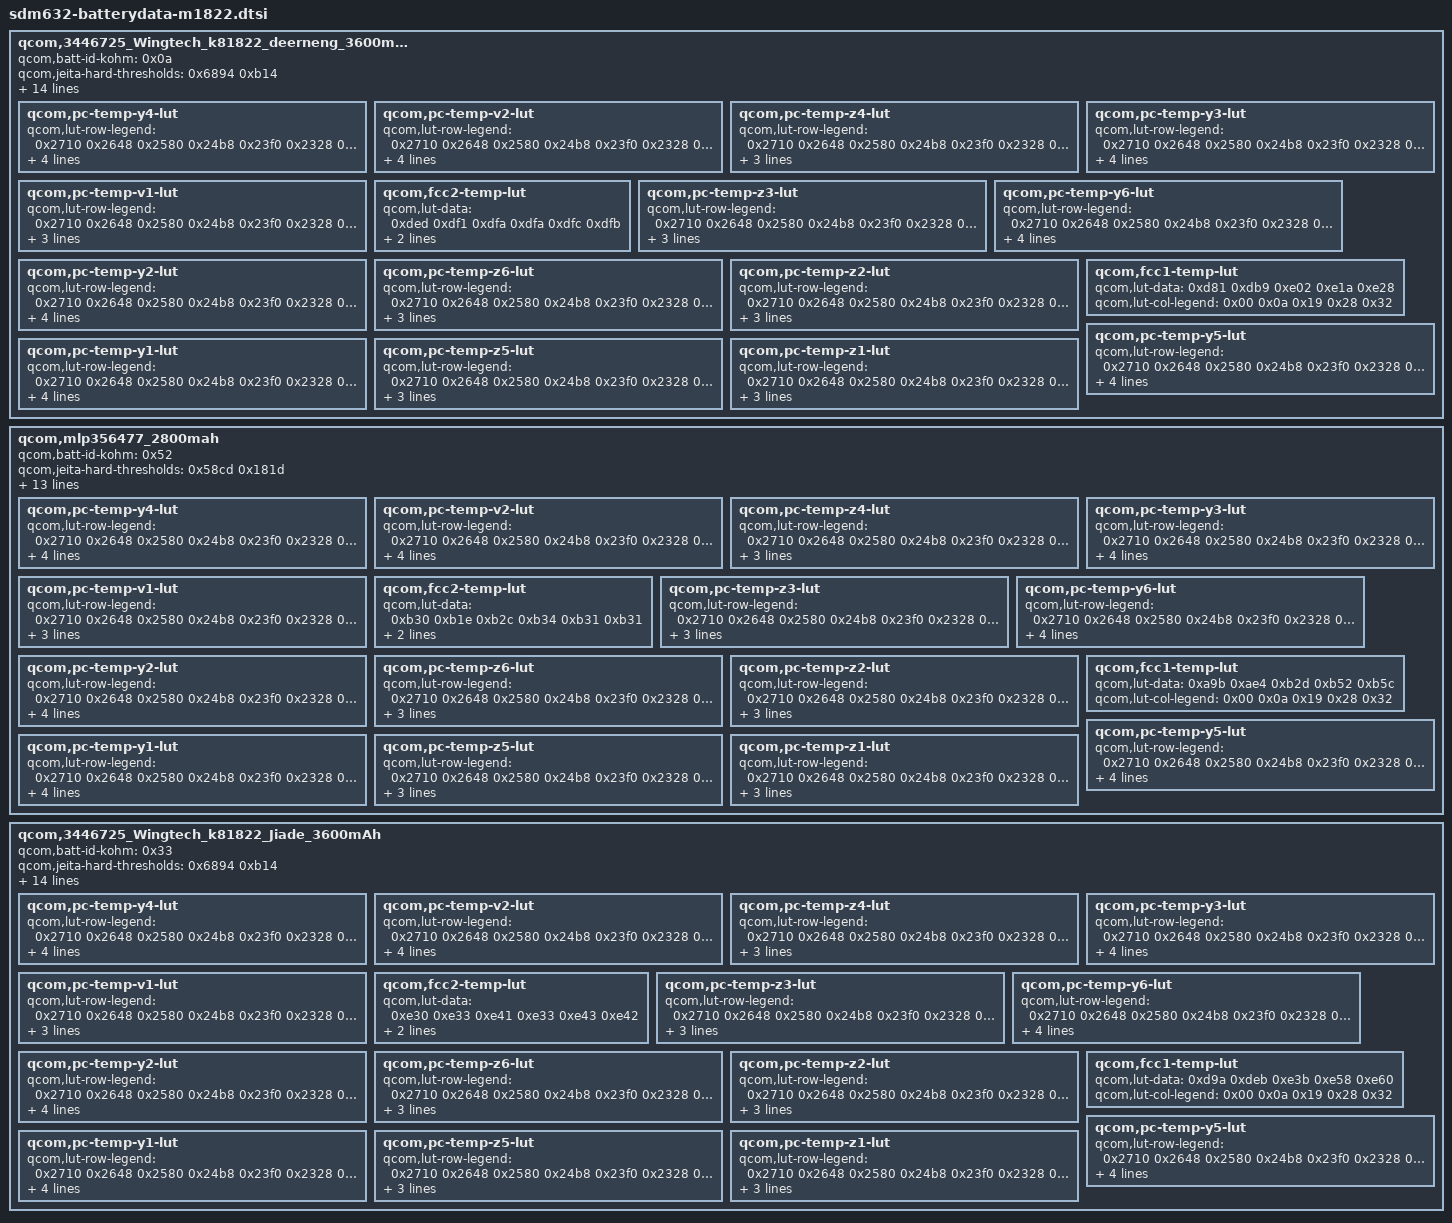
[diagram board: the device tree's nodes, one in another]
/* Copyright (c) 2021, MeizuCustoms
 *
 * This program is free software; you can redistribute it and/or modify
 * it under the terms of the GNU General Public License version 2 and
 * only version 2 as published by the Free Software Foundation.
 *
 * This program is distributed in the hope that it will be useful,
 * but WITHOUT ANY WARRANTY; without even the implied warranty of
 * MERCHANTABILITY or FITNESS FOR A PARTICULAR PURPOSE.  See the
 * GNU General Public License for more details.
 */

qcom,3446725_Wingtech_k81822_deerneng_3600mAh {
    qcom,batt-id-kohm = <0x0a>;
    qcom,jeita-hard-thresholds = <0x6894 0xb14>;
    qcom,step-chg-ranges = <0x33e140 0x401640 0x2625a0 0x401a28 0x419ce0 0x1b7740 0x41a0c8 0x432380 0x124f80>;
    qcom,fastchg-current-ma = <0xe10>;
    qcom,max-voltage-uv = <0x432380>;
    qcom,qg-batt-profile-ver = <0x64>;
    qcom,battery-therm-kohm = <0x64>;
    qcom,battery-beta = <0x109a>;
    qcom,jeita-fcc-ranges = <0x00 0x64 0xafc80 0x65 0x96 0x107ac0 0x97 0x1c2 0x2625a0>;
    qcom,battery-type = "k81822_mtp_deerneng_4V4_3600mAh";
    qcom,fg-cc-cv-threshold-uv = <0x42fc70>;
    qcom,jeita-fv-ranges = <0x00 0x64 0x432380 0x65 0x1c2 0x432380 0x1c3 0x226 0x432380>;

    qcom,pc-temp-y4-lut {
        qcom,lut-row-legend = <0x2710 0x2648 0x2580 0x24b8 0x23f0 0x2328 0x2260 0x2198 0x20d0 0x2008 0x1f40 0x1e78 0x1db0 0x1ce8 0x1c20 0x1b58 0x1a90 0x19c8 0x1900 0x1838 0x1770 0x16a8 0x15e0 0x1518 0x1450 0x1388 0x12c0 0x11f8 0x1130 0x1068 0xfa0 0xed8 0xe10 0xd48 0xc80 0xbb8 0xaf0 0xa28 0x960 0x898 0x7d0 0x708 0x640 0x578 0x4b0 0x3e8 0x384 0x320 0x2bc 0x258 0x1f4 0x190 0x12c 0xc8 0x64 0x00>;
        qcom,lut-data = <0x4242 0x4165 0x40fc 0x407f 0x405c 0x404e 0x4267 0x419b 0x410f 0x407f 0x4058 0x404d 0x429d 0x41dc 0x4120 0x407e 0x4055 0x404b 0x42d5 0x421b 0x412e 0x407e 0x4054 0x404b 0x4302 0x424b 0x4137 0x407e 0x4053 0x404a 0x4316 0x425f 0x413b 0x407f 0x4052 0x404a 0x4312 0x4259 0x4137 0x4080 0x4053 0x404a 0x430a 0x424b 0x4130 0x4083 0x4055 0x404b 0x4308 0x423d 0x412e 0x4087 0x4056 0x404c 0x431a 0x422a 0x412e 0x408f 0x405a 0x404e 0x433b 0x421f 0x412e 0x4098 0x405e 0x4050 0x43b7 0x4261 0x4133 0x409e 0x4064 0x4054 0x4470 0x42df 0x4140 0x40a4 0x406b 0x4058 0x4483 0x42fe 0x4156 0x40ac 0x4070 0x405e 0x438b 0x42e1 0x4190 0x40ba 0x4074 0x4065 0x4292 0x42bc 0x41b7 0x40cc 0x4079 0x406d 0x423b 0x428c 0x41b7 0x40e4 0x4085 0x4073 0x4201 0x4243 0x41b4 0x4100 0x4099 0x4079 0x41d9 0x420c 0x41ab 0x4116 0x40af 0x4085 0x41b6 0x41dc 0x417e 0x4129 0x40cb 0x40a0 0x4197 0x41aa 0x4146 0x4133 0x40dc 0x40b2 0x4178 0x4176 0x4112 0x4108 0x40c2 0x40a0 0x4157 0x4142 0x40df 0x40ae 0x408b 0x407a 0x4154 0x4115 0x40c4 0x4086 0x406e 0x4063 0x4184 0x40e8 0x40b5 0x4077 0x405f 0x4056 0x41ae 0x40cc 0x40ab 0x4070 0x4058 0x404f 0x41af 0x40e8 0x40a7 0x4073 0x405a 0x4051 0x41ae 0x412f 0x40a4 0x4079 0x4062 0x4055 0x41ac 0x4151 0x40a0 0x407f 0x406a 0x405b 0x41a7 0x4159 0x409d 0x4086 0x4074 0x4066 0x41a3 0x415d 0x4099 0x408d 0x407f 0x4073 0x41a0 0x4153 0x4094 0x4095 0x408b 0x4080 0x41a0 0x412f 0x4090 0x409d 0x4097 0x408c 0x41a1 0x411a 0x408f 0x40a1 0x409a 0x4090 0x41a6 0x4123 0x4097 0x40a2 0x4097 0x408c 0x41ab 0x4138 0x40a3 0x40a2 0x4091 0x4086 0x41ae 0x414a 0x40b2 0x409d 0x4082 0x4078 0x41b1 0x4160 0x40c4 0x408e 0x406b 0x4063 0x41b1 0x4167 0x40d1 0x4086 0x4063 0x405c 0x41a7 0x4166 0x40da 0x4083 0x4064 0x405c 0x4196 0x4162 0x40df 0x4082 0x4066 0x405d 0x418b 0x415a 0x40dd 0x4085 0x4067 0x405c 0x4184 0x4148 0x40d8 0x408a 0x4066 0x405a 0x4186 0x4137 0x40cb 0x4083 0x4059 0x404f 0x4195 0x412f 0x40c1 0x407d 0x4050 0x4047 0x41b0 0x4136 0x40c8 0x4082 0x405b 0x4053 0x419f 0x4139 0x40ce 0x4086 0x4067 0x4065 0x41b0 0x414c 0x40e7 0x4098 0x4078 0x4081 0x41c9 0x4171 0x4105 0x40ad 0x4095 0x409e 0x41cc 0x4195 0x4127 0x40bf 0x4095 0x4082 0x41b6 0x418c 0x4116 0x4091 0x405b 0x404e 0x41a5 0x416e 0x4122 0x4090 0x405b 0x4051 0x41b6 0x416e 0x413b 0x40af 0x406a 0x405d 0x423b 0x417e 0x416a 0x40f5 0x40a0 0x40a3 0x423b 0x417e 0x416a 0x40f5 0x40a0 0x40a3 0x423b 0x417e 0x416a 0x40f5 0x40a0 0x40a3>;
        qcom,lut-col-legend = <0xfffffff6 0x00 0x0a 0x19 0x28 0x32>;
    };

    qcom,pc-temp-v2-lut {
        qcom,lut-row-legend = <0x2710 0x2648 0x2580 0x24b8 0x23f0 0x2328 0x2260 0x2198 0x20d0 0x2008 0x1f40 0x1e78 0x1db0 0x1ce8 0x1c20 0x1b58 0x1a90 0x19c8 0x1900 0x1838 0x1770 0x16a8 0x15e0 0x1518 0x1450 0x1388 0x12c0 0x11f8 0x1130 0x1068 0xfa0 0xed8 0xe10 0xd48 0xc80 0xbb8 0xaf0 0xa28 0x960 0x898 0x7d0 0x708 0x640 0x578 0x4b0 0x3e8 0x384 0x320 0x2bc 0x258 0x1f4 0x190 0x12c 0xc8 0x64 0x00>;
        qcom,lut-data = <0xab86 0xab6d 0xab59 0xab2c 0xab13 0xab04 0xaa0f 0xaa35 0xaa4c 0xaa1f 0xaa13 0xaa07 0xa8bd 0xa910 0xa946 0xa91b 0xa919 0xa910 0xa798 0xa802 0xa84b 0xa822 0xa826 0xa820 0xa69a 0xa70a 0xa758 0xa734 0xa73b 0xa737 0xa5a8 0xa618 0xa668 0xa648 0xa651 0xa64e 0xa4b6 0xa51f 0xa578 0xa55c 0xa567 0xa565 0xa3c7 0xa429 0xa48a 0xa472 0xa47d 0xa47b 0xa2cb 0xa343 0xa3a1 0xa38b 0xa396 0xa395 0xa1ae 0xa26c 0xa2bc 0xa2a6 0xa2b2 0xa2b1 0xa0ce 0xa199 0xa1da 0xa1c4 0xa1d0 0xa1d0 0xa063 0xa0c0 0xa0fd 0xa0e8 0xa0f4 0xa0f4 0xa014 0x9fe8 0xa023 0xa010 0xa01a 0xa01a 0x9f7f 0x9f1e 0x9f55 0x9f41 0x9f4a 0x9f49 0x9e2a 0x9e63 0x9e8f 0x9e76 0x9e7e 0x9e7c 0x9cba 0x9da0 0x9dcf 0x9db2 0x9dba 0x9db6 0x9bb1 0x9cc0 0x9d13 0x9cf2 0x9cfc 0x9cfa 0x9ac9 0x9bd0 0x9c59 0x9c3a 0x9c45 0x9c45 0x99f6 0x9aec 0x9b8f 0x9b8d 0x9b96 0x9b96 0x9933 0x9a0e 0x9ab0 0x9af4 0x9af5 0x9af4 0x9879 0x9937 0x99d2 0x9a4c 0x9a49 0x9a47 0x97b8 0x986d 0x98fe 0x9968 0x996c 0x996c 0x96fa 0x97af 0x9834 0x9866 0x987a 0x987d 0x9661 0x9706 0x9788 0x97a0 0x97b9 0x97bd 0x95e6 0x966c 0x96f6 0x9709 0x971e 0x9724 0x9582 0x95e5 0x9675 0x9688 0x969a 0x969f 0x9539 0x956f 0x9600 0x9617 0x9627 0x962b 0x94ff 0x9508 0x9596 0x95b3 0x95c1 0x95c5 0x94ca 0x94bd 0x9536 0x9557 0x9565 0x9567 0x949b 0x9488 0x94dd 0x9501 0x9510 0x950e 0x946d 0x945c 0x948c 0x94b3 0x94c3 0x94be 0x943d 0x9430 0x9441 0x946a 0x947d 0x9477 0x940c 0x9408 0x93fd 0x9428 0x943d 0x9435 0x93d9 0x93df 0x93c7 0x93ea 0x93fa 0x93f0 0x93a5 0x93b4 0x93a1 0x93b4 0x93b4 0x93a6 0x936f 0x9389 0x937c 0x937d 0x9369 0x9353 0x9334 0x935a 0x9357 0x9340 0x9311 0x92f0 0x92f7 0x9329 0x9331 0x92ff 0x92af 0x927e 0x92b0 0x92ec 0x92ff 0x92b7 0x9254 0x9219 0x925b 0x929e 0x92b6 0x9268 0x9205 0x91c6 0x91fc 0x9240 0x925a 0x920f 0x91b1 0x9171 0x9196 0x91d0 0x91e6 0x91a4 0x9149 0x9108 0x912a 0x914a 0x915b 0x9126 0x90d0 0x908f 0x90d1 0x90c2 0x90c5 0x9092 0x9044 0x9004 0x9085 0x9044 0x9048 0x901f 0x8fde 0x8fa3 0x903b 0x8ff6 0x9002 0x8ff6 0x8fbc 0x8f87 0x9019 0x8fdb 0x8fef 0x8fe7 0x8fac 0x8f77 0x8feb 0x8fbb 0x8fd3 0x8fd3 0x8f9c 0x8f67 0x8fa3 0x8f86 0x8fad 0x8fb0 0x8f7a 0x8f40 0x8f04 0x8f1c 0x8f49 0x8f4a 0x8f01 0x8e9f 0x8dc4 0x8e16 0x8e1e 0x8e05 0x8d92 0x8d18 0x8bcb 0x8c3d 0x8c0b 0x8c05 0x8b91 0x8b0c 0x891d 0x899f 0x8970 0x897d 0x88fb 0x885c 0x8589 0x85e4 0x85ce 0x860e 0x856c 0x84b8 0x8047 0x80cd 0x80af 0x80d5 0x804e 0x7f84 0x6be0 0x6af3 0x6da1 0x6c3e 0x6e30 0x6c8f>;
        qcom,lut-col-legend = <0xfffffff6 0x00 0x0a 0x19 0x28 0x32>;
    };

    qcom,pc-temp-z4-lut {
        qcom,lut-row-legend = <0x2710 0x2648 0x2580 0x24b8 0x23f0 0x2328 0x2260 0x2198 0x20d0 0x2008 0x1f40 0x1e78 0x1db0 0x1ce8 0x1c20 0x1b58 0x1a90 0x19c8 0x1900 0x1838 0x1770 0x16a8 0x15e0 0x1518 0x1450 0x1388 0x12c0 0x11f8 0x1130 0x1068 0xfa0 0xed8 0xe10 0xd48 0xc80 0xbb8 0xaf0 0xa28 0x960 0x898 0x7d0 0x708 0x640 0x578 0x4b0 0x3e8 0x384 0x320 0x2bc 0x258 0x1f4 0x190 0x12c 0xc8 0x64 0x00>;
        qcom,lut-data = <0x3de7 0x3c92 0x3b14 0x3a86 0x3a1d 0x3e4f 0x3cb5 0x3b3e 0x3a8d 0x3a51 0x3dc2 0x3c83 0x3b28 0x3a7a 0x3a41 0x3d09 0x3be4 0x3afd 0x3a5f 0x3a2c 0x3c75 0x3b54 0x3ab2 0x3a35 0x3a0c 0x3be7 0x3afa 0x3a73 0x3a0c 0x39ea 0x3b7c 0x3ab1 0x3a44 0x39ee 0x39ce 0x3b2e 0x3a78 0x3a1d 0x39d3 0x39b6 0x3aef 0x3a4b 0x39fd 0x39be 0x39a5 0x3ab9 0x3a25 0x39e4 0x39af 0x399a 0x3a89 0x3a06 0x39d2 0x39a4 0x3992 0x3a67 0x39ed 0x39c6 0x399e 0x398f 0x3a52 0x39d7 0x39bb 0x399a 0x398c 0x3a42 0x39be 0x39b0 0x3993 0x3989 0x3a30 0x39ac 0x39a5 0x3984 0x397f 0x3a18 0x39ad 0x399c 0x3978 0x3974 0x3a06 0x39b6 0x3994 0x3975 0x396d 0x3a00 0x39b7 0x398c 0x3974 0x3968 0x39fe 0x39a7 0x3983 0x3970 0x3962 0x39f9 0x3998 0x397b 0x3969 0x395b 0x39e0 0x399a 0x3978 0x3964 0x3956 0x39c5 0x39a5 0x3999 0x397e 0x396d 0x39ca 0x39b8 0x39d6 0x39c1 0x39b1 0x39f0 0x3a09 0x3a09 0x39f3 0x39e4 0x3a15 0x3a61 0x3a3d 0x3a1c 0x3a08 0x3a2f 0x3a68 0x3a52 0x3a30 0x3a1b 0x3a44 0x3a55 0x3a4d 0x3a29 0x39fd 0x3a46 0x3a3d 0x3a40 0x3a13 0x39b0 0x3a35 0x3a26 0x3a2a 0x39f1 0x3987 0x3a1e 0x3a0d 0x39fa 0x39af 0x3979 0x3a0d 0x39f4 0x39cf 0x397f 0x3970 0x39fb 0x39d9 0x39b2 0x3978 0x3969 0x39ea 0x39c4 0x399c 0x3974 0x3964 0x39db 0x39b7 0x3995 0x3971 0x3963 0x39cd 0x39ad 0x3991 0x396f 0x3963 0x39c0 0x39a5 0x3990 0x396e 0x3963 0x39b5 0x399e 0x3990 0x3970 0x3966 0x39ac 0x399a 0x3990 0x3975 0x396c 0x39a7 0x399d 0x3994 0x397c 0x3974 0x39a2 0x39a7 0x39a4 0x398a 0x397e 0x39a1 0x39aa 0x39af 0x3993 0x3984 0x39a0 0x399e 0x39a4 0x398c 0x3979 0x39a0 0x3994 0x3998 0x3983 0x396b 0x399f 0x3990 0x3995 0x3985 0x3971 0x3994 0x397b 0x3983 0x397d 0x396d 0x39c4 0x396d 0x396a 0x396c 0x3961 0x3a15 0x396d 0x3964 0x3960 0x395a 0x3a3e 0x397e 0x395a 0x3950 0x3946 0x3a41 0x39a2 0x3951 0x393b 0x3938 0x3a3f 0x3980 0x395c 0x3946 0x393c 0x3a34 0x39aa 0x399b 0x3954 0x3941 0x3a46 0x39c9 0x39a8 0x3953 0x393e 0x3a4e 0x39f3 0x399f 0x395a 0x3940 0x3a59 0x39fc 0x39a8 0x3956 0x3942 0x3a59 0x39fc 0x39a8 0x3956 0x3942 0x3a59 0x39fc 0x39a8 0x3956 0x3942>;
        qcom,lut-col-legend = <0x00 0x0a 0x19 0x28 0x32>;
    };

    qcom,pc-temp-y3-lut {
        qcom,lut-row-legend = <0x2710 0x2648 0x2580 0x24b8 0x23f0 0x2328 0x2260 0x2198 0x20d0 0x2008 0x1f40 0x1e78 0x1db0 0x1ce8 0x1c20 0x1b58 0x1a90 0x19c8 0x1900 0x1838 0x1770 0x16a8 0x15e0 0x1518 0x1450 0x1388 0x12c0 0x11f8 0x1130 0x1068 0xfa0 0xed8 0xe10 0xd48 0xc80 0xbb8 0xaf0 0xa28 0x960 0x898 0x7d0 0x708 0x640 0x578 0x4b0 0x3e8 0x384 0x320 0x2bc 0x258 0x1f4 0x190 0x12c 0xc8 0x64 0x00>;
        qcom,lut-data = <0x356d 0x3495 0x341f 0x33ef 0x33df 0x33df 0x356b 0x3497 0x3423 0x33f0 0x33e1 0x33df 0x3566 0x349a 0x3428 0x33f2 0x33e2 0x33e0 0x355e 0x349c 0x342c 0x33f3 0x33e4 0x33e1 0x3555 0x349d 0x3430 0x33f5 0x33e5 0x33e1 0x354b 0x349e 0x3433 0x33f6 0x33e7 0x33e2 0x3540 0x349d 0x3435 0x33f8 0x33e8 0x33e4 0x3532 0x349d 0x3436 0x33f9 0x33e9 0x33e5 0x351f 0x349f 0x3437 0x33fa 0x33eb 0x33e6 0x34f8 0x34b0 0x3439 0x33f9 0x33ec 0x33e8 0x34d6 0x34bc 0x343b 0x33f9 0x33ed 0x33e9 0x34bf 0x34a1 0x343a 0x33fb 0x33ee 0x33ea 0x34a8 0x346d 0x3438 0x33fe 0x33ee 0x33eb 0x34a5 0x3460 0x3435 0x33ff 0x33f0 0x33eb 0x34ad 0x346b 0x342d 0x3400 0x33f4 0x33eb 0x34b3 0x3475 0x3428 0x3400 0x33f6 0x33ec 0x34ab 0x3472 0x342a 0x33fe 0x33f5 0x33ee 0x3497 0x3469 0x342d 0x33fb 0x33f3 0x33f1 0x3489 0x3460 0x342e 0x33fb 0x33f2 0x33f1 0x3480 0x3456 0x3428 0x33fe 0x33f2 0x33f1 0x3479 0x344b 0x3421 0x3401 0x33f2 0x33ef 0x3472 0x3443 0x341c 0x33fe 0x33ef 0x33eb 0x346b 0x343d 0x3417 0x33f6 0x33e9 0x33e4 0x345d 0x3438 0x3414 0x33f2 0x33e5 0x33e1 0x3432 0x3435 0x3412 0x33f0 0x33e3 0x33e0 0x340e 0x3431 0x3411 0x33ef 0x33e2 0x33e0 0x340f 0x3416 0x3410 0x33ee 0x33e1 0x33e0 0x3419 0x33e0 0x340e 0x33ee 0x33e1 0x33e0 0x3426 0x33cd 0x340d 0x33ef 0x33e0 0x33e0 0x3438 0x33cd 0x340c 0x33ef 0x33e1 0x33de 0x3450 0x33ce 0x340c 0x33ef 0x33e1 0x33dd 0x346b 0x33d6 0x340a 0x33ef 0x33e2 0x33dd 0x348c 0x33ee 0x3408 0x33ef 0x33e3 0x33de 0x34ad 0x3401 0x3407 0x33ef 0x33e4 0x33df 0x34cf 0x3416 0x3408 0x33f0 0x33e4 0x33e1 0x34f3 0x3427 0x340a 0x33f0 0x33e4 0x33e2 0x351c 0x342f 0x340c 0x33f0 0x33e3 0x33e1 0x354a 0x343a 0x340f 0x33f0 0x33e1 0x33df 0x3576 0x344b 0x3411 0x33ef 0x33e0 0x33de 0x35a1 0x3468 0x3412 0x33ee 0x33e1 0x33df 0x35c8 0x348e 0x3413 0x33ed 0x33e1 0x33e0 0x35eb 0x34b7 0x3413 0x33ee 0x33e1 0x33e1 0x360a 0x34e5 0x3414 0x33ef 0x33e2 0x33e2 0x3635 0x3518 0x3417 0x33f0 0x33e2 0x33df 0x3669 0x354c 0x341b 0x33f0 0x33e3 0x33de 0x368f 0x356a 0x341b 0x33f8 0x33e7 0x33e6 0x367d 0x3557 0x341f 0x33f9 0x33e9 0x33e7 0x36a9 0x3586 0x3424 0x33fe 0x33f0 0x33eb 0x36eb 0x35ae 0x3430 0x3406 0x33f4 0x33ee 0x372c 0x35e3 0x343a 0x3409 0x33f3 0x33ea 0x3779 0x360c 0x343b 0x3405 0x33ea 0x33e8 0x37e6 0x364d 0x3437 0x3404 0x33ec 0x33ea 0x3878 0x36bc 0x3464 0x340d 0x33f3 0x33ed 0x3993 0x373d 0x34a6 0x3417 0x33f9 0x33f3 0x3993 0x373d 0x34a6 0x3417 0x33f9 0x33f3 0x3993 0x373d 0x34a6 0x3417 0x33f9 0x33f3>;
        qcom,lut-col-legend = <0xfffffff6 0x00 0x0a 0x19 0x28 0x32>;
    };

    qcom,pc-temp-v1-lut {
        qcom,lut-row-legend = <0x2710 0x2648 0x2580 0x24b8 0x23f0 0x2328 0x2260 0x2198 0x20d0 0x2008 0x1f40 0x1e78 0x1db0 0x1ce8 0x1c20 0x1b58 0x1a90 0x19c8 0x1900 0x1838 0x1770 0x16a8 0x15e0 0x1518 0x1450 0x1388 0x12c0 0x11f8 0x1130 0x1068 0xfa0 0xed8 0xe10 0xd48 0xc80 0xbb8 0xaf0 0xa28 0x960 0x898 0x7d0 0x708 0x640 0x578 0x4b0 0x3e8 0x384 0x320 0x2bc 0x258 0x1f4 0x190 0x12c 0xc8 0x64 0x00>;
        qcom,lut-data = <0xaa9a 0xaafb 0xab4a 0xab63 0xab6e 0xa9af 0xaa0f 0xaa7d 0xaa8e 0xaa9e 0xa8b6 0xa925 0xa992 0xa9b1 0xa9c4 0xa7c0 0xa839 0xa8a9 0xa8d0 0xa8e5 0xa6d3 0xa74f 0xa7c0 0xa7ea 0xa803 0xa5eb 0xa664 0xa6d4 0xa702 0xa71d 0xa506 0xa57a 0xa5e8 0xa61a 0xa636 0xa427 0xa495 0xa4fc 0xa530 0xa54d 0xa34b 0xa3b3 0xa413 0xa447 0xa465 0xa275 0xa2d5 0xa32d 0xa35e 0xa37c 0xa1a3 0xa1fa 0xa24a 0xa278 0xa296 0xa0da 0xa125 0xa16c 0xa199 0xa1b6 0xa021 0xa05e 0xa092 0xa0bf 0xa0db 0x9f6d 0x9fa8 0x9fc2 0x9feb 0xa006 0x9e9e 0x9eee 0x9ef9 0x9f19 0x9f33 0x9da8 0x9e17 0x9e36 0x9e50 0x9e68 0x9cc5 0x9d32 0x9d74 0x9d91 0x9da7 0x9c26 0x9c76 0x9cba 0x9cdc 0x9cee 0x9ba3 0x9be7 0x9c12 0x9c2f 0x9c3e 0x9b1d 0x9b5f 0x9b7c 0x9b91 0x9b9b 0x9a96 0x9aba 0x9ad2 0x9ae8 0x9af3 0x9a04 0x9a02 0x99e9 0x9a07 0x9a21 0x9950 0x993a 0x98ee 0x9909 0x9930 0x9875 0x9845 0x9829 0x9845 0x9869 0x97b7 0x9767 0x9786 0x97b3 0x97d0 0x9727 0x96f9 0x970b 0x973a 0x974e 0x96b1 0x96b8 0x96b5 0x96d1 0x96d9 0x9662 0x967f 0x966e 0x9673 0x966f 0x962c 0x9644 0x9622 0x9616 0x960e 0x9600 0x960b 0x95d5 0x95b7 0x95b2 0x95d8 0x95d5 0x958f 0x9564 0x9560 0x95b5 0x95a0 0x954e 0x9520 0x9516 0x9594 0x956f 0x9513 0x94e5 0x94d3 0x9573 0x9544 0x94e0 0x94aa 0x9493 0x9554 0x951c 0x94b4 0x9473 0x9459 0x9536 0x94f7 0x9489 0x943d 0x9420 0x951c 0x94d7 0x9463 0x940b 0x93e4 0x94f9 0x94b2 0x943a 0x93d8 0x93a6 0x94bb 0x9472 0x93fe 0x9394 0x935a 0x9461 0x9412 0x93a4 0x933a 0x92fd 0x93f9 0x93a6 0x933b 0x92d1 0x9292 0x9376 0x932b 0x92c3 0x925c 0x9218 0x92e2 0x929f 0x923a 0x91d6 0x918e 0x9239 0x91f7 0x9196 0x9134 0x90ee 0x91a8 0x9166 0x910a 0x90af 0x906f 0x914d 0x910c 0x90b3 0x905d 0x9025 0x9131 0x90f2 0x909d 0x9048 0x9010 0x9118 0x90df 0x908d 0x903a 0x9001 0x90fd 0x90c8 0x907a 0x9025 0x8fed 0x90c5 0x9090 0x903c 0x8fdd 0x8f95 0x8fcc 0x8f92 0x8f28 0x8eb5 0x8e54 0x8dfd 0x8dcb 0x8d63 0x8cf1 0x8c8b 0x8bab 0x8b7e 0x8b11 0x8aa4 0x8a37 0x887c 0x8854 0x87e2 0x877b 0x8706 0x8365 0x8354 0x82db 0x8289 0x8200 0x7530 0x7530 0x7530 0x7530 0x7530>;
        qcom,lut-col-legend = <0x00 0x0a 0x19 0x28 0x32>;
    };

    qcom,fcc2-temp-lut {
        qcom,lut-data = <0xded 0xdf1 0xdfa 0xdfa 0xdfc 0xdfb>;
        qcom,lut-col-legend = <0xfffffff6 0x00 0x0a 0x19 0x28 0x32>;
    };

    qcom,pc-temp-z3-lut {
        qcom,lut-row-legend = <0x2710 0x2648 0x2580 0x24b8 0x23f0 0x2328 0x2260 0x2198 0x20d0 0x2008 0x1f40 0x1e78 0x1db0 0x1ce8 0x1c20 0x1b58 0x1a90 0x19c8 0x1900 0x1838 0x1770 0x16a8 0x15e0 0x1518 0x1450 0x1388 0x12c0 0x11f8 0x1130 0x1068 0xfa0 0xed8 0xe10 0xd48 0xc80 0xbb8 0xaf0 0xa28 0x960 0x898 0x7d0 0x708 0x640 0x578 0x4b0 0x3e8 0x384 0x320 0x2bc 0x258 0x1f4 0x190 0x12c 0xc8 0x64 0x00>;
        qcom,lut-data = <0x4c1d 0x4bcd 0x4b9e 0x4b88 0x4b86 0x4cf7 0x4c6d 0x4bda 0x4bb0 0x4b9d 0x4d46 0x4ca4 0x4c19 0x4bd6 0x4bb7 0x4d70 0x4cbe 0x4c2f 0x4bec 0x4bcf 0x4d81 0x4cca 0x4c38 0x4bf8 0x4bdb 0x4d8b 0x4cd0 0x4c3b 0x4bfd 0x4be2 0x4d8d 0x4cd4 0x4c3c 0x4bfb 0x4be0 0x4d85 0x4cd3 0x4c3d 0x4bf5 0x4bdb 0x4d7a 0x4ccc 0x4c39 0x4bef 0x4bd6 0x4d74 0x4cc4 0x4c2a 0x4beb 0x4bd4 0x4d72 0x4cba 0x4c1c 0x4be5 0x4bd1 0x4d6d 0x4cac 0x4c14 0x4bdc 0x4bca 0x4d50 0x4c9e 0x4c0d 0x4bcf 0x4bbe 0x4d27 0x4c90 0x4c06 0x4bc9 0x4bb7 0x4d1f 0x4c88 0x4bfd 0x4bc7 0x4bb4 0x4d26 0x4c85 0x4bf4 0x4bc5 0x4bb1 0x4d2c 0x4c82 0x4bef 0x4bbd 0x4bac 0x4d1b 0x4c7c 0x4bea 0x4baf 0x4ba4 0x4cf2 0x4c6f 0x4be5 0x4ba6 0x4b9e 0x4ce1 0x4c64 0x4bdf 0x4ba2 0x4b99 0x4ce7 0x4c67 0x4bdd 0x4ba0 0x4b97 0x4cf2 0x4c77 0x4bee 0x4ba9 0x4b99 0x4d04 0x4c81 0x4c06 0x4bbb 0x4b9e 0x4d25 0x4c82 0x4c05 0x4bbc 0x4b9e 0x4d38 0x4c82 0x4bf3 0x4ba3 0x4b8b 0x4d36 0x4c7e 0x4be1 0x4b8d 0x4b79 0x4d32 0x4c71 0x4bd4 0x4b8c 0x4b8f 0x4d2d 0x4c6b 0x4bca 0x4b8f 0x4bc4 0x4d25 0x4c6b 0x4bce 0x4b9b 0x4bd5 0x4d1c 0x4c6b 0x4bea 0x4bc8 0x4bd2 0x4d13 0x4c6d 0x4c00 0x4be7 0x4bcc 0x4d08 0x4c76 0x4c09 0x4bdf 0x4bc4 0x4d00 0x4c7c 0x4c0e 0x4bce 0x4bb8 0x4cfb 0x4c7b 0x4c0c 0x4bc3 0x4baf 0x4cf6 0x4c78 0x4c01 0x4bbd 0x4ba6 0x4cef 0x4c75 0x4bf6 0x4bb7 0x4ba0 0x4ce4 0x4c6f 0x4bef 0x4bb2 0x4b9c 0x4cdb 0x4c68 0x4bea 0x4bae 0x4b99 0x4cd6 0x4c63 0x4be4 0x4bab 0x4b97 0x4cd2 0x4c5d 0x4bdf 0x4ba8 0x4b97 0x4cca 0x4c57 0x4bdb 0x4ba7 0x4b97 0x4cbd 0x4c50 0x4bda 0x4ba7 0x4b9e 0x4cac 0x4c47 0x4bd9 0x4ba7 0x4ba6 0x4c92 0x4c39 0x4bd4 0x4ba8 0x4ba5 0x4c3d 0x4c0e 0x4bc5 0x4ba0 0x4b9d 0x4beb 0x4bf8 0x4bbd 0x4b95 0x4b8d 0x4b9a 0x4bea 0x4bb2 0x4b91 0x4b85 0x4b70 0x4bcd 0x4ba5 0x4b87 0x4b81 0x4b65 0x4ba5 0x4b9b 0x4b84 0x4b77 0x4b61 0x4bc0 0x4b95 0x4b7c 0x4b76 0x4b73 0x4bab 0x4b7b 0x4b96 0x4b9a 0x4b73 0x4b98 0x4b77 0x4b9c 0x4ba1 0x4b75 0x4b79 0x4b82 0x4b98 0x4ba2 0x4b78 0x4b79 0x4b7e 0x4b9f 0x4ba4 0x4b78 0x4b79 0x4b7e 0x4b9f 0x4ba4 0x4b78 0x4b79 0x4b7e 0x4b9f 0x4ba4>;
        qcom,lut-col-legend = <0x00 0x0a 0x19 0x28 0x32>;
    };

    qcom,pc-temp-y6-lut {
        qcom,lut-row-legend = <0x2710 0x2648 0x2580 0x24b8 0x23f0 0x2328 0x2260 0x2198 0x20d0 0x2008 0x1f40 0x1e78 0x1db0 0x1ce8 0x1c20 0x1b58 0x1a90 0x19c8 0x1900 0x1838 0x1770 0x16a8 0x15e0 0x1518 0x1450 0x1388 0x12c0 0x11f8 0x1130 0x1068 0xfa0 0xed8 0xe10 0xd48 0xc80 0xbb8 0xaf0 0xa28 0x960 0x898 0x7d0 0x708 0x640 0x578 0x4b0 0x3e8 0x384 0x320 0x2bc 0x258 0x1f4 0x190 0x12c 0xc8 0x64 0x00>;
        qcom,lut-data = <0x18ac 0x15e9 0x1486 0x13c9 0x1399 0x138f 0x1898 0x15ec 0x1488 0x13c8 0x1399 0x138f 0x1882 0x15ed 0x1489 0x13c8 0x1399 0x138f 0x1868 0x15ed 0x1489 0x13c8 0x139a 0x1390 0x184c 0x15ed 0x148a 0x13c9 0x139b 0x1390 0x182e 0x15ec 0x148a 0x13c9 0x139c 0x1391 0x180c 0x15e4 0x1487 0x13ca 0x139d 0x1392 0x17e8 0x15d7 0x1482 0x13cc 0x139e 0x1393 0x17c4 0x15d1 0x147f 0x13cd 0x13a0 0x1395 0x179a 0x15cf 0x147d 0x13cf 0x13a2 0x1396 0x1782 0x15cd 0x147b 0x13d1 0x13a3 0x1398 0x178e 0x15c9 0x147b 0x13d4 0x13a6 0x139a 0x17a5 0x15c5 0x147a 0x13d7 0x13a8 0x139c 0x17a5 0x15c3 0x147b 0x13db 0x13ab 0x139e 0x1769 0x15c3 0x1484 0x13df 0x13ae 0x13a0 0x1727 0x15c0 0x148b 0x13e4 0x13b1 0x13a2 0x1709 0x15b4 0x148d 0x13e9 0x13b5 0x13a6 0x16f2 0x159e 0x148f 0x13ef 0x13b8 0x13a9 0x16e3 0x158b 0x148d 0x13f5 0x13be 0x13ad 0x16d9 0x1578 0x147b 0x13fd 0x13c6 0x13b4 0x16cf 0x1566 0x1466 0x1402 0x13cb 0x13b8 0x16bf 0x1555 0x1454 0x13f3 0x13c1 0x13b0 0x16ad 0x1547 0x1443 0x13d4 0x13ac 0x13a0 0x16a6 0x153f 0x143b 0x13c6 0x13a1 0x1397 0x16a7 0x1539 0x1437 0x13c1 0x139b 0x1392 0x16aa 0x1536 0x1435 0x13bf 0x1398 0x1390 0x16b2 0x1537 0x1435 0x13c0 0x1399 0x1390 0x16c3 0x153b 0x1436 0x13c2 0x139b 0x1392 0x16d6 0x1542 0x1436 0x13c5 0x139d 0x1394 0x16ec 0x1551 0x1438 0x13c8 0x13a1 0x1396 0x1706 0x1565 0x143a 0x13cb 0x13a5 0x1399 0x1723 0x157b 0x143b 0x13ce 0x13a9 0x139d 0x1745 0x1596 0x143d 0x13d1 0x13ae 0x13a1 0x176a 0x15b5 0x1440 0x13d4 0x13af 0x13a3 0x1792 0x15db 0x1447 0x13d6 0x13ae 0x13a3 0x17bd 0x1605 0x1451 0x13d7 0x13ae 0x13a3 0x17e7 0x1635 0x145e 0x13d6 0x13a9 0x139f 0x1812 0x166b 0x146f 0x13d2 0x13a1 0x1397 0x1839 0x16a1 0x1480 0x13d1 0x139e 0x1395 0x185a 0x16da 0x1493 0x13d1 0x139f 0x1396 0x1879 0x1713 0x14a7 0x13d1 0x13a0 0x1397 0x1896 0x174a 0x14bd 0x13d4 0x13a1 0x1398 0x18b2 0x177e 0x14d6 0x13d9 0x13a2 0x1398 0x18d9 0x17b2 0x14f1 0x13da 0x139f 0x1394 0x190b 0x17e8 0x1510 0x13dd 0x139d 0x1391 0x1938 0x1807 0x1522 0x13e5 0x13a4 0x139b 0x192e 0x17ff 0x1526 0x13e7 0x13a9 0x13a1 0x195a 0x182d 0x1542 0x13f0 0x13b3 0x13ac 0x1999 0x185f 0x1569 0x13fe 0x13be 0x13b6 0x19d3 0x1898 0x158d 0x1405 0x13be 0x13ac 0x1a11 0x18bb 0x159d 0x13f6 0x13a7 0x139b 0x1a6a 0x18f2 0x15c0 0x13fa 0x13aa 0x139e 0x1af2 0x1953 0x161b 0x1411 0x13b5 0x13a6 0x1c28 0x19c7 0x1691 0x1434 0x13ca 0x13bf 0x1c28 0x19c7 0x1691 0x1434 0x13ca 0x13bf 0x1c28 0x19c7 0x1691 0x1434 0x13ca 0x13bf>;
        qcom,lut-col-legend = <0xfffffff6 0x00 0x0a 0x19 0x28 0x32>;
    };

    qcom,pc-temp-y2-lut {
        qcom,lut-row-legend = <0x2710 0x2648 0x2580 0x24b8 0x23f0 0x2328 0x2260 0x2198 0x20d0 0x2008 0x1f40 0x1e78 0x1db0 0x1ce8 0x1c20 0x1b58 0x1a90 0x19c8 0x1900 0x1838 0x1770 0x16a8 0x15e0 0x1518 0x1450 0x1388 0x12c0 0x11f8 0x1130 0x1068 0xfa0 0xed8 0xe10 0xd48 0xc80 0xbb8 0xaf0 0xa28 0x960 0x898 0x7d0 0x708 0x640 0x578 0x4b0 0x3e8 0x384 0x320 0x2bc 0x258 0x1f4 0x190 0x12c 0xc8 0x64 0x00>;
        qcom,lut-data = <0x2647 0x2880 0x2ad2 0x2c44 0x2bc3 0x2b88 0x26a0 0x28a8 0x2acc 0x2c08 0x2b7e 0x2b5e 0x2702 0x28d3 0x2ac3 0x2bcc 0x2b37 0x2b20 0x2762 0x28fc 0x2ab6 0x2b93 0x2af8 0x2adc 0x27b3 0x291e 0x2aa7 0x2b63 0x2ac8 0x2aa3 0x27ea 0x2937 0x2a95 0x2b3d 0x2ab0 0x2a82 0x2805 0x2946 0x2a7d 0x2b20 0x2ab3 0x2a75 0x281a 0x2951 0x2a64 0x2b09 0x2ac0 0x2a6a 0x2858 0x2953 0x2a59 0x2b01 0x2ac3 0x2a58 0x291f 0x2944 0x2a54 0x2afc 0x2aba 0x2a35 0x29ab 0x293c 0x2a51 0x2afa 0x2ab2 0x2a1f 0x2992 0x2991 0x2a57 0x2afe 0x2ab1 0x2a3b 0x295d 0x2a25 0x2a65 0x2b09 0x2ab2 0x2a71 0x2956 0x2a57 0x2a80 0x2b18 0x2abb 0x2a84 0x29a0 0x2a52 0x2ac4 0x2b30 0x2ada 0x2a88 0x29f2 0x2a52 0x2b05 0x2b52 0x2b02 0x2a8d 0x2a1f 0x2a77 0x2b2a 0x2b91 0x2b27 0x2aaf 0x2a43 0x2aac 0x2b46 0x2be8 0x2b54 0x2af3 0x2a50 0x2ac6 0x2b5a 0x2c31 0x2b9c 0x2b39 0x2a51 0x2ad0 0x2b69 0x2c7d 0x2c2a 0x2b90 0x2a4b 0x2ad7 0x2b72 0x2ca9 0x2c89 0x2bc8 0x29d5 0x2adf 0x2b74 0x2c81 0x2c62 0x2bd2 0x289f 0x2ae7 0x2b72 0x2c33 0x2c06 0x2bd7 0x27ee 0x2aec 0x2b75 0x2c20 0x2bd4 0x2bd1 0x26cb 0x2aea 0x2b83 0x2c27 0x2bb9 0x2b95 0x25df 0x2ae1 0x2b96 0x2c31 0x2bac 0x2b63 0x25d5 0x2a18 0x2ba8 0x2c3f 0x2bae 0x2b86 0x25d3 0x2851 0x2bbb 0x2c53 0x2bb5 0x2bd8 0x25d0 0x278a 0x2bc2 0x2c68 0x2bc9 0x2bfd 0x25cc 0x2770 0x2bc3 0x2c82 0x2c1c 0x2c06 0x25c9 0x2766 0x2bc5 0x2c97 0x2c71 0x2c11 0x25c6 0x2769 0x2bcb 0x2ca4 0x2cac 0x2c36 0x25c4 0x27e2 0x2bd4 0x2cad 0x2ce9 0x2c7a 0x25c2 0x283f 0x2bd7 0x2cb3 0x2d05 0x2cad 0x25c0 0x2768 0x2bd1 0x2cbe 0x2d0c 0x2cd5 0x25bf 0x2648 0x2bc6 0x2cc7 0x2d0c 0x2cec 0x25be 0x2605 0x2bb5 0x2cc1 0x2cc9 0x2cab 0x25bd 0x25da 0x2b9a 0x2cad 0x2c46 0x2c1a 0x25bc 0x25c9 0x2b7d 0x2c99 0x2c1d 0x2bd9 0x25bb 0x25c4 0x2b58 0x2c85 0x2c31 0x2bc9 0x25bb 0x25c1 0x2b28 0x2c6e 0x2c42 0x2bc2 0x25ba 0x25bf 0x2aeb 0x2c4e 0x2c2e 0x2bc9 0x25ba 0x25bd 0x2aa2 0x2c27 0x2c0a 0x2bcc 0x25b9 0x25bb 0x2a47 0x2bf0 0x2bdb 0x2b94 0x25b9 0x25ba 0x29e0 0x2b89 0x2b73 0x2b24 0x25b8 0x25b9 0x2994 0x2b5c 0x2b08 0x2a8a 0x25b8 0x25b9 0x299d 0x2b70 0x2b17 0x2a67 0x25b8 0x25b9 0x2971 0x2b3c 0x2b2c 0x2a84 0x25b8 0x25b8 0x296c 0x2b45 0x2b24 0x2ab4 0x25b7 0x25b8 0x295b 0x2b1b 0x2b27 0x2a8f 0x25b7 0x25b7 0x2907 0x2b0d 0x2ad2 0x2a3c 0x25b6 0x25b7 0x26c9 0x2ace 0x2a88 0x2a15 0x25b6 0x25b6 0x2609 0x2a8a 0x2a6d 0x29dc 0x25b4 0x25b5 0x25d1 0x2a2d 0x2a3c 0x297a 0x25b4 0x25b5 0x25d1 0x2a2d 0x2a3c 0x297a 0x25b4 0x25b5 0x25d1 0x2a2d 0x2a3c 0x297a>;
        qcom,lut-col-legend = <0xfffffff6 0x00 0x0a 0x19 0x28 0x32>;
    };

    qcom,pc-temp-z6-lut {
        qcom,lut-row-legend = <0x2710 0x2648 0x2580 0x24b8 0x23f0 0x2328 0x2260 0x2198 0x20d0 0x2008 0x1f40 0x1e78 0x1db0 0x1ce8 0x1c20 0x1b58 0x1a90 0x19c8 0x1900 0x1838 0x1770 0x16a8 0x15e0 0x1518 0x1450 0x1388 0x12c0 0x11f8 0x1130 0x1068 0xfa0 0xed8 0xe10 0xd48 0xc80 0xbb8 0xaf0 0xa28 0x960 0x898 0x7d0 0x708 0x640 0x578 0x4b0 0x3e8 0x384 0x320 0x2bc 0x258 0x1f4 0x190 0x12c 0xc8 0x64 0x00>;
        qcom,lut-data = <0x3dc6 0x3bae 0x39f7 0x396c 0x392e 0x3e29 0x3bf9 0x3a2e 0x3985 0x3955 0x3de6 0x3bec 0x3a3c 0x3991 0x395d 0x3d8c 0x3ba3 0x3a33 0x3992 0x395f 0x3d3c 0x3b5e 0x3a14 0x3986 0x3959 0x3cea 0x3b2e 0x39f7 0x3976 0x394e 0x3ca6 0x3b05 0x39e3 0x3968 0x3942 0x3c6e 0x3ae1 0x39d0 0x3959 0x3935 0x3c40 0x3ac3 0x39bd 0x394e 0x392b 0x3c1c 0x3aa8 0x39a9 0x3944 0x3925 0x3c01 0x3a91 0x399a 0x393c 0x3920 0x3be5 0x3a7c 0x3990 0x3934 0x3919 0x3bc1 0x3a69 0x3988 0x392c 0x3912 0x3b9e 0x3a53 0x397f 0x3924 0x390c 0x3b8a 0x3a45 0x3975 0x391d 0x3906 0x3b7f 0x3a43 0x396c 0x3916 0x3900 0x3b75 0x3a42 0x3965 0x390f 0x38fa 0x3b65 0x3a40 0x395f 0x3908 0x38f3 0x3b54 0x3a34 0x395a 0x3902 0x38ed 0x3b4c 0x3a29 0x3953 0x38fc 0x38e8 0x3b48 0x3a2b 0x3951 0x38f9 0x38e4 0x3b47 0x3a38 0x396a 0x390b 0x38f0 0x3b50 0x3a4a 0x3991 0x3932 0x3912 0x3b74 0x3a72 0x39a4 0x3944 0x3924 0x3b92 0x3a97 0x39b1 0x3948 0x3929 0x3b9e 0x3a99 0x39b5 0x3949 0x392b 0x3ba7 0x3a8d 0x39af 0x3945 0x392a 0x3ba7 0x3a81 0x39a5 0x393f 0x3925 0x3b9e 0x3a78 0x399e 0x393a 0x3920 0x3b92 0x3a6f 0x3999 0x3936 0x391a 0x3b86 0x3a69 0x3994 0x3932 0x3913 0x3b7b 0x3a63 0x398f 0x392a 0x390c 0x3b72 0x3a5f 0x3989 0x3921 0x3904 0x3b6b 0x3a5a 0x3984 0x391b 0x38ff 0x3b66 0x3a56 0x397e 0x3917 0x38fa 0x3b61 0x3a53 0x3979 0x3914 0x38f7 0x3b5a 0x3a4f 0x3976 0x3913 0x38f7 0x3b57 0x3a4d 0x3973 0x3912 0x38f7 0x3b59 0x3a4f 0x3974 0x3913 0x38f9 0x3b5c 0x3a54 0x397a 0x3918 0x38fd 0x3b5d 0x3a56 0x397e 0x391c 0x3900 0x3b5c 0x3a52 0x397b 0x3919 0x38ff 0x3b5c 0x3a4d 0x3977 0x3916 0x38fe 0x3b57 0x3a4a 0x3975 0x3918 0x3901 0x3b31 0x3a36 0x3969 0x3911 0x38fc 0x3b21 0x3a29 0x395d 0x3904 0x38ef 0x3b1c 0x3a24 0x3955 0x38fd 0x38e8 0x3b1a 0x3a20 0x394b 0x38f2 0x38dd 0x3b18 0x3a1d 0x3943 0x38e7 0x38d1 0x3b1b 0x3a1f 0x3947 0x38e9 0x38d3 0x3b28 0x3a2e 0x3958 0x38ff 0x38eb 0x3b39 0x3a38 0x395f 0x3904 0x38f0 0x3b4a 0x3a44 0x3966 0x3908 0x38f4 0x3b64 0x3a54 0x396e 0x390e 0x38f9 0x3b64 0x3a54 0x396e 0x390e 0x38f9 0x3b64 0x3a54 0x396e 0x390e 0x38f9>;
        qcom,lut-col-legend = <0x00 0x0a 0x19 0x28 0x32>;
    };

    qcom,pc-temp-z2-lut {
        qcom,lut-row-legend = <0x2710 0x2648 0x2580 0x24b8 0x23f0 0x2328 0x2260 0x2198 0x20d0 0x2008 0x1f40 0x1e78 0x1db0 0x1ce8 0x1c20 0x1b58 0x1a90 0x19c8 0x1900 0x1838 0x1770 0x16a8 0x15e0 0x1518 0x1450 0x1388 0x12c0 0x11f8 0x1130 0x1068 0xfa0 0xed8 0xe10 0xd48 0xc80 0xbb8 0xaf0 0xa28 0x960 0x898 0x7d0 0x708 0x640 0x578 0x4b0 0x3e8 0x384 0x320 0x2bc 0x258 0x1f4 0x190 0x12c 0xc8 0x64 0x00>;
        qcom,lut-data = <0x288b 0x28a8 0x28de 0x282a 0x27e7 0x28cf 0x287f 0x28c3 0x288c 0x2830 0x2822 0x2858 0x28e8 0x28c6 0x286e 0x27a2 0x2833 0x28e1 0x28d5 0x2897 0x2781 0x2812 0x28a5 0x28bb 0x28a0 0x2767 0x27ef 0x286d 0x2894 0x288b 0x2753 0x27cf 0x2844 0x2870 0x286f 0x2746 0x27b7 0x2828 0x284b 0x284f 0x273b 0x27a3 0x2827 0x2846 0x2847 0x2733 0x2799 0x2834 0x285b 0x285c 0x272c 0x27a0 0x2844 0x286e 0x2873 0x2729 0x27b1 0x2856 0x286d 0x284f 0x2732 0x27ca 0x2868 0x2864 0x27e3 0x2743 0x2814 0x2874 0x2863 0x27b5 0x274c 0x285a 0x287e 0x2878 0x27c1 0x2751 0x2859 0x2888 0x288c 0x27d0 0x2757 0x2832 0x2894 0x2871 0x27dc 0x2770 0x2824 0x28a2 0x2838 0x27f0 0x279e 0x2837 0x28b2 0x2826 0x2807 0x27b8 0x284b 0x28ca 0x2834 0x2822 0x27c1 0x2850 0x28e2 0x284f 0x2844 0x27c6 0x2853 0x2907 0x28be 0x287c 0x27c5 0x2853 0x2926 0x295c 0x28bf 0x27c2 0x2844 0x2911 0x2968 0x28d1 0x27c0 0x2832 0x28c3 0x28cd 0x28bc 0x27c0 0x2830 0x289d 0x285b 0x28b3 0x27c1 0x2837 0x28af 0x287d 0x2909 0x27c5 0x2840 0x28d6 0x28c8 0x299e 0x27cf 0x2855 0x2903 0x28ed 0x29b8 0x27db 0x286b 0x2944 0x28fb 0x2910 0x27e3 0x2870 0x2962 0x28fb 0x2859 0x27ea 0x2870 0x2936 0x28ca 0x27ff 0x27f3 0x2871 0x28f6 0x2880 0x27c0 0x27fe 0x2873 0x28eb 0x2877 0x27b6 0x280a 0x2879 0x28ef 0x28b4 0x27e6 0x2818 0x2881 0x28f7 0x28fd 0x2826 0x2826 0x288c 0x2914 0x2938 0x285e 0x2836 0x289c 0x2943 0x2973 0x2895 0x2849 0x28b1 0x296e 0x29a7 0x28b9 0x285d 0x28cd 0x299d 0x29dc 0x28d0 0x2870 0x28e1 0x29b9 0x29f6 0x28ec 0x2882 0x28ea 0x29bf 0x29d0 0x293d 0x289f 0x28f8 0x29c5 0x29a3 0x298a 0x28da 0x291c 0x29d6 0x29aa 0x2920 0x2a15 0x29dc 0x2a19 0x297d 0x28db 0x2af6 0x2a3b 0x2a33 0x2948 0x28e1 0x2b42 0x2a64 0x2a17 0x293f 0x28cb 0x2b42 0x2ae3 0x2a03 0x2944 0x28c5 0x2b5f 0x2bcb 0x29fa 0x2972 0x2930 0x2b52 0x2b46 0x2a8a 0x2a10 0x29ab 0x2b8c 0x2c18 0x2b81 0x2901 0x2825 0x2a82 0x2c06 0x2b3c 0x288e 0x27d6 0x29cd 0x2c27 0x2ad5 0x285e 0x27a7 0x28bd 0x2b47 0x2a68 0x2819 0x2781 0x28bd 0x2b47 0x2a68 0x2819 0x2781 0x28bd 0x2b47 0x2a68 0x2819 0x2781>;
        qcom,lut-col-legend = <0x00 0x0a 0x19 0x28 0x32>;
    };

    qcom,fcc1-temp-lut {
        qcom,lut-data = <0xd81 0xdb9 0xe02 0xe1a 0xe28>;
        qcom,lut-col-legend = <0x00 0x0a 0x19 0x28 0x32>;
    };

    qcom,pc-temp-y5-lut {
        qcom,lut-row-legend = <0x2710 0x2648 0x2580 0x24b8 0x23f0 0x2328 0x2260 0x2198 0x20d0 0x2008 0x1f40 0x1e78 0x1db0 0x1ce8 0x1c20 0x1b58 0x1a90 0x19c8 0x1900 0x1838 0x1770 0x16a8 0x15e0 0x1518 0x1450 0x1388 0x12c0 0x11f8 0x1130 0x1068 0xfa0 0xed8 0xe10 0xd48 0xc80 0xbb8 0xaf0 0xa28 0x960 0x898 0x7d0 0x708 0x640 0x578 0x4b0 0x3e8 0x384 0x320 0x2bc 0x258 0x1f4 0x190 0x12c 0xc8 0x64 0x00>;
        qcom,lut-data = <0x2928 0x3721 0x3db2 0x40de 0x3df3 0x48b7 0x2d41 0x3896 0x3ec8 0x4101 0x3fab 0x4833 0x32d7 0x3a42 0x3ff9 0x40a6 0x40d3 0x47a9 0x38b3 0x3bef 0x4113 0x3ff3 0x4185 0x4726 0x3d9c 0x3d65 0x41e4 0x3f13 0x41dc 0x46b6 0x405b 0x3e6e 0x423b 0x3e2f 0x41f4 0x4664 0x4169 0x3efc 0x421d 0x3d2e 0x41b0 0x4627 0x4210 0x3f7b 0x41d4 0x3bf4 0x410f 0x45d8 0x412c 0x40e4 0x416a 0x3a7b 0x4041 0x4551 0x3ae4 0x45e6 0x4063 0x3820 0x3ef0 0x4444 0x360a 0x4988 0x3ef0 0x3647 0x3d63 0x42f0 0x3887 0x4353 0x3c78 0x35c4 0x3b5e 0x4168 0x3f1f 0x37a1 0x3983 0x35c8 0x3965 0x3f96 0x469c 0x35f7 0x385e 0x35bd 0x3936 0x3d83 0x52e7 0x41ae 0x37e9 0x3490 0x3aa3 0x3abc 0x5b12 0x4c6c 0x37b8 0x3391 0x3bac 0x391a 0x5875 0x4ef6 0x3c97 0x3331 0x397c 0x3991 0x52d2 0x5069 0x4682 0x32ae 0x3587 0x3a73 0x5148 0x5164 0x4c5d 0x33df 0x34ae 0x3a86 0x52ec 0x5213 0x4ffe 0x3d11 0x366a 0x39ad 0x546c 0x52a1 0x521d 0x4667 0x3931 0x3916 0x50d8 0x533d 0x52e4 0x4ae3 0x3f57 0x3d28 0x4634 0x53f8 0x5366 0x4e10 0x4754 0x4508 0x3e56 0x54db 0x53a5 0x4e6c 0x4913 0x4774 0x344e 0x5635 0x5357 0x4b62 0x46de 0x4768 0x2d02 0x5732 0x531b 0x4845 0x43d4 0x4709 0x2cd1 0x4d57 0x52ab 0x4714 0x408b 0x4533 0x2cda 0x3596 0x517b 0x463e 0x3d43 0x41a3 0x2cf1 0x2c79 0x514e 0x463b 0x3c1b 0x3e40 0x2d87 0x2c36 0x528f 0x46cc 0x3bb2 0x3a4c 0x2e5c 0x2c19 0x5382 0x46f6 0x3b7a 0x37cc 0x2efe 0x2d66 0x5172 0x46d3 0x3c64 0x3806 0x2f8e 0x31eb 0x4c53 0x4703 0x3efc 0x3923 0x3014 0x34ac 0x49ef 0x47e1 0x41b7 0x3b45 0x30a9 0x3472 0x4979 0x4a96 0x44fe 0x41e7 0x3159 0x33b3 0x492e 0x4ca1 0x4727 0x475e 0x3241 0x3429 0x491e 0x4c72 0x4627 0x46e2 0x3369 0x3511 0x4960 0x4b71 0x437b 0x4488 0x342d 0x3591 0x4962 0x49c1 0x41af 0x432d 0x349a 0x35c2 0x4851 0x456f 0x404f 0x4311 0x34da 0x35e0 0x46e8 0x411b 0x3f2c 0x4384 0x340f 0x357d 0x459d 0x3f3e 0x3e59 0x44a5 0x31af 0x3482 0x4508 0x3e58 0x3e79 0x45fe 0x30d1 0x33aa 0x474c 0x3fb6 0x41b1 0x434c 0x305c 0x323e 0x483c 0x3fdd 0x4333 0x3e4c 0x3017 0x3215 0x410d 0x4185 0x3ea8 0x4218 0x31a2 0x327f 0x4133 0x4074 0x3c52 0x3ea8 0x3247 0x333f 0x3e74 0x3f01 0x419b 0x3f6a 0x33aa 0x3305 0x4199 0x42a3 0x422b 0x3f12 0x33ce 0x342c 0x4485 0x4429 0x416e 0x3d63 0x3373 0x3421 0x440b 0x4d33 0x424c 0x4819 0x32d6 0x3406 0x3696 0x489d 0x4474 0x4b37 0x33a4 0x32c3 0x3757 0x5024 0x545d 0x52cf 0x378a 0x33eb 0x384d 0x5586 0x5b5a 0x5f94 0x378a 0x33eb 0x384d 0x5586 0x5b5a 0x5f94 0x378a 0x33eb 0x384d 0x5586 0x5b5a 0x5f94>;
        qcom,lut-col-legend = <0xfffffff6 0x00 0x0a 0x19 0x28 0x32>;
    };

    qcom,pc-temp-y1-lut {
        qcom,lut-row-legend = <0x2710 0x2648 0x2580 0x24b8 0x23f0 0x2328 0x2260 0x2198 0x20d0 0x2008 0x1f40 0x1e78 0x1db0 0x1ce8 0x1c20 0x1b58 0x1a90 0x19c8 0x1900 0x1838 0x1770 0x16a8 0x15e0 0x1518 0x1450 0x1388 0x12c0 0x11f8 0x1130 0x1068 0xfa0 0xed8 0xe10 0xd48 0xc80 0xbb8 0xaf0 0xa28 0x960 0x898 0x7d0 0x708 0x640 0x578 0x4b0 0x3e8 0x384 0x320 0x2bc 0x258 0x1f4 0x190 0x12c 0xc8 0x64 0x00>;
        qcom,lut-data = <0x19b0 0x176f 0x167d 0x14cd 0x1407 0x13c9 0x19b7 0x177e 0x1673 0x14cc 0x1407 0x13cc 0x19b8 0x1789 0x1668 0x14cb 0x1407 0x13ce 0x19b6 0x1791 0x165d 0x14c9 0x1407 0x13d0 0x19b3 0x1796 0x1654 0x14c6 0x1406 0x13d0 0x19b1 0x1798 0x164d 0x14c2 0x1405 0x13d0 0x19aa 0x1798 0x1648 0x14be 0x1403 0x13d0 0x199f 0x179a 0x1644 0x14b9 0x1402 0x13ce 0x199e 0x179c 0x1640 0x14b6 0x1400 0x13ce 0x19a0 0x17a1 0x163e 0x14b3 0x13ff 0x13cd 0x19a2 0x17a3 0x163c 0x14b1 0x13fe 0x13cd 0x19a9 0x17a4 0x1636 0x14b2 0x13fd 0x13cd 0x19b2 0x17a8 0x162d 0x14b2 0x13fc 0x13cd 0x19b3 0x17ac 0x162c 0x14b2 0x13fc 0x13cd 0x19a4 0x17b0 0x1634 0x14b0 0x13fc 0x13cd 0x1996 0x17b3 0x163a 0x14af 0x13fc 0x13cd 0x1994 0x17b3 0x1636 0x14b0 0x13fd 0x13ce 0x1994 0x17b1 0x162d 0x14b1 0x13fe 0x13cf 0x1994 0x17b1 0x162a 0x14b3 0x13fe 0x13d0 0x199b 0x17be 0x1630 0x14b5 0x13ff 0x13d0 0x19a2 0x17cb 0x1637 0x14b6 0x13ff 0x13d1 0x1999 0x17c2 0x1637 0x14b9 0x1400 0x13d1 0x1986 0x17ae 0x1636 0x14bc 0x1401 0x13d1 0x197e 0x17a7 0x1635 0x14c0 0x1402 0x13d2 0x197f 0x17a3 0x1635 0x14c6 0x1404 0x13d4 0x1980 0x17a0 0x1636 0x14cb 0x1407 0x13d6 0x1986 0x17a0 0x163b 0x14ce 0x1409 0x13d7 0x1990 0x17a2 0x1642 0x14d1 0x140c 0x13d9 0x1992 0x17a1 0x1645 0x14d5 0x140e 0x13db 0x198d 0x179d 0x1646 0x14da 0x1411 0x13de 0x198c 0x179a 0x1648 0x14e0 0x1414 0x13e1 0x198c 0x17a7 0x164c 0x14e5 0x1418 0x13e4 0x1984 0x17c8 0x1654 0x14ec 0x141b 0x13e6 0x1982 0x17d4 0x1659 0x14f3 0x141f 0x13e8 0x198f 0x17bd 0x165d 0x14fb 0x1422 0x13ea 0x199d 0x17a5 0x1660 0x1502 0x1426 0x13ec 0x1998 0x17a8 0x166a 0x1505 0x1428 0x13ee 0x1986 0x17b4 0x1676 0x1507 0x142a 0x13f1 0x197f 0x17b8 0x167b 0x150a 0x142c 0x13f3 0x1984 0x17be 0x1682 0x150e 0x142f 0x13f4 0x1984 0x17c7 0x1689 0x1513 0x1432 0x13f6 0x1975 0x17c9 0x1687 0x151a 0x1435 0x13f8 0x1965 0x17c8 0x1680 0x1524 0x1438 0x13fa 0x196b 0x17ca 0x1693 0x1535 0x143d 0x13fd 0x1977 0x17d2 0x16a0 0x153e 0x1442 0x1402 0x1985 0x17b0 0x168a 0x153d 0x1448 0x1404 0x1984 0x17a8 0x169a 0x1541 0x1448 0x1404 0x1976 0x17b2 0x169e 0x154e 0x144a 0x1404 0x19a0 0x17c5 0x169f 0x154d 0x1446 0x1404 0x19b9 0x17ba 0x16a6 0x1555 0x1448 0x1407 0x199b 0x17b6 0x169b 0x1550 0x144c 0x1409 0x198a 0x17da 0x16b9 0x1555 0x1452 0x140d 0x19b0 0x17da 0x16b3 0x156b 0x145b 0x1415 0x19cd 0x17f6 0x16c2 0x158c 0x1467 0x141f 0x19cd 0x17f6 0x16c2 0x158c 0x1467 0x141f 0x19cd 0x17f6 0x16c2 0x158c 0x1467 0x141f>;
        qcom,lut-col-legend = <0xfffffff6 0x00 0x0a 0x19 0x28 0x32>;
    };

    qcom,pc-temp-z5-lut {
        qcom,lut-row-legend = <0x2710 0x2648 0x2580 0x24b8 0x23f0 0x2328 0x2260 0x2198 0x20d0 0x2008 0x1f40 0x1e78 0x1db0 0x1ce8 0x1c20 0x1b58 0x1a90 0x19c8 0x1900 0x1838 0x1770 0x16a8 0x15e0 0x1518 0x1450 0x1388 0x12c0 0x11f8 0x1130 0x1068 0xfa0 0xed8 0xe10 0xd48 0xc80 0xbb8 0xaf0 0xa28 0x960 0x898 0x7d0 0x708 0x640 0x578 0x4b0 0x3e8 0x384 0x320 0x2bc 0x258 0x1f4 0x190 0x12c 0xc8 0x64 0x00>;
        qcom,lut-data = <0x2e1e 0x2ee1 0x317a 0x3314 0x3536 0x3337 0x367c 0x35d2 0x3850 0x3845 0x3610 0x39f8 0x3b63 0x3e3f 0x3e5e 0x3837 0x3bd0 0x3d69 0x4253 0x43ee 0x3a14 0x3da1 0x3e25 0x44bc 0x4711 0x3ba2 0x3fdf 0x3f10 0x45d6 0x4934 0x3ceb 0x420d 0x40c6 0x4621 0x4a29 0x3dda 0x43f1 0x42c8 0x46da 0x4b97 0x3ecc 0x45bd 0x4455 0x4836 0x4d4e 0x4092 0x47ca 0x45b4 0x4ade 0x4f9c 0x435b 0x4ab4 0x4631 0x4cba 0x5158 0x44c6 0x4da2 0x470f 0x4b93 0x5018 0x42fa 0x4f4e 0x4872 0x48c9 0x4c0c 0x4026 0x50fb 0x4945 0x4883 0x4a80 0x40c1 0x5238 0x4a3a 0x4d45 0x4dcb 0x497a 0x5461 0x4ab7 0x510f 0x5126 0x50bd 0x5824 0x4bda 0x4f24 0x5120 0x4eb8 0x5a40 0x4e28 0x4b14 0x5076 0x48ec 0x5b5b 0x5098 0x4a0c 0x5086 0x46a2 0x5cff 0x5388 0x4c04 0x5402 0x4c84 0x67d1 0x5946 0x4fcd 0x5901 0x5858 0x85b0 0x7afe 0x60c9 0x5e0f 0x7089 0x964d 0xa31c 0x79dc 0x6311 0xa190 0x946d 0xa011 0x7b6e 0x622e 0xbcf4 0x8e49 0x7989 0x5baa 0x4d1e 0xb4d7 0x838d 0x5a8e 0x406d 0x3a16 0xa4a6 0x6ed9 0x4ca6 0x3b58 0x3d51 0x9776 0x61a2 0x4401 0x38c7 0x492f 0x8be3 0x5e26 0x43f1 0x3b73 0x5165 0x8238 0x5c24 0x49cb 0x5074 0x5687 0x7ac2 0x5d7b 0x520c 0x6094 0x5a5f 0x7491 0x6749 0x6164 0x60bc 0x5c9e 0x72aa 0x72b3 0x721c 0x602c 0x5e40 0x73d3 0x7d49 0x7900 0x6173 0x5ff4 0x7582 0x8833 0x7d25 0x6a9e 0x6276 0x75e3 0x8cea 0x7ecb 0x7161 0x6415 0x73ec 0x8ee3 0x7e21 0x7013 0x6341 0x734a 0x8fe5 0x7c63 0x6c60 0x60bd 0x78a7 0x8eac 0x7794 0x66bf 0x5cbb 0x8025 0x8ada 0x69df 0x5bac 0x53da 0x8096 0x862c 0x6067 0x5344 0x4de4 0x752f 0x7db5 0x5edd 0x50f7 0x52ee 0x6b3c 0x7443 0x5d56 0x4f65 0x593a 0x645b 0x6ab9 0x5720 0x4d53 0x560c 0x5a1c 0x67ae 0x578d 0x4adb 0x4f49 0x42d3 0x601e 0x5b20 0x48e1 0x4701 0x342e 0x56aa 0x53c2 0x4859 0x4393 0x2fbf 0x4445 0x4d41 0x47cc 0x4886 0x2f09 0x3add 0x495b 0x51eb 0x4c84 0x2efe 0x4054 0x4522 0x4536 0x4b64 0x30ab 0x3a3c 0x357d 0x4410 0x5059 0x2ff6 0x35f5 0x3324 0x4404 0x52d5 0x2f95 0x3131 0x3404 0x3f2d 0x4f08 0x2f27 0x30af 0x32a9 0x4086 0x4aca 0x2f27 0x30af 0x32a9 0x4086 0x4aca 0x2f27 0x30af 0x32a9 0x4086 0x4aca>;
        qcom,lut-col-legend = <0x00 0x0a 0x19 0x28 0x32>;
    };

    qcom,pc-temp-z1-lut {
        qcom,lut-row-legend = <0x2710 0x2648 0x2580 0x24b8 0x23f0 0x2328 0x2260 0x2198 0x20d0 0x2008 0x1f40 0x1e78 0x1db0 0x1ce8 0x1c20 0x1b58 0x1a90 0x19c8 0x1900 0x1838 0x1770 0x16a8 0x15e0 0x1518 0x1450 0x1388 0x12c0 0x11f8 0x1130 0x1068 0xfa0 0xed8 0xe10 0xd48 0xc80 0xbb8 0xaf0 0xa28 0x960 0x898 0x7d0 0x708 0x640 0x578 0x4b0 0x3e8 0x384 0x320 0x2bc 0x258 0x1f4 0x190 0x12c 0xc8 0x64 0x00>;
        qcom,lut-data = <0x335b 0x30e8 0x2e2b 0x2cd7 0x2c73 0x3337 0x30cb 0x2e2d 0x2ce7 0x2c93 0x3342 0x30bb 0x2e22 0x2ce3 0x2c90 0x3348 0x30af 0x2e15 0x2cde 0x2c8d 0x333b 0x30a3 0x2e05 0x2cd7 0x2c8a 0x3325 0x3094 0x2df6 0x2cd0 0x2c87 0x331d 0x3082 0x2dea 0x2ccd 0x2c86 0x331c 0x306e 0x2de0 0x2ccb 0x2c85 0x331a 0x3053 0x2dda 0x2cc9 0x2c85 0x330e 0x3042 0x2dd5 0x2cc7 0x2c84 0x32f1 0x3045 0x2dd4 0x2cc7 0x2c84 0x32e0 0x304b 0x2dd5 0x2cc7 0x2c84 0x32df 0x304b 0x2dd7 0x2cc7 0x2c85 0x32de 0x3038 0x2dd6 0x2cc8 0x2c85 0x32d8 0x3024 0x2dd3 0x2cc9 0x2c86 0x32c3 0x301d 0x2dd2 0x2cca 0x2c88 0x32b0 0x3018 0x2dd3 0x2ccb 0x2c89 0x32af 0x3016 0x2dd5 0x2ccc 0x2c8b 0x32b2 0x301d 0x2dda 0x2cce 0x2c8d 0x32b2 0x3026 0x2de0 0x2cd0 0x2c8e 0x32ac 0x302b 0x2de4 0x2cd2 0x2c90 0x32a9 0x302e 0x2de5 0x2cd3 0x2c91 0x32ad 0x3030 0x2de6 0x2cd3 0x2c93 0x32b6 0x3032 0x2de9 0x2cd5 0x2c94 0x32bc 0x3035 0x2df0 0x2cd8 0x2c96 0x32bd 0x303a 0x2df6 0x2cdb 0x2c99 0x32bd 0x3045 0x2dfb 0x2cdf 0x2c9c 0x32c1 0x304b 0x2e01 0x2ce3 0x2ca0 0x32c8 0x304f 0x2e06 0x2ce8 0x2ca4 0x32ce 0x3052 0x2e0d 0x2ced 0x2ca9 0x32d5 0x3057 0x2e14 0x2cf2 0x2cad 0x32e3 0x3061 0x2e19 0x2cf6 0x2cb1 0x32eb 0x3069 0x2e1f 0x2cfb 0x2cb5 0x32ee 0x306c 0x2e27 0x2cff 0x2cb9 0x32ef 0x3070 0x2e30 0x2d03 0x2cbd 0x32ef 0x3076 0x2e37 0x2d07 0x2cc0 0x32f3 0x307e 0x2e3a 0x2d0b 0x2cc4 0x32fd 0x3085 0x2e3c 0x2d10 0x2cc7 0x3317 0x308b 0x2e41 0x2d14 0x2cca 0x3337 0x3092 0x2e4d 0x2d18 0x2ccd 0x3342 0x3094 0x2e56 0x2d1c 0x2cd0 0x333e 0x3095 0x2e5b 0x2d20 0x2cd4 0x333b 0x3099 0x2e61 0x2d25 0x2cd7 0x3326 0x30ab 0x2e6f 0x2d28 0x2cd9 0x3310 0x30ab 0x2e7d 0x2d2f 0x2cdc 0x3325 0x30c6 0x2e84 0x2d34 0x2cdf 0x333c 0x30c8 0x2e80 0x2d34 0x2ce0 0x3312 0x30c4 0x2e8c 0x2d37 0x2ce2 0x3319 0x30c2 0x2e8c 0x2d39 0x2ce4 0x333b 0x30c3 0x2e95 0x2d41 0x2ce8 0x3327 0x30bc 0x2e9e 0x2d47 0x2cee 0x3327 0x30da 0x2ea9 0x2d4f 0x2cf7 0x3363 0x3102 0x2ebd 0x2d5d 0x2d01 0x3371 0x3108 0x2ed3 0x2d6e 0x2d0f 0x3371 0x3108 0x2ed3 0x2d6e 0x2d0f 0x3371 0x3108 0x2ed3 0x2d6e 0x2d0f>;
        qcom,lut-col-legend = <0x00 0x0a 0x19 0x28 0x32>;
    };
};

qcom,mlp356477_2800mah {
    qcom,batt-id-kohm = <0x52>;
    qcom,jeita-hard-thresholds = <0x58cd 0x181d>;
    qcom,fastchg-current-ma = <0x1068>;
    qcom,max-voltage-uv = <0x432380>;
    qcom,qg-batt-profile-ver = <0x64>;
    qcom,battery-therm-kohm = <0x64>;
    qcom,battery-beta = <0x109a>;
    qcom,jeita-soft-thresholds = <0x4621 0x20b8>;
    qcom,fg-cc-cv-threshold-mv = <0x1126>;
    qcom,jeita-fcc-ranges = <0x00 0x96 0x88b80 0x97 0x1c2 0x401640 0x1c3 0x226 0x2450e0>;
    qcom,battery-type = "mlp356477_2800mah_averaged_MasterSlave_Mar13th2018";
    qcom,jeita-fv-ranges = <0x00 0x96 0x3f52f0 0x97 0x1c2 0x432380 0x1c3 0x226 0x3f52f0>;

    qcom,pc-temp-y4-lut {
        qcom,lut-row-legend = <0x2710 0x2648 0x2580 0x24b8 0x23f0 0x2328 0x2260 0x2198 0x20d0 0x2008 0x1f40 0x1e78 0x1db0 0x1ce8 0x1c20 0x1b58 0x1a90 0x19c8 0x1900 0x1838 0x1770 0x16a8 0x15e0 0x1518 0x1450 0x1388 0x12c0 0x11f8 0x1130 0x1068 0xfa0 0xed8 0xe10 0xd48 0xc80 0xbb8 0xaf0 0xa28 0x960 0x898 0x7d0 0x708 0x640 0x578 0x4b0 0x3e8 0x384 0x320 0x2bc 0x258 0x1f4 0x190 0x12c 0xc8 0x64 0x00>;
        qcom,lut-data = <0x4428 0x4399 0x419e 0x40e2 0x4063 0x4056 0x4470 0x43b2 0x41de 0x40e2 0x4066 0x4055 0x44c1 0x43e2 0x4226 0x40e1 0x4069 0x4054 0x450f 0x4419 0x4269 0x40e0 0x406b 0x4053 0x4550 0x4447 0x429b 0x40df 0x406d 0x4053 0x4577 0x445d 0x42ae 0x40dd 0x406d 0x4052 0x4586 0x445f 0x42a3 0x40db 0x406d 0x4052 0x4595 0x4460 0x4291 0x40d9 0x406c 0x4052 0x45fe 0x4467 0x4286 0x40d7 0x406d 0x4052 0x4704 0x448e 0x427f 0x40d7 0x4071 0x4056 0x4767 0x44c8 0x427c 0x40d7 0x4074 0x4059 0x46e4 0x454e 0x428a 0x40da 0x4076 0x405e 0x4619 0x45ee 0x42a6 0x40e1 0x407a 0x4063 0x4548 0x45d4 0x42be 0x40eb 0x4080 0x4067 0x4462 0x448b 0x42d6 0x40fe 0x408b 0x406c 0x43f7 0x43a8 0x42ee 0x4113 0x4097 0x4072 0x43d3 0x43c0 0x4309 0x4127 0x40a2 0x407a 0x43b0 0x43ea 0x431f 0x413f 0x40b0 0x4086 0x4372 0x43da 0x4312 0x416c 0x40ca 0x4099 0x4329 0x4340 0x42b8 0x41b5 0x40f6 0x40b9 0x42f5 0x42a4 0x424e 0x41d4 0x410b 0x40c9 0x42cc 0x424e 0x41e1 0x4172 0x40da 0x40a8 0x42b5 0x420c 0x4179 0x40e8 0x4091 0x4076 0x42ae 0x41e9 0x413f 0x40b7 0x4076 0x4063 0x42aa 0x41d3 0x4116 0x409f 0x4069 0x4059 0x42aa 0x41c9 0x4107 0x4097 0x4065 0x4055 0x42aa 0x41c9 0x4129 0x4097 0x4065 0x4056 0x42ab 0x41ca 0x4157 0x4097 0x4067 0x4057 0x42ae 0x41cb 0x415c 0x4099 0x4069 0x405a 0x42b2 0x41cc 0x4151 0x409f 0x4071 0x4062 0x42b7 0x41cd 0x414c 0x40a5 0x407b 0x406b 0x42c0 0x41d4 0x4151 0x40aa 0x4089 0x4078 0x42c7 0x41e2 0x415a 0x40ae 0x4097 0x4083 0x42cb 0x41ef 0x415c 0x40ac 0x409c 0x4086 0x42cf 0x41fd 0x414a 0x40a5 0x409c 0x4083 0x42d7 0x420a 0x4140 0x409c 0x4096 0x407d 0x42e4 0x4218 0x415f 0x4090 0x4079 0x406c 0x42ee 0x4224 0x4190 0x4085 0x405d 0x405b 0x42f6 0x422d 0x41a5 0x4085 0x405c 0x4057 0x42fd 0x4233 0x41af 0x408a 0x405f 0x4055 0x4305 0x4236 0x41b2 0x4092 0x4061 0x4055 0x430f 0x4234 0x41b2 0x40a0 0x4062 0x4055 0x4323 0x4231 0x41b1 0x40ab 0x4061 0x4053 0x4338 0x4233 0x41af 0x40b1 0x4057 0x4046 0x42f4 0x4245 0x41ba 0x40bf 0x405d 0x4048 0x4318 0x4241 0x41d1 0x40c8 0x406d 0x405d 0x4332 0x4251 0x41fd 0x40de 0x4077 0x406f 0x4381 0x4296 0x423a 0x40fb 0x4090 0x4093 0x43ee 0x42d3 0x4281 0x4127 0x40ad 0x4094 0x4474 0x42eb 0x429e 0x412a 0x4083 0x406d 0x451a 0x42cd 0x428e 0x4121 0x408f 0x4072 0x463a 0x42a4 0x429b 0x4148 0x40a4 0x4082 0x4891 0x42a7 0x42e4 0x417c 0x40cc 0x40aa 0x4ebc 0x42ef 0x4367 0x41ef 0x4157 0x414f 0x4ebc 0x42ef 0x4367 0x41ef 0x4157 0x414f 0x4ebc 0x42ef 0x4367 0x41ef 0x4157 0x414f>;
        qcom,lut-col-legend = <0xfffffff6 0x00 0x0a 0x19 0x28 0x32>;
    };

    qcom,pc-temp-v2-lut {
        qcom,lut-row-legend = <0x2710 0x2648 0x2580 0x24b8 0x23f0 0x2328 0x2260 0x2198 0x20d0 0x2008 0x1f40 0x1e78 0x1db0 0x1ce8 0x1c20 0x1b58 0x1a90 0x19c8 0x1900 0x1838 0x1770 0x16a8 0x15e0 0x1518 0x1450 0x1388 0x12c0 0x11f8 0x1130 0x1068 0xfa0 0xed8 0xe10 0xd48 0xc80 0xbb8 0xaf0 0xa28 0x960 0x898 0x7d0 0x708 0x640 0x578 0x4b0 0x3e8 0x384 0x320 0x2bc 0x258 0x1f4 0x190 0x12c 0xc8 0x64 0x00>;
        qcom,lut-data = <0xab59 0xab4a 0xab36 0xab1d 0xaadc 0xaacd 0xa9a8 0xa9a5 0xa9fa 0xaa08 0xa9d9 0xa9cb 0xa81d 0xa838 0xa8d3 0xa900 0xa8dc 0xa8d0 0xa6bd 0xa70f 0xa7c4 0xa804 0xa7e7 0xa7dd 0xa581 0xa61e 0xa6cc 0xa715 0xa6f8 0xa6f2 0xa45b 0xa538 0xa5da 0xa629 0xa60d 0xa609 0xa330 0xa44b 0xa4e5 0xa53f 0xa525 0xa520 0xa22d 0xa35e 0xa3f4 0xa457 0xa43f 0xa439 0xa189 0xa263 0xa30b 0xa373 0xa35c 0xa356 0xa117 0xa152 0xa22b 0xa293 0xa27b 0xa275 0xa087 0xa06d 0xa151 0xa1b6 0xa19e 0xa198 0x9fbf 0x9fe0 0xa080 0xa0dd 0xa0c6 0xa0bf 0x9eca 0x9f68 0x9fb4 0xa007 0x9ff2 0x9fea 0x9d89 0x9ea3 0x9ee5 0x9f3b 0x9f26 0x9f1e 0x9c05 0x9d5c 0x9e0d 0x9e76 0x9e5d 0x9e56 0x9ae6 0x9c35 0x9d43 0x9db5 0x9d9c 0x9d96 0x9a20 0x9b83 0x9c97 0x9cf4 0x9ce4 0x9cde 0x996e 0x9aee 0x9bf0 0x9c39 0x9c31 0x9c2c 0x98ae 0x9a23 0x9b2a 0x9b8d 0x9b86 0x9b80 0x97f4 0x9910 0x9a44 0x9af0 0x9ae3 0x9ade 0x9754 0x980c 0x9960 0x9a3b 0x9a2d 0x9a2a 0x96c6 0x9741 0x9888 0x9945 0x993e 0x993e 0x9650 0x9692 0x97be 0x9846 0x984a 0x984d 0x95f2 0x9603 0x9716 0x978f 0x9799 0x979d 0x95a4 0x958a 0x9687 0x96fe 0x970d 0x9712 0x9560 0x952d 0x9606 0x9682 0x9693 0x9698 0x9526 0x94ed 0x958e 0x9613 0x9626 0x962a 0x94ef 0x94bb 0x9523 0x95b0 0x95c5 0x95c7 0x94bc 0x948e 0x94ca 0x9555 0x956a 0x956a 0x948c 0x9468 0x947c 0x9500 0x9516 0x9514 0x945a 0x9443 0x943d 0x94b2 0x94c9 0x94c6 0x9427 0x941c 0x940c 0x9469 0x9483 0x9480 0x93f3 0x93f3 0x93e1 0x9425 0x9441 0x943d 0x93bc 0x93c8 0x93b9 0x93e4 0x93fc 0x93f3 0x9383 0x939c 0x9395 0x93a9 0x93b4 0x93a3 0x9343 0x936a 0x936c 0x936a 0x9360 0x9346 0x92fe 0x9330 0x9338 0x9327 0x92f9 0x92d3 0x92b3 0x92ed 0x92f9 0x92e0 0x928f 0x925d 0x9263 0x92a1 0x92b0 0x9295 0x9236 0x91fe 0x9210 0x9248 0x9259 0x9246 0x91e8 0x91ac 0x91bc 0x91e5 0x91f3 0x91e9 0x918f 0x9150 0x9166 0x9175 0x9176 0x9176 0x911f 0x90e0 0x910d 0x90fa 0x90ed 0x90f2 0x909e 0x9060 0x90ab 0x907d 0x905d 0x9058 0x9006 0x8fcd 0x9047 0x900b 0x8ffb 0x8ffe 0x8fc7 0x8f96 0x8fd1 0x8fb8 0x8fb8 0x8fdc 0x8fb1 0x8f7e 0x8f90 0x8f92 0x8f9a 0x8fcc 0x8fa1 0x8f6f 0x8f3b 0x8f63 0x8f66 0x8fac 0x8f80 0x8f4f 0x8ebd 0x8f19 0x8f05 0x8f71 0x8f30 0x8ee5 0x8df6 0x8e78 0x8e3b 0x8ea5 0x8e1b 0x8db4 0x8cb8 0x8d35 0x8cbf 0x8d11 0x8c6a 0x8bf5 0x8af7 0x8b42 0x8a9d 0x8b00 0x8a3a 0x89ba 0x8889 0x8894 0x87d3 0x8844 0x8753 0x86c4 0x8519 0x84d7 0x83cb 0x846e 0x833e 0x82a0 0x7f87 0x7eda 0x7d90 0x7e89 0x7d19 0x7c55 0x7542 0x6d93 0x6791 0x7041 0x6ba2 0x696f>;
        qcom,lut-col-legend = <0xfffffff6 0x00 0x0a 0x19 0x28 0x32>;
    };

    qcom,pc-temp-z4-lut {
        qcom,lut-row-legend = <0x2710 0x2648 0x2580 0x24b8 0x23f0 0x2328 0x2260 0x2198 0x20d0 0x2008 0x1f40 0x1e78 0x1db0 0x1ce8 0x1c20 0x1b58 0x1a90 0x19c8 0x1900 0x1838 0x1770 0x16a8 0x15e0 0x1518 0x1450 0x1388 0x12c0 0x11f8 0x1130 0x1068 0xfa0 0xed8 0xe10 0xd48 0xc80 0xbb8 0xaf0 0xa28 0x960 0x898 0x7d0 0x708 0x640 0x578 0x4b0 0x3e8 0x384 0x320 0x2bc 0x258 0x1f4 0x190 0x12c 0xc8 0x64 0x00>;
        qcom,lut-data = <0x40d6 0x3e78 0x3be9 0x3a7c 0x3a1f 0x41af 0x3ea3 0x3c1a 0x3ad3 0x3a5c 0x40b1 0x3e33 0x3bad 0x3a86 0x3a33 0x3f9b 0x3d29 0x3b45 0x3a35 0x39fa 0x3e6e 0x3c4c 0x3aea 0x3a1f 0x39e8 0x3d9e 0x3bc8 0x3aac 0x3a14 0x39e0 0x3db8 0x3b67 0x3a8c 0x3a08 0x39d9 0x3e45 0x3b32 0x3a76 0x39fb 0x39d2 0x3e85 0x3b0f 0x3a62 0x39ee 0x39ca 0x3d86 0x3af6 0x3a50 0x39e2 0x39c1 0x3c17 0x3ae4 0x3a40 0x39d7 0x39b7 0x3bd4 0x3ad7 0x3a31 0x39cd 0x39ae 0x3c49 0x3ac8 0x3a24 0x39c4 0x39a5 0x3c8d 0x3ab9 0x3a1a 0x39ba 0x399c 0x3c67 0x3ab1 0x3a12 0x39b1 0x3991 0x3c95 0x3abd 0x3a0c 0x39a8 0x3985 0x3cec 0x3ad1 0x3a04 0x399f 0x397e 0x3d3d 0x3ad0 0x39f9 0x3996 0x397b 0x3d71 0x3a9a 0x39f3 0x3992 0x3978 0x3d5c 0x3a67 0x39f0 0x3990 0x3975 0x3d44 0x3aa9 0x39f1 0x398f 0x3973 0x3d22 0x3b67 0x3a4b 0x39a4 0x397e 0x3c94 0x3bc6 0x3adc 0x39f5 0x39b9 0x3bc2 0x3bd1 0x3af3 0x3a1f 0x39de 0x3b83 0x3bd7 0x3ac0 0x3a16 0x39d9 0x3bb2 0x3bbe 0x3a8d 0x3a07 0x39d0 0x3be2 0x3b60 0x3a72 0x39f9 0x39c9 0x3bd8 0x3b1b 0x3a5f 0x39ea 0x39c3 0x3ba6 0x3b01 0x3a54 0x39de 0x39bc 0x3b80 0x3af0 0x3a4e 0x39d5 0x39b3 0x3bac 0x3ae4 0x3a4b 0x39ce 0x39a9 0x3c0d 0x3ad9 0x3a49 0x39ca 0x39a2 0x3c25 0x3ad1 0x3a48 0x39c7 0x399b 0x3c19 0x3acb 0x3a47 0x39c5 0x3996 0x3c10 0x3ac3 0x3a44 0x39c3 0x3992 0x3c46 0x3abc 0x3a42 0x39c2 0x3990 0x3cb8 0x3aa8 0x3a43 0x39ca 0x3999 0x3cd9 0x3a96 0x3a46 0x39db 0x39af 0x3cbe 0x3a8f 0x3a45 0x39e0 0x39b6 0x3ca0 0x3a8b 0x3a3d 0x39db 0x39b0 0x3c8e 0x3a96 0x3a30 0x39d3 0x39a8 0x3c83 0x3b23 0x3a19 0x39c4 0x39a0 0x3c73 0x3b6b 0x3a02 0x39b6 0x399b 0x3c55 0x3b5b 0x39fa 0x39b6 0x399e 0x3bf1 0x3b1a 0x39dd 0x39ac 0x3995 0x3bd6 0x3ae7 0x39d2 0x3990 0x3981 0x3bcc 0x3ada 0x39b9 0x3980 0x396c 0x3bc5 0x3ad1 0x39a5 0x3971 0x395c 0x3bb5 0x3ac5 0x3993 0x396a 0x394c 0x3baa 0x3acd 0x39b7 0x397d 0x3960 0x3bbe 0x3ae4 0x39be 0x397f 0x3968 0x3bcf 0x3ae8 0x39ba 0x3978 0x396d 0x3bde 0x3af3 0x39bb 0x397f 0x396d 0x3bfa 0x3b04 0x39b0 0x3972 0x396f 0x3bfa 0x3b04 0x39b0 0x3972 0x396f 0x3bfa 0x3b04 0x39b0 0x3972 0x396f>;
        qcom,lut-col-legend = <0x00 0x0a 0x19 0x28 0x32>;
    };

    qcom,pc-temp-y3-lut {
        qcom,lut-row-legend = <0x2710 0x2648 0x2580 0x24b8 0x23f0 0x2328 0x2260 0x2198 0x20d0 0x2008 0x1f40 0x1e78 0x1db0 0x1ce8 0x1c20 0x1b58 0x1a90 0x19c8 0x1900 0x1838 0x1770 0x16a8 0x15e0 0x1518 0x1450 0x1388 0x12c0 0x11f8 0x1130 0x1068 0xfa0 0xed8 0xe10 0xd48 0xc80 0xbb8 0xaf0 0xa28 0x960 0x898 0x7d0 0x708 0x640 0x578 0x4b0 0x3e8 0x384 0x320 0x2bc 0x258 0x1f4 0x190 0x12c 0xc8 0x64 0x00>;
        qcom,lut-data = <0x38a5 0x356d 0x344e 0x33fd 0x33f5 0x33df 0x384c 0x3559 0x3451 0x33fd 0x33ee 0x33df 0x37f8 0x3542 0x3455 0x33ff 0x33e9 0x33df 0x37a9 0x352c 0x3458 0x3400 0x33e5 0x33df 0x3763 0x351c 0x345b 0x3402 0x33e3 0x33df 0x3725 0x3516 0x345e 0x3403 0x33e2 0x33df 0x36ef 0x351a 0x3460 0x3403 0x33e3 0x33e0 0x36c1 0x3520 0x3462 0x3404 0x33e6 0x33e1 0x3698 0x351a 0x3464 0x3405 0x33e7 0x33e2 0x3673 0x34ec 0x3468 0x3407 0x33e7 0x33e2 0x3669 0x34cb 0x346b 0x3409 0x33e7 0x33e2 0x3685 0x34c9 0x346d 0x340a 0x33e9 0x33e2 0x36a2 0x34c8 0x346f 0x340b 0x33eb 0x33e2 0x3679 0x34c5 0x346e 0x340d 0x33eb 0x33e3 0x3613 0x34c0 0x3466 0x3410 0x33eb 0x33e4 0x35eb 0x34b9 0x345f 0x3411 0x33eb 0x33e6 0x35e5 0x34b0 0x3459 0x3410 0x33ec 0x33e7 0x35e1 0x34a6 0x3453 0x340d 0x33ee 0x33e8 0x35dc 0x349e 0x344b 0x340c 0x33f1 0x33ea 0x35d7 0x3499 0x3440 0x340b 0x33f5 0x33ee 0x35d7 0x3492 0x3437 0x340a 0x33f7 0x33f0 0x35dc 0x3474 0x3430 0x3403 0x33f1 0x33ea 0x35e4 0x3448 0x342a 0x33fa 0x33e7 0x33e1 0x35f6 0x3432 0x3425 0x33f7 0x33e3 0x33de 0x3613 0x3425 0x3422 0x33f4 0x33e1 0x33dd 0x3632 0x3420 0x341d 0x33f3 0x33e0 0x33dd 0x3656 0x3427 0x33fc 0x33f3 0x33e0 0x33dd 0x3680 0x3439 0x33d2 0x33f3 0x33e2 0x33dd 0x36af 0x344f 0x33cb 0x33f2 0x33e2 0x33dd 0x36e4 0x346e 0x33cb 0x33f3 0x33e3 0x33dd 0x371e 0x3494 0x33ca 0x33f3 0x33e3 0x33dd 0x375e 0x34bf 0x33ca 0x33f2 0x33e3 0x33dd 0x37a3 0x34f2 0x33cb 0x33f2 0x33e3 0x33dd 0x37ee 0x352f 0x33cf 0x33f2 0x33e3 0x33dd 0x383e 0x357a 0x33e5 0x33f3 0x33e3 0x33de 0x3891 0x35d1 0x33f6 0x33f3 0x33e3 0x33de 0x38e8 0x3637 0x33ee 0x33f0 0x33e1 0x33dd 0x3942 0x36ac 0x33e1 0x33ec 0x33df 0x33dc 0x399e 0x3726 0x33e2 0x33ec 0x33de 0x33dc 0x3a02 0x37a7 0x33f3 0x33ec 0x33dd 0x33dd 0x3a73 0x3829 0x3407 0x33ed 0x33dd 0x33dd 0x3aea 0x38a6 0x341f 0x33ef 0x33dd 0x33de 0x3b5e 0x3920 0x3438 0x33f2 0x33dd 0x33de 0x3bc6 0x3991 0x345a 0x33f7 0x33de 0x33dc 0x3ba0 0x39e8 0x349e 0x33f8 0x33e0 0x33de 0x3c4f 0x39d1 0x34a4 0x33fb 0x33e4 0x33e0 0x3cc5 0x39e8 0x34cd 0x3404 0x33eb 0x33e6 0x3da7 0x3a2a 0x34f8 0x3407 0x33ec 0x33e7 0x3eba 0x3a71 0x3527 0x3414 0x33ef 0x33e7 0x4027 0x3aad 0x3561 0x3414 0x33ec 0x33e6 0x4227 0x3af7 0x3587 0x3415 0x33ee 0x33e6 0x4525 0x3b6f 0x35d3 0x341d 0x33f0 0x33e9 0x499f 0x3c16 0x366e 0x3426 0x33f3 0x33ec 0x509c 0x3cd3 0x373f 0x343a 0x33fc 0x33f3 0x509c 0x3cd3 0x373f 0x343a 0x33fc 0x33f3 0x509c 0x3cd3 0x373f 0x343a 0x33fc 0x33f3>;
        qcom,lut-col-legend = <0xfffffff6 0x00 0x0a 0x19 0x28 0x32>;
    };

    qcom,pc-temp-v1-lut {
        qcom,lut-row-legend = <0x2710 0x2648 0x2580 0x24b8 0x23f0 0x2328 0x2260 0x2198 0x20d0 0x2008 0x1f40 0x1e78 0x1db0 0x1ce8 0x1c20 0x1b58 0x1a90 0x19c8 0x1900 0x1838 0x1770 0x16a8 0x15e0 0x1518 0x1450 0x1388 0x12c0 0x11f8 0x1130 0x1068 0xfa0 0xed8 0xe10 0xd48 0xc80 0xbb8 0xaf0 0xa28 0x960 0x898 0x7d0 0x708 0x640 0x578 0x4b0 0x3e8 0x384 0x320 0x2bc 0x258 0x1f4 0x190 0x12c 0xc8 0x64 0x00>;
        qcom,lut-data = <0xa9e6 0xaaa2 0xab24 0xab59 0xab67 0xa8eb 0xa99c 0xaa3e 0xaa7d 0xaa8b 0xa7e8 0xa8a6 0xa956 0xa99a 0xa9aa 0xa6f1 0xa7bc 0xa86b 0xa8b7 0xa8c8 0xa60a 0xa6d6 0xa77e 0xa7ce 0xa7e2 0xa52f 0xa5ef 0xa691 0xa6e2 0xa6fa 0xa467 0xa50a 0xa5a7 0xa5f9 0xa612 0xa3af 0xa42b 0xa4bf 0xa50f 0xa529 0xa2ed 0xa34f 0xa3dc 0xa427 0xa442 0xa211 0xa278 0xa2fb 0xa342 0xa35e 0xa131 0xa1a5 0xa21e 0xa260 0xa27c 0xa06d 0xa0d8 0xa146 0xa184 0xa19e 0x9fc2 0xa016 0xa072 0xa0ab 0xa0c3 0x9f10 0x9f5f 0x9fa7 0x9fd9 0x9fee 0x9e35 0x9ea5 0x9ee1 0x9f0c 0x9f1f 0x9d4d 0x9dd5 0x9e22 0x9e46 0x9e56 0x9c98 0x9d01 0x9d67 0x9d89 0x9d97 0x9c13 0x9c56 0x9cb4 0x9cd4 0x9ce2 0x9b9a 0x9bd6 0x9c10 0x9c27 0x9c34 0x9b1c 0x9b55 0x9b7f 0x9b8a 0x9b93 0x9a9f 0x9a99 0x9add 0x9aeb 0x9af3 0x9a17 0x99b1 0x99fc 0x9a25 0x9a33 0x996d 0x98ec 0x9905 0x9935 0x9947 0x98b1 0x984f 0x984f 0x9866 0x9874 0x9812 0x97cc 0x97c3 0x97cc 0x97d4 0x978a 0x9766 0x974d 0x9748 0x974c 0x971b 0x9714 0x96e4 0x96d3 0x96d4 0x96cf 0x96ca 0x9687 0x966b 0x9669 0x9694 0x9681 0x9633 0x960e 0x9609 0x9665 0x963e 0x95e5 0x95b7 0x95ad 0x9642 0x9607 0x95a1 0x956b 0x955a 0x9625 0x95d8 0x9565 0x9526 0x9510 0x9605 0x95ad 0x9531 0x94e9 0x94cc 0x95de 0x9585 0x9503 0x94b3 0x948e 0x95b9 0x9560 0x94dd 0x9486 0x945c 0x959c 0x953b 0x94b5 0x9459 0x9429 0x9581 0x951a 0x948b 0x9421 0x93e7 0x955c 0x94f2 0x945c 0x93e1 0x9398 0x9512 0x94a9 0x9418 0x9395 0x9344 0x94ae 0x943a 0x93b8 0x933a 0x92e9 0x943b 0x93c6 0x9348 0x92d1 0x9283 0x93a9 0x9351 0x92ca 0x9257 0x9206 0x930c 0x92c7 0x923c 0x91ca 0x9177 0x9261 0x9212 0x9196 0x912a 0x90da 0x91c8 0x9183 0x9109 0x90a8 0x905f 0x9164 0x9129 0x90c2 0x9060 0x9023 0x9141 0x9109 0x90a9 0x904e 0x9010 0x9124 0x90ef 0x9096 0x903f 0x9001 0x9100 0x90ce 0x907c 0x9026 0x8fe3 0x9096 0x905d 0x9015 0x8f93 0x8f2c 0x8f4a 0x8ef1 0x8ec0 0x8e2e 0x8dbf 0x8d6c 0x8d0d 0x8ced 0x8c51 0x8bdf 0x8b0d 0x8a9e 0x8a94 0x89eb 0x896d 0x87d3 0x8746 0x8760 0x869c 0x8611 0x82b4 0x81ee 0x8263 0x8168 0x80bb 0x7530 0x7530 0x7530 0x7530 0x7530>;
        qcom,lut-col-legend = <0x00 0x0a 0x19 0x28 0x32>;
    };

    qcom,fcc2-temp-lut {
        qcom,lut-data = <0xb30 0xb1e 0xb2c 0xb34 0xb31 0xb31>;
        qcom,lut-col-legend = <0xfffffff6 0x00 0x0a 0x19 0x28 0x32>;
    };

    qcom,pc-temp-z3-lut {
        qcom,lut-row-legend = <0x2710 0x2648 0x2580 0x24b8 0x23f0 0x2328 0x2260 0x2198 0x20d0 0x2008 0x1f40 0x1e78 0x1db0 0x1ce8 0x1c20 0x1b58 0x1a90 0x19c8 0x1900 0x1838 0x1770 0x16a8 0x15e0 0x1518 0x1450 0x1388 0x12c0 0x11f8 0x1130 0x1068 0xfa0 0xed8 0xe10 0xd48 0xc80 0xbb8 0xaf0 0xa28 0x960 0x898 0x7d0 0x708 0x640 0x578 0x4b0 0x3e8 0x384 0x320 0x2bc 0x258 0x1f4 0x190 0x12c 0xc8 0x64 0x00>;
        qcom,lut-data = <0x4b6c 0x4b3a 0x4ba7 0x4ba9 0x4b91 0x4c6f 0x4c9b 0x4c07 0x4bc3 0x4baa 0x4d8a 0x4cf9 0x4c38 0x4bd3 0x4bb5 0x4dff 0x4d1c 0x4c40 0x4bd8 0x4bb9 0x4e13 0x4d25 0x4c3b 0x4bd6 0x4bb8 0x4e1c 0x4d17 0x4c33 0x4bcd 0x4bb3 0x4d94 0x4d01 0x4c2b 0x4bc8 0x4bad 0x4c1c 0x4cf2 0x4c24 0x4bc3 0x4ba9 0x4b58 0x4ce7 0x4c1b 0x4bbf 0x4ba5 0x4c34 0x4cdf 0x4c11 0x4bbc 0x4ba2 0x4d75 0x4cd9 0x4c0b 0x4bb6 0x4b9e 0x4d92 0x4cd3 0x4c07 0x4bb2 0x4b9d 0x4cde 0x4ccc 0x4c05 0x4bac 0x4b9b 0x4c6f 0x4cc0 0x4c05 0x4ba9 0x4b99 0x4cab 0x4cb9 0x4c07 0x4ba9 0x4b99 0x4cbf 0x4cbe 0x4c09 0x4ba8 0x4b9b 0x4c79 0x4cc6 0x4c02 0x4ba7 0x4b9b 0x4bd7 0x4cc5 0x4bf7 0x4ba6 0x4b91 0x4b44 0x4caf 0x4bf3 0x4ba5 0x4b89 0x4b3a 0x4c9d 0x4bf3 0x4ba5 0x4b89 0x4b3a 0x4ca7 0x4bf6 0x4ba6 0x4b89 0x4b3c 0x4cc4 0x4c03 0x4bae 0x4b8e 0x4bfa 0x4cd1 0x4c18 0x4bc1 0x4ba4 0x4d55 0x4cd2 0x4c26 0x4bcb 0x4bb3 0x4dcf 0x4cd3 0x4c32 0x4bca 0x4bb3 0x4dd4 0x4cd7 0x4c37 0x4bc8 0x4bb2 0x4dd7 0x4ce1 0x4c33 0x4bc8 0x4bae 0x4dd2 0x4ce6 0x4c2b 0x4bc8 0x4ba6 0x4dc2 0x4ce4 0x4c24 0x4bc7 0x4ba0 0x4db3 0x4ce0 0x4c1f 0x4bc5 0x4b9f 0x4d56 0x4cd9 0x4c1a 0x4bc1 0x4b9f 0x4cb7 0x4ccd 0x4c14 0x4bbe 0x4b9f 0x4c7b 0x4cc2 0x4c0e 0x4bba 0x4b9d 0x4c6e 0x4cbc 0x4c09 0x4bb6 0x4b9b 0x4c61 0x4cb7 0x4c04 0x4bb4 0x4b98 0x4c0c 0x4cb4 0x4c01 0x4bb2 0x4b94 0x4b74 0x4cae 0x4bff 0x4baf 0x4b92 0x4b3d 0x4ca8 0x4bfd 0x4bad 0x4b90 0x4b3e 0x4ca2 0x4bfa 0x4bab 0x4b8f 0x4b3f 0x4c99 0x4bf3 0x4ba9 0x4b91 0x4b40 0x4c78 0x4bed 0x4ba8 0x4b93 0x4b43 0x4ba7 0x4beb 0x4ba8 0x4b96 0x4b45 0x4b3d 0x4be8 0x4ba7 0x4b99 0x4b46 0x4b3c 0x4bdd 0x4ba5 0x4b99 0x4b4a 0x4b39 0x4bd5 0x4ba1 0x4b9a 0x4b4e 0x4b39 0x4ba8 0x4b9a 0x4b84 0x4b4e 0x4b39 0x4ba7 0x4b92 0x4b84 0x4b4f 0x4b39 0x4ba2 0x4b83 0x4b7b 0x4b52 0x4b39 0x4ba8 0x4b7e 0x4b7f 0x4b54 0x4b39 0x4b9a 0x4b8a 0x4b96 0x4b57 0x4b39 0x4ba1 0x4b92 0x4b94 0x4b5a 0x4b39 0x4ba8 0x4b9c 0x4b93 0x4b5f 0x4b39 0x4baa 0x4b99 0x4b9c 0x4b6c 0x4b3a 0x4bc0 0x4bb6 0x4bad 0x4b6c 0x4b3a 0x4bc0 0x4bb6 0x4bad 0x4b6c 0x4b3a 0x4bc0 0x4bb6 0x4bad>;
        qcom,lut-col-legend = <0x00 0x0a 0x19 0x28 0x32>;
    };

    qcom,pc-temp-y6-lut {
        qcom,lut-row-legend = <0x2710 0x2648 0x2580 0x24b8 0x23f0 0x2328 0x2260 0x2198 0x20d0 0x2008 0x1f40 0x1e78 0x1db0 0x1ce8 0x1c20 0x1b58 0x1a90 0x19c8 0x1900 0x1838 0x1770 0x16a8 0x15e0 0x1518 0x1450 0x1388 0x12c0 0x11f8 0x1130 0x1068 0xfa0 0xed8 0xe10 0xd48 0xc80 0xbb8 0xaf0 0xa28 0x960 0x898 0x7d0 0x708 0x640 0x578 0x4b0 0x3e8 0x384 0x320 0x2bc 0x258 0x1f4 0x190 0x12c 0xc8 0x64 0x00>;
        qcom,lut-data = <0x1d2b 0x17f4 0x15a2 0x1426 0x13bf 0x13a3 0x1cfa 0x1820 0x15ae 0x1426 0x13bd 0x13a2 0x1ccb 0x183d 0x15b5 0x1426 0x13ba 0x13a1 0x1c9e 0x184f 0x15b9 0x1425 0x13b8 0x13a1 0x1c73 0x1858 0x15ba 0x1424 0x13b6 0x13a1 0x1c4a 0x185a 0x15ba 0x1422 0x13b6 0x13a1 0x1c1a 0x1853 0x15b3 0x1420 0x13b6 0x13a1 0x1bf7 0x1843 0x15a4 0x141e 0x13b7 0x13a2 0x1bff 0x182f 0x159b 0x141d 0x13b7 0x13a3 0x1c22 0x1811 0x1592 0x141d 0x13b8 0x13a4 0x1c30 0x1800 0x158f 0x141d 0x13b9 0x13a5 0x1c1b 0x181a 0x1590 0x141e 0x13bb 0x13a6 0x1bf3 0x1846 0x1592 0x141f 0x13bd 0x13a7 0x1ba3 0x183f 0x1593 0x1422 0x13bf 0x13a9 0x1b29 0x17e7 0x1593 0x1428 0x13c2 0x13ab 0x1af3 0x17aa 0x1592 0x142f 0x13c5 0x13ae 0x1ae4 0x17ac 0x1594 0x1434 0x13c9 0x13b1 0x1ad8 0x17b1 0x1597 0x1439 0x13ce 0x13b5 0x1ac5 0x17a6 0x1591 0x1444 0x13d7 0x13bc 0x1ab2 0x1762 0x156f 0x1458 0x13e7 0x13c8 0x1aac 0x1723 0x1549 0x1460 0x13ee 0x13ce 0x1aaa 0x1704 0x1525 0x1440 0x13db 0x13c0 0x1aa9 0x16ef 0x1505 0x1412 0x13c0 0x13ab 0x1ab7 0x16ec 0x14f5 0x1402 0x13b5 0x13a4 0x1ad3 0x16f0 0x14eb 0x13fa 0x13b0 0x13a0 0x1aed 0x16f6 0x14e5 0x13f7 0x13ae 0x139f 0x1b0b 0x1707 0x14df 0x13f8 0x13af 0x139f 0x1b2c 0x1726 0x14db 0x13f9 0x13b0 0x13a0 0x1b4f 0x1748 0x14db 0x13fb 0x13b2 0x13a2 0x1b76 0x176f 0x14de 0x13fe 0x13b5 0x13a4 0x1ba2 0x179c 0x14e2 0x1401 0x13b8 0x13a7 0x1bd2 0x17d0 0x14ea 0x1404 0x13bd 0x13aa 0x1c07 0x180c 0x14f7 0x1406 0x13c1 0x13ae 0x1c40 0x184e 0x1507 0x1407 0x13c3 0x13af 0x1c7d 0x1899 0x151d 0x1407 0x13c4 0x13af 0x1cbd 0x18ec 0x1536 0x1407 0x13c2 0x13ae 0x1d01 0x1946 0x1552 0x1404 0x13b9 0x13a8 0x1d47 0x19a8 0x1573 0x1400 0x13b1 0x13a3 0x1d8f 0x1a0b 0x159a 0x1401 0x13b0 0x13a3 0x1ddb 0x1a70 0x15cb 0x1407 0x13b1 0x13a3 0x1e2f 0x1ad3 0x1600 0x140d 0x13b2 0x13a4 0x1e88 0x1b33 0x1639 0x1418 0x13b4 0x13a4 0x1ee4 0x1b8d 0x1677 0x1423 0x13b4 0x13a4 0x1f3a 0x1bdf 0x16b9 0x142f 0x13b3 0x13a0 0x1f17 0x1c26 0x1711 0x143d 0x13b6 0x13a2 0x1fa0 0x1c18 0x1721 0x1444 0x13c0 0x13aa 0x2003 0x1c2e 0x1758 0x1455 0x13c7 0x13b4 0x20dc 0x1c70 0x1792 0x1463 0x13d0 0x13bf 0x21e6 0x1cb6 0x17d0 0x1480 0x13db 0x13bf 0x2347 0x1ced 0x180b 0x1484 0x13cd 0x13b3 0x2531 0x1d1e 0x1834 0x1489 0x13d2 0x13b6 0x280b 0x1d6f 0x188a 0x14a5 0x13dc 0x13bd 0x2c58 0x1df2 0x192a 0x14c8 0x13ec 0x13cd 0x3313 0x1ea6 0x19f6 0x1509 0x141c 0x1403 0x3313 0x1ea6 0x19f6 0x1509 0x141c 0x1403 0x3313 0x1ea6 0x19f6 0x1509 0x141c 0x1403>;
        qcom,lut-col-legend = <0xfffffff6 0x00 0x0a 0x19 0x28 0x32>;
    };

    qcom,pc-temp-y2-lut {
        qcom,lut-row-legend = <0x2710 0x2648 0x2580 0x24b8 0x23f0 0x2328 0x2260 0x2198 0x20d0 0x2008 0x1f40 0x1e78 0x1db0 0x1ce8 0x1c20 0x1b58 0x1a90 0x19c8 0x1900 0x1838 0x1770 0x16a8 0x15e0 0x1518 0x1450 0x1388 0x12c0 0x11f8 0x1130 0x1068 0xfa0 0xed8 0xe10 0xd48 0xc80 0xbb8 0xaf0 0xa28 0x960 0x898 0x7d0 0x708 0x640 0x578 0x4b0 0x3e8 0x384 0x320 0x2bc 0x258 0x1f4 0x190 0x12c 0xc8 0x64 0x00>;
        qcom,lut-data = <0x25b6 0x25ab 0x298f 0x2b3e 0x2b71 0x2b4e 0x25b6 0x25ab 0x29a6 0x2b30 0x2b59 0x2b32 0x25b7 0x25ab 0x29b3 0x2b1d 0x2b37 0x2b15 0x25b7 0x268f 0x29b8 0x2b06 0x2b13 0x2af9 0x25b8 0x27ce 0x29b8 0x2aec 0x2af5 0x2ae0 0x25b8 0x2855 0x29b5 0x2acf 0x2ae5 0x2ace 0x25b9 0x2844 0x29a8 0x2aa6 0x2add 0x2ac2 0x25b9 0x282a 0x2994 0x2a81 0x2ad7 0x2ab7 0x25b9 0x283d 0x2988 0x2a7b 0x2acf 0x2aa4 0x25ba 0x28c8 0x297f 0x2a7a 0x2ab5 0x2a82 0x25ba 0x2926 0x297b 0x2a7a 0x2aa7 0x2a70 0x25ba 0x28f9 0x2982 0x2a75 0x2ab8 0x2a7a 0x25bb 0x28b1 0x2993 0x2a6d 0x2ad1 0x2a88 0x25ba 0x28ad 0x29b4 0x2a68 0x2ac8 0x2a85 0x25b9 0x28f7 0x29fc 0x2a63 0x2a91 0x2a6c 0x25b9 0x2939 0x2a31 0x2a63 0x2a72 0x2a58 0x25b9 0x2954 0x2a4a 0x2a85 0x2a7c 0x2a55 0x25b9 0x2965 0x2a5b 0x2ac2 0x2a90 0x2a5d 0x25b9 0x2919 0x2a5a 0x2b0a 0x2abf 0x2a84 0x25b8 0x273a 0x2a46 0x2b6b 0x2b34 0x2ae8 0x25b8 0x25e0 0x2a39 0x2b97 0x2b70 0x2b1a 0x25b8 0x25d2 0x2a3f 0x2b79 0x2b5a 0x2b05 0x25b8 0x25cc 0x2a4a 0x2b53 0x2b3f 0x2aeb 0x25b8 0x25cb 0x2a53 0x2b4d 0x2b47 0x2b01 0x25b8 0x25cc 0x2a5e 0x2b50 0x2b71 0x2b62 0x25b7 0x25cc 0x2a60 0x2b55 0x2b92 0x2b9a 0x25b7 0x25cb 0x29bc 0x2b64 0x2ba8 0x2b9e 0x25b7 0x25c7 0x28dc 0x2b7a 0x2bbf 0x2ba0 0x25b7 0x25c4 0x299c 0x2b90 0x2bd8 0x2bae 0x25b6 0x25c1 0x2d2d 0x2baa 0x2bff 0x2bce 0x25b6 0x25be 0x2f25 0x2bb8 0x2c16 0x2be6 0x25b6 0x25bc 0x2e14 0x2bbf 0x2c2e 0x2bf9 0x25b6 0x25bb 0x2c37 0x2bc3 0x2c4a 0x2c0d 0x25b6 0x25b9 0x2ad3 0x2bc2 0x2c50 0x2c2b 0x25b6 0x25b8 0x2993 0x2bbe 0x2c38 0x2c51 0x25b6 0x25b7 0x28b7 0x2bb5 0x2c23 0x2c5f 0x25b5 0x25b6 0x279c 0x2b8c 0x2c1e 0x2c3d 0x25b5 0x25b5 0x2664 0x2b64 0x2c25 0x2c10 0x25b5 0x25b5 0x2605 0x2b5b 0x2c25 0x2c07 0x25b5 0x25b5 0x25eb 0x2b58 0x2c1a 0x2c0e 0x25b5 0x25b4 0x25dc 0x2b3f 0x2c17 0x2c0d 0x25b5 0x25b4 0x25d1 0x2adf 0x2c41 0x2bf2 0x25b5 0x25b4 0x25ca 0x2abb 0x2c5c 0x2bdf 0x25b5 0x25b4 0x25c4 0x2aa1 0x2c27 0x2bdd 0x25b5 0x25b4 0x25c0 0x2a32 0x2bf5 0x2b7f 0x25b5 0x25b4 0x25bf 0x2a57 0x2bac 0x2b24 0x25b5 0x25b4 0x25bd 0x2a50 0x2b8a 0x2b01 0x25b4 0x25b4 0x25bc 0x2a3b 0x2b61 0x2ad2 0x25b4 0x25b3 0x25bb 0x2a2a 0x2b35 0x2ad5 0x25b3 0x25b3 0x25ba 0x2a0c 0x2b2d 0x2aba 0x25b2 0x25b3 0x25ba 0x29d7 0x2ae5 0x2a77 0x25b2 0x25b3 0x25b8 0x299b 0x2aaf 0x2a4d 0x25b1 0x25b3 0x25b6 0x2962 0x2a63 0x29fb 0x25b0 0x25b3 0x25b6 0x2923 0x2a2e 0x29a3 0x25b0 0x25b3 0x25b6 0x2923 0x2a2e 0x29a3 0x25b0 0x25b3 0x25b6 0x2923 0x2a2e 0x29a3>;
        qcom,lut-col-legend = <0xfffffff6 0x00 0x0a 0x19 0x28 0x32>;
    };

    qcom,pc-temp-z6-lut {
        qcom,lut-row-legend = <0x2710 0x2648 0x2580 0x24b8 0x23f0 0x2328 0x2260 0x2198 0x20d0 0x2008 0x1f40 0x1e78 0x1db0 0x1ce8 0x1c20 0x1b58 0x1a90 0x19c8 0x1900 0x1838 0x1770 0x16a8 0x15e0 0x1518 0x1450 0x1388 0x12c0 0x11f8 0x1130 0x1068 0xfa0 0xed8 0xe10 0xd48 0xc80 0xbb8 0xaf0 0xa28 0x960 0x898 0x7d0 0x708 0x640 0x578 0x4b0 0x3e8 0x384 0x320 0x2bc 0x258 0x1f4 0x190 0x12c 0xc8 0x64 0x00>;
        qcom,lut-data = <0x4285 0x3e1d 0x3b13 0x39d7 0x3983 0x4304 0x3e96 0x3b3d 0x39fc 0x399e 0x42b9 0x3e76 0x3b1b 0x39df 0x398e 0x4251 0x3deb 0x3af2 0x39bc 0x3977 0x41b2 0x3d68 0x3abf 0x39ae 0x396c 0x4105 0x3d0e 0x3a98 0x39a4 0x3965 0x4066 0x3cc8 0x3a82 0x399a 0x395e 0x3fcb 0x3c9f 0x3a72 0x3991 0x3958 0x3f7f 0x3c82 0x3a61 0x3988 0x3952 0x3f74 0x3c6c 0x3a51 0x3980 0x394c 0x3f6e 0x3c5c 0x3a44 0x3978 0x3946 0x3f59 0x3c4e 0x3a39 0x3970 0x3940 0x3f2c 0x3c3e 0x3a31 0x3969 0x393b 0x3f0b 0x3c29 0x3a2b 0x3963 0x3936 0x3f12 0x3c1e 0x3a27 0x395e 0x3932 0x3f26 0x3c23 0x3a23 0x3959 0x392e 0x3f23 0x3c2b 0x3a1c 0x3955 0x3929 0x3ef8 0x3c2a 0x3a12 0x3950 0x3923 0x3ecc 0x3c0c 0x3a0e 0x394e 0x391e 0x3ebf 0x3bf1 0x3a0e 0x394e 0x391d 0x3eb9 0x3c14 0x3a11 0x394f 0x391d 0x3eb7 0x3c78 0x3a43 0x395c 0x3925 0x3edc 0x3cad 0x3a8f 0x398c 0x394c 0x3f28 0x3cb7 0x3a9e 0x39a5 0x3964 0x3f5a 0x3cbd 0x3a90 0x39a1 0x3963 0x3f7b 0x3cb5 0x3a80 0x399a 0x395f 0x3f8e 0x3c97 0x3a74 0x3995 0x395b 0x3f8a 0x3c80 0x3a6a 0x398f 0x3954 0x3f76 0x3c77 0x3a64 0x398a 0x394f 0x3f63 0x3c71 0x3a60 0x3986 0x394a 0x3f4c 0x3c6b 0x3a5e 0x3982 0x3946 0x3f30 0x3c63 0x3a5d 0x397f 0x3943 0x3f24 0x3c5e 0x3a5b 0x397c 0x3941 0x3f1f 0x3c5d 0x3a5a 0x397b 0x393e 0x3f1a 0x3c5d 0x3a59 0x397a 0x393b 0x3f11 0x3c5d 0x3a58 0x397a 0x3939 0x3f05 0x3c5a 0x3a5b 0x397d 0x393c 0x3f02 0x3c57 0x3a5f 0x3985 0x3946 0x3f05 0x3c59 0x3a5f 0x3987 0x3949 0x3f0b 0x3c5e 0x3a5c 0x3985 0x3948 0x3f13 0x3c5e 0x3a58 0x3983 0x3947 0x3f21 0x3c45 0x3a51 0x397e 0x3946 0x3f2b 0x3c39 0x3a4a 0x3978 0x3946 0x3f32 0x3c40 0x3a46 0x3979 0x3948 0x3f22 0x3c30 0x3a3d 0x3974 0x3947 0x3f25 0x3c27 0x3a23 0x3966 0x3933 0x3f28 0x3c26 0x3a1b 0x395c 0x3929 0x3f2c 0x3c29 0x3a13 0x394e 0x391e 0x3f33 0x3c2d 0x3a12 0x3949 0x391a 0x3f41 0x3c41 0x3a21 0x395a 0x3931 0x3f64 0x3c5b 0x3a2c 0x3962 0x3935 0x3f86 0x3c6c 0x3a36 0x3967 0x393a 0x3fac 0x3c89 0x3a40 0x396c 0x3941 0x3fe9 0x3caf 0x3a52 0x397c 0x3950 0x3fe9 0x3caf 0x3a52 0x397c 0x3950 0x3fe9 0x3caf 0x3a52 0x397c 0x3950>;
        qcom,lut-col-legend = <0x00 0x0a 0x19 0x28 0x32>;
    };

    qcom,pc-temp-z2-lut {
        qcom,lut-row-legend = <0x2710 0x2648 0x2580 0x24b8 0x23f0 0x2328 0x2260 0x2198 0x20d0 0x2008 0x1f40 0x1e78 0x1db0 0x1ce8 0x1c20 0x1b58 0x1a90 0x19c8 0x1900 0x1838 0x1770 0x16a8 0x15e0 0x1518 0x1450 0x1388 0x12c0 0x11f8 0x1130 0x1068 0xfa0 0xed8 0xe10 0xd48 0xc80 0xbb8 0xaf0 0xa28 0x960 0x898 0x7d0 0x708 0x640 0x578 0x4b0 0x3e8 0x384 0x320 0x2bc 0x258 0x1f4 0x190 0x12c 0xc8 0x64 0x00>;
        qcom,lut-data = <0x236e 0x2bcd 0x2818 0x286d 0x283b 0x24bb 0x27e3 0x2824 0x2892 0x2849 0x2662 0x2784 0x2866 0x28be 0x2852 0x26ff 0x2782 0x287a 0x28cf 0x286e 0x26fa 0x2783 0x2880 0x28c5 0x2866 0x26ef 0x2788 0x2884 0x28a7 0x282a 0x2676 0x278e 0x2883 0x2899 0x27fd 0x253e 0x2794 0x2880 0x2894 0x27e9 0x249c 0x2799 0x287d 0x288e 0x27de 0x2566 0x279d 0x287d 0x288a 0x27e0 0x2691 0x279f 0x287d 0x2892 0x27e8 0x26d4 0x27a1 0x2875 0x2890 0x27f7 0x26b4 0x27a3 0x286a 0x2882 0x2821 0x26a2 0x27a4 0x2868 0x2875 0x2846 0x2688 0x27a5 0x2870 0x2871 0x2855 0x2615 0x27a3 0x2872 0x2871 0x2860 0x25f2 0x27a0 0x286b 0x2873 0x2866 0x2755 0x27a2 0x2867 0x2878 0x2867 0x2922 0x27ac 0x2868 0x287e 0x2868 0x298d 0x27b6 0x2867 0x288a 0x2871 0x2987 0x27aa 0x2868 0x289c 0x287b 0x296d 0x2787 0x2886 0x28a5 0x2878 0x2898 0x2777 0x28af 0x28ac 0x2856 0x274d 0x2786 0x28ae 0x28ae 0x2836 0x26e6 0x2797 0x2883 0x28a2 0x281a 0x26ea 0x2794 0x2863 0x2893 0x2801 0x26f0 0x2785 0x285f 0x2889 0x2801 0x26f3 0x277b 0x2861 0x2878 0x280d 0x26f7 0x277d 0x2866 0x2871 0x281e 0x26f9 0x2780 0x286f 0x2885 0x283b 0x267f 0x2784 0x2877 0x289d 0x285a 0x259c 0x278b 0x287a 0x289e 0x2867 0x255b 0x2793 0x287d 0x2895 0x286d 0x257d 0x279f 0x2882 0x2898 0x287e 0x25af 0x27af 0x288b 0x28cb 0x28af 0x25f2 0x27b6 0x2895 0x2903 0x28e0 0x2651 0x27b9 0x289d 0x2918 0x28f6 0x2674 0x27bc 0x28a5 0x2925 0x290f 0x261c 0x27ca 0x28c0 0x2934 0x2923 0x259f 0x27e4 0x2909 0x295a 0x2943 0x2545 0x27f1 0x2937 0x297d 0x295b 0x24e5 0x27b1 0x292a 0x298d 0x292c 0x24a2 0x27a0 0x291f 0x2996 0x28e4 0x2477 0x2852 0x292b 0x2973 0x28ff 0x2435 0x3442 0x293a 0x2983 0x28fb 0x2402 0x3819 0x28eb 0x2985 0x2926 0x2404 0x39ca 0x28e5 0x2992 0x295c 0x23fc 0x3ade 0x2900 0x299b 0x295a 0x23e4 0x35d9 0x28e5 0x29f3 0x2997 0x23d2 0x33a3 0x297e 0x29c6 0x28da 0x23bf 0x316c 0x299f 0x293d 0x2855 0x23af 0x2fcc 0x2972 0x28ff 0x2820 0x239c 0x2d7c 0x2900 0x28c0 0x27d3 0x2379 0x2b13 0x28d8 0x283c 0x279b 0x2379 0x2b13 0x28d8 0x283c 0x279b 0x2379 0x2b13 0x28d8 0x283c 0x279b>;
        qcom,lut-col-legend = <0x00 0x0a 0x19 0x28 0x32>;
    };

    qcom,fcc1-temp-lut {
        qcom,lut-data = <0xa9b 0xae4 0xb2d 0xb52 0xb5c>;
        qcom,lut-col-legend = <0x00 0x0a 0x19 0x28 0x32>;
    };

    qcom,pc-temp-y5-lut {
        qcom,lut-row-legend = <0x2710 0x2648 0x2580 0x24b8 0x23f0 0x2328 0x2260 0x2198 0x20d0 0x2008 0x1f40 0x1e78 0x1db0 0x1ce8 0x1c20 0x1b58 0x1a90 0x19c8 0x1900 0x1838 0x1770 0x16a8 0x15e0 0x1518 0x1450 0x1388 0x12c0 0x11f8 0x1130 0x1068 0xfa0 0xed8 0xe10 0xd48 0xc80 0xbb8 0xaf0 0xa28 0x960 0x898 0x7d0 0x708 0x640 0x578 0x4b0 0x3e8 0x384 0x320 0x2bc 0x258 0x1f4 0x190 0x12c 0xc8 0x64 0x00>;
        qcom,lut-data = <0x272e 0x2208 0x378f 0x39b6 0x4de7 0x3fb4 0x28d0 0x22b8 0x380d 0x3b2c 0x48eb 0x3ddb 0x2a2a 0x2942 0x38be 0x3c05 0x4271 0x3c61 0x2b2e 0x2fac 0x3979 0x3c6a 0x3bf9 0x3b48 0x2bce 0x350b 0x3a13 0x3c81 0x3706 0x3a95 0x2bfc 0x3874 0x3a64 0x3c70 0x3519 0x3a48 0x2b87 0x3a64 0x3a7d 0x3be7 0x35e8 0x3a9b 0x2af9 0x3ba6 0x3a8a 0x3b2f 0x372b 0x3b28 0x2b8f 0x3ab4 0x3a8a 0x3afa 0x3726 0x3aef 0x2e4a 0x343a 0x3a7d 0x3ad0 0x3602 0x397c 0x3247 0x2fd6 0x3a52 0x3a82 0x3560 0x37eb 0x3b54 0x3429 0x37cf 0x3997 0x35dc 0x3689 0x42cc 0x3b3b 0x344a 0x383e 0x362e 0x3542 0x3daa 0x3c87 0x3416 0x36fe 0x354b 0x34aa 0x3097 0x3b5d 0x361d 0x35ac 0x3387 0x34ed 0x2c8e 0x3a91 0x380a 0x34b9 0x3257 0x3546 0x2d1b 0x3c53 0x3950 0x3397 0x31f9 0x34ea 0x2d8e 0x3f3f 0x3a9e 0x327b 0x31fc 0x346f 0x2d36 0x3f0a 0x3c39 0x32cc 0x32c9 0x34ec 0x2c64 0x3974 0x3e7a 0x3556 0x3501 0x36d1 0x2bad 0x33e4 0x4023 0x3862 0x3771 0x3868 0x2aea 0x3137 0x411e 0x3c83 0x3a39 0x39ea 0x2a53 0x2f24 0x41c0 0x4031 0x3cb5 0x3b38 0x29ee 0x2d18 0x41bb 0x4104 0x3d22 0x3b5c 0x29aa 0x2ad2 0x412a 0x40cf 0x3bca 0x3bf2 0x299f 0x299f 0x4006 0x40ee 0x3ac8 0x3c72 0x299e 0x2998 0x3805 0x40d5 0x3bbd 0x3c86 0x299e 0x2995 0x2dd0 0x409c 0x3d80 0x3c70 0x29c1 0x29a9 0x2b94 0x40c2 0x3df9 0x3b7d 0x29ee 0x2a32 0x2b18 0x4137 0x3d85 0x3947 0x29f9 0x2ac2 0x2acf 0x4174 0x3cf7 0x3810 0x2a0d 0x2b09 0x2a95 0x41bf 0x3c8e 0x37d2 0x2a2d 0x2b44 0x2a71 0x423f 0x3c28 0x37e7 0x2a82 0x2ba9 0x2b2e 0x43d3 0x3d59 0x3949 0x2ac9 0x2c67 0x2fa4 0x46b1 0x40bd 0x3d7c 0x2abc 0x2d00 0x32d3 0x4786 0x4217 0x4028 0x2a91 0x2d40 0x30d0 0x4375 0x40ec 0x3ff8 0x2a6f 0x2d6b 0x2d52 0x3e2a 0x3edb 0x3f57 0x2a53 0x2d6e 0x2cde 0x3b6d 0x3c58 0x3fc7 0x2a44 0x2d4b 0x2da1 0x396c 0x3964 0x409f 0x2a73 0x2d32 0x2e0b 0x37fa 0x381d 0x40a6 0x2acb 0x2d3b 0x2e15 0x3719 0x37a3 0x3f83 0x2b16 0x2d4c 0x2e02 0x378b 0x3781 0x3fda 0x2b15 0x2cf5 0x2d7f 0x3913 0x3ad2 0x41fd 0x2b24 0x2c43 0x2e03 0x3776 0x3a22 0x3ffe 0x2b87 0x2c7c 0x2cf4 0x374c 0x3a22 0x38fd 0x2c39 0x2ce0 0x2d86 0x390b 0x3e8c 0x3f0e 0x2c5c 0x2ce5 0x2d8e 0x36b1 0x3ac0 0x3a70 0x2bc6 0x2d5d 0x2ea3 0x3a46 0x3c27 0x39ec 0x2ab4 0x2de3 0x31b6 0x3c4f 0x42c5 0x43af 0x292b 0x2d91 0x316f 0x3e6d 0x4559 0x4367 0x2817 0x2d41 0x2ff8 0x3fa0 0x45d9 0x4628 0x270a 0x2cc3 0x2f56 0x3f0d 0x441c 0x4718 0x25c4 0x2e2a 0x2e9c 0x3eda 0x43c8 0x45a1 0x25c4 0x2e2a 0x2e9c 0x3eda 0x43c8 0x45a1 0x25c4 0x2e2a 0x2e9c 0x3eda 0x43c8 0x45a1>;
        qcom,lut-col-legend = <0xfffffff6 0x00 0x0a 0x19 0x28 0x32>;
    };

    qcom,pc-temp-y1-lut {
        qcom,lut-row-legend = <0x2710 0x2648 0x2580 0x24b8 0x23f0 0x2328 0x2260 0x2198 0x20d0 0x2008 0x1f40 0x1e78 0x1db0 0x1ce8 0x1c20 0x1b58 0x1a90 0x19c8 0x1900 0x1838 0x1770 0x16a8 0x15e0 0x1518 0x1450 0x1388 0x12c0 0x11f8 0x1130 0x1068 0xfa0 0xed8 0xe10 0xd48 0xc80 0xbb8 0xaf0 0xa28 0x960 0x898 0x7d0 0x708 0x640 0x578 0x4b0 0x3e8 0x384 0x320 0x2bc 0x258 0x1f4 0x190 0x12c 0xc8 0x64 0x00>;
        qcom,lut-data = <0x1ef9 0x1a30 0x17a2 0x15be 0x14ca 0x1473 0x1f5c 0x1a2d 0x17a2 0x15b8 0x14c8 0x1472 0x1fa5 0x1a25 0x17a3 0x15b2 0x14c6 0x1471 0x1fd7 0x1a1c 0x17a3 0x15ac 0x14c4 0x146f 0x1ff3 0x1a14 0x17a4 0x15a7 0x14c1 0x146e 0x1ffa 0x1a11 0x17a5 0x15a4 0x14bf 0x146c 0x1fdd 0x1a0b 0x17a6 0x15a3 0x14bc 0x1469 0x1fb8 0x1a03 0x17a6 0x15a2 0x14b9 0x1466 0x1fae 0x1a07 0x17a7 0x15a0 0x14b6 0x1466 0x1fa8 0x1a25 0x17a8 0x1599 0x14b3 0x1466 0x1fa3 0x1a3d 0x17a7 0x1595 0x14b2 0x1466 0x1fb8 0x1a3c 0x17a2 0x1595 0x14b1 0x1464 0x1fd2 0x1a33 0x179c 0x1596 0x14b0 0x1461 0x1fd3 0x1a32 0x179c 0x1598 0x14af 0x1460 0x1fd3 0x1a33 0x17a1 0x159d 0x14ad 0x1461 0x1fd2 0x1a35 0x17a4 0x15a0 0x14ab 0x1461 0x1fc7 0x1a31 0x17a5 0x159e 0x14aa 0x1463 0x1fb7 0x1a2b 0x17a7 0x159c 0x14a8 0x1465 0x1fa4 0x1a2c 0x17a9 0x159c 0x14a9 0x1465 0x1f8f 0x1a34 0x17ae 0x159b 0x14aa 0x1464 0x1f86 0x1a3b 0x17b1 0x159b 0x14ac 0x1463 0x1f86 0x1a38 0x17b3 0x159c 0x14ae 0x1464 0x1f8c 0x1a32 0x17b7 0x159c 0x14b0 0x1466 0x1fb5 0x1a2f 0x17b7 0x159c 0x14b1 0x1467 0x1fea 0x1a2e 0x17b6 0x159c 0x14b2 0x1469 0x1fe7 0x1a2e 0x17b5 0x159c 0x14b3 0x146b 0x1fb6 0x1a2c 0x17b4 0x159f 0x14b5 0x146d 0x1f94 0x1a2b 0x17b1 0x15a3 0x14b9 0x1470 0x1f97 0x1a29 0x17ae 0x15a4 0x14bd 0x1474 0x1fa4 0x1a23 0x17ab 0x15a5 0x14bf 0x1478 0x1f9c 0x1a20 0x17ab 0x15a6 0x14c2 0x147b 0x1f7b 0x1a23 0x17af 0x15aa 0x14c5 0x147c 0x1f6b 0x1a27 0x17b5 0x15ae 0x14c8 0x147d 0x1f5b 0x1a25 0x17b8 0x15b1 0x14cc 0x147f 0x1f4b 0x1a15 0x17bd 0x15b4 0x14d1 0x1483 0x1f55 0x1a0b 0x17c0 0x15b6 0x14d5 0x1487 0x1f72 0x1a17 0x17c1 0x15bb 0x14d8 0x148a 0x1f92 0x1a29 0x17c2 0x15c0 0x14db 0x148d 0x1fbb 0x1a2a 0x17c5 0x15c2 0x14de 0x148f 0x1fd4 0x1a1c 0x17ce 0x15c3 0x14e4 0x1491 0x1fa5 0x1a13 0x17d5 0x15c4 0x14e8 0x1494 0x1f69 0x1a23 0x17d2 0x15cd 0x14e9 0x1497 0x1fa8 0x1a33 0x17d0 0x15d2 0x14ec 0x149b 0x1f98 0x1a30 0x17d6 0x15d2 0x14f3 0x14a2 0x1f70 0x1a34 0x17d8 0x15d9 0x14f8 0x14a4 0x1f77 0x1a45 0x17d2 0x15db 0x14fa 0x14a8 0x1f7b 0x1a44 0x17e2 0x15e1 0x14fa 0x14a8 0x1f9c 0x1a57 0x17c9 0x15de 0x1500 0x14aa 0x1fdd 0x1a5e 0x17c6 0x15e5 0x14fe 0x14ab 0x2005 0x1a42 0x17d8 0x15e9 0x1505 0x14ad 0x204d 0x1a52 0x17d9 0x15e8 0x1508 0x14ac 0x2060 0x1a67 0x17e0 0x15f8 0x1510 0x14b8 0x20bc 0x1a6e 0x17f0 0x160b 0x1518 0x14c1 0x20e6 0x1a7b 0x1805 0x1618 0x1529 0x14cc 0x20e6 0x1a7b 0x1805 0x1618 0x1529 0x14cc 0x20e6 0x1a7b 0x1805 0x1618 0x1529 0x14cc>;
        qcom,lut-col-legend = <0xfffffff6 0x00 0x0a 0x19 0x28 0x32>;
    };

    qcom,pc-temp-z5-lut {
        qcom,lut-row-legend = <0x2710 0x2648 0x2580 0x24b8 0x23f0 0x2328 0x2260 0x2198 0x20d0 0x2008 0x1f40 0x1e78 0x1db0 0x1ce8 0x1c20 0x1b58 0x1a90 0x19c8 0x1900 0x1838 0x1770 0x16a8 0x15e0 0x1518 0x1450 0x1388 0x12c0 0x11f8 0x1130 0x1068 0xfa0 0xed8 0xe10 0xd48 0xc80 0xbb8 0xaf0 0xa28 0x960 0x898 0x7d0 0x708 0x640 0x578 0x4b0 0x3e8 0x384 0x320 0x2bc 0x258 0x1f4 0x190 0x12c 0xc8 0x64 0x00>;
        qcom,lut-data = <0x2a0c 0x2acd 0x2f4e 0x35e2 0x3566 0x2de1 0x327d 0x3576 0x39b0 0x3a81 0x31ac 0x36ba 0x399a 0x3eb8 0x403d 0x345c 0x397e 0x3ca1 0x4168 0x43d1 0x3651 0x3bd9 0x3f34 0x4195 0x4407 0x3778 0x3e3d 0x40a1 0x40b8 0x430e 0x352b 0x4047 0x410d 0x4024 0x422c 0x2e5d 0x415a 0x4146 0x3fec 0x41c6 0x2ae2 0x41ff 0x413b 0x4011 0x417b 0x30e9 0x42a6 0x40d2 0x4012 0x4113 0x39bf 0x43a3 0x40a5 0x3fa4 0x40cb 0x3aa3 0x4463 0x4110 0x3f32 0x40fa 0x35fb 0x4452 0x41cd 0x3e83 0x4182 0x334e 0x4477 0x42cc 0x3e69 0x422f 0x35ff 0x44e6 0x4482 0x3f1f 0x441b 0x3770 0x44da 0x457a 0x4029 0x47f5 0x355c 0x444a 0x4495 0x4153 0x48c8 0x2fa2 0x43e8 0x4366 0x42eb 0x4455 0x2a7d 0x4427 0x43d6 0x4399 0x409e 0x2a2b 0x4528 0x474d 0x44c9 0x414d 0x2a38 0x49de 0x49f9 0x46bc 0x42ae 0x2a69 0x5290 0x46f7 0x45ec 0x428d 0x361a 0x5584 0x4149 0x40b9 0x4091 0x4b55 0x4df5 0x400a 0x3d5c 0x3f2e 0x526e 0x4548 0x4160 0x3cc8 0x3e86 0x51f1 0x4498 0x4322 0x3cc5 0x3dd8 0x5110 0x4682 0x4546 0x3de5 0x3d9d 0x4f30 0x4905 0x47ff 0x40b7 0x3d5c 0x4bd5 0x4cf9 0x4abc 0x4389 0x3d5b 0x4954 0x5107 0x4dd7 0x4627 0x3f36 0x43ea 0x522a 0x5065 0x48b3 0x4247 0x3bdf 0x5243 0x521a 0x4aeb 0x44d4 0x3927 0x522a 0x536b 0x4cf3 0x47e3 0x38b0 0x528d 0x5403 0x4f20 0x4a70 0x3802 0x537d 0x5464 0x5208 0x4cdb 0x3411 0x53d4 0x548b 0x53f6 0x4e60 0x2d2b 0x534a 0x5461 0x5202 0x4c20 0x2aaf 0x52ab 0x53f5 0x4d12 0x4667 0x2ab9 0x528e 0x5316 0x4ad4 0x4497 0x2ac4 0x5230 0x50ab 0x4a2f 0x45c9 0x2abe 0x4f5e 0x4ea7 0x49f1 0x478f 0x2aa0 0x38f6 0x4e1a 0x49d7 0x49ed 0x2a85 0x2d58 0x4d31 0x4964 0x4bf4 0x2a6d 0x2d43 0x46ce 0x458a 0x48fe 0x2a77 0x2c32 0x463a 0x4372 0x47fa 0x2a69 0x2b7a 0x3ace 0x4377 0x3e2a 0x2a59 0x2b50 0x3b6e 0x42b6 0x4112 0x2a4f 0x2b3b 0x3b50 0x4064 0x42af 0x2a59 0x2b26 0x3e5e 0x3fed 0x4b9d 0x2a7d 0x2b86 0x382a 0x3cbf 0x4be3 0x2aaa 0x2b94 0x373c 0x3d0a 0x4523 0x2a87 0x2b65 0x37c0 0x4127 0x41ae 0x2a60 0x2b3d 0x377a 0x3cf6 0x4504 0x2a26 0x2af3 0x3b3e 0x4aec 0x4d04 0x2a26 0x2af3 0x3b3e 0x4aec 0x4d04 0x2a26 0x2af3 0x3b3e 0x4aec 0x4d04>;
        qcom,lut-col-legend = <0x00 0x0a 0x19 0x28 0x32>;
    };

    qcom,pc-temp-z1-lut {
        qcom,lut-row-legend = <0x2710 0x2648 0x2580 0x24b8 0x23f0 0x2328 0x2260 0x2198 0x20d0 0x2008 0x1f40 0x1e78 0x1db0 0x1ce8 0x1c20 0x1b58 0x1a90 0x19c8 0x1900 0x1838 0x1770 0x16a8 0x15e0 0x1518 0x1450 0x1388 0x12c0 0x11f8 0x1130 0x1068 0xfa0 0xed8 0xe10 0xd48 0xc80 0xbb8 0xaf0 0xa28 0x960 0x898 0x7d0 0x708 0x640 0x578 0x4b0 0x3e8 0x384 0x320 0x2bc 0x258 0x1f4 0x190 0x12c 0xc8 0x64 0x00>;
        qcom,lut-data = <0x386a 0x33bb 0x3033 0x2ecb 0x2e3f 0x384b 0x33a2 0x3028 0x2e8c 0x2dfd 0x3838 0x338f 0x3006 0x2e75 0x2dec 0x3830 0x337c 0x2ff1 0x2e67 0x2de1 0x382d 0x3376 0x2fe7 0x2e5e 0x2dda 0x3829 0x337b 0x2fe1 0x2e57 0x2dd7 0x3821 0x337e 0x2fdd 0x2e52 0x2dd3 0x3816 0x3377 0x2fda 0x2e4b 0x2dce 0x380d 0x3366 0x2fd8 0x2e47 0x2dca 0x3803 0x335a 0x2fd2 0x2e45 0x2dc8 0x37fc 0x3357 0x2fcd 0x2e45 0x2dc7 0x37f7 0x3358 0x2fcd 0x2e44 0x2dc6 0x37f1 0x3356 0x2fce 0x2e40 0x2dc4 0x37e9 0x334f 0x2fca 0x2e3d 0x2dc3 0x37e2 0x3348 0x2fbe 0x2e3b 0x2dc2 0x37db 0x3340 0x2fb7 0x2e3a 0x2dc2 0x37d5 0x3339 0x2fb3 0x2e39 0x2dc1 0x37d5 0x3337 0x2fab 0x2e36 0x2dc2 0x37d9 0x333f 0x2faa 0x2e34 0x2dc3 0x37e0 0x3349 0x2fb2 0x2e37 0x2dc4 0x37e8 0x334d 0x2fb7 0x2e3d 0x2dc6 0x37ee 0x334a 0x2fbd 0x2e41 0x2dc9 0x37ef 0x3345 0x2fc6 0x2e43 0x2dce 0x37f0 0x334f 0x2fca 0x2e46 0x2dd2 0x37f4 0x335f 0x2fcc 0x2e4c 0x2dd6 0x3804 0x3366 0x2fce 0x2e54 0x2dd9 0x3816 0x336d 0x2fd7 0x2e59 0x2ddd 0x3825 0x336f 0x2fe2 0x2e5e 0x2de3 0x3835 0x336d 0x2fe4 0x2e61 0x2de8 0x383a 0x336f 0x2fe2 0x2e65 0x2ded 0x3825 0x3371 0x2fe0 0x2e68 0x2df0 0x37fe 0x3370 0x2fdd 0x2e6e 0x2df4 0x37f1 0x336f 0x2fd7 0x2e74 0x2df8 0x380c 0x3372 0x2fd8 0x2e79 0x2dfc 0x382a 0x3379 0x2fe4 0x2e7d 0x2e02 0x3823 0x337e 0x2fef 0x2e81 0x2e07 0x3807 0x3384 0x2ff5 0x2e86 0x2e0c 0x37fb 0x338a 0x2ffb 0x2e8d 0x2e10 0x380a 0x3395 0x3002 0x2e94 0x2e15 0x3821 0x33a3 0x300c 0x2e9b 0x2e1b 0x3835 0x33ac 0x3013 0x2ea1 0x2e21 0x384c 0x33b5 0x3017 0x2ea5 0x2e27 0x384a 0x33bd 0x301b 0x2ea9 0x2e2c 0x381f 0x33cb 0x301b 0x2ead 0x2e2f 0x385d 0x33b7 0x3017 0x2eb2 0x2e30 0x3868 0x33bb 0x302d 0x2eb7 0x2e36 0x3874 0x33b9 0x3020 0x2eb9 0x2e34 0x386b 0x33bb 0x3029 0x2ebc 0x2e37 0x3894 0x33b9 0x302c 0x2ec0 0x2e3c 0x3870 0x33cf 0x3037 0x2ec9 0x2e45 0x3889 0x33ed 0x303a 0x2ed4 0x2e50 0x38a5 0x33f4 0x3045 0x2ee0 0x2e58 0x38b9 0x3415 0x3056 0x2eef 0x2e67 0x390b 0x343d 0x3084 0x2f02 0x2e79 0x390b 0x343d 0x3084 0x2f02 0x2e79 0x390b 0x343d 0x3084 0x2f02 0x2e79>;
        qcom,lut-col-legend = <0x00 0x0a 0x19 0x28 0x32>;
    };
};

qcom,3446725_Wingtech_k81822_Jiade_3600mAh {
    qcom,batt-id-kohm = <0x33>;
    qcom,jeita-hard-thresholds = <0x6894 0xb14>;
    qcom,step-chg-ranges = <0x33e140 0x401640 0x2625a0 0x401a28 0x419ce0 0x1b7740 0x41a0c8 0x432380 0x124f80>;
    qcom,fastchg-current-ma = <0xe10>;
    qcom,max-voltage-uv = <0x432380>;
    qcom,qg-batt-profile-ver = <0x64>;
    qcom,battery-therm-kohm = <0x64>;
    qcom,battery-beta = <0x109a>;
    qcom,jeita-fcc-ranges = <0x00 0x64 0xafc80 0x65 0x96 0x107ac0 0x97 0x1c2 0x2625a0>;
    qcom,battery-type = "k81822_mtp_Jiade_4V4_3600mAh";
    qcom,fg-cc-cv-threshold-uv = <0x42fc70>;
    qcom,jeita-fv-ranges = <0x00 0x64 0x432380 0x65 0x1c2 0x432380 0x1c3 0x226 0x432380>;

    qcom,pc-temp-y4-lut {
        qcom,lut-row-legend = <0x2710 0x2648 0x2580 0x24b8 0x23f0 0x2328 0x2260 0x2198 0x20d0 0x2008 0x1f40 0x1e78 0x1db0 0x1ce8 0x1c20 0x1b58 0x1a90 0x19c8 0x1900 0x1838 0x1770 0x16a8 0x15e0 0x1518 0x1450 0x1388 0x12c0 0x11f8 0x1130 0x1068 0xfa0 0xed8 0xe10 0xd48 0xc80 0xbb8 0xaf0 0xa28 0x960 0x898 0x7d0 0x708 0x640 0x578 0x4b0 0x3e8 0x384 0x320 0x2bc 0x258 0x1f4 0x190 0x12c 0xc8 0x64 0x00>;
        qcom,lut-data = <0x42e4 0x41ec 0x4150 0x407a 0x4061 0x404d 0x4308 0x4208 0x415a 0x4077 0x405c 0x404d 0x433d 0x4248 0x416c 0x4076 0x4058 0x404e 0x4376 0x4294 0x4182 0x4076 0x4055 0x404e 0x43a6 0x42d2 0x4193 0x4077 0x4054 0x404e 0x43bd 0x42eb 0x4199 0x4078 0x4053 0x404f 0x43c2 0x42eb 0x4199 0x407d 0x4054 0x404f 0x43c6 0x42ec 0x4198 0x4084 0x4056 0x4050 0x43ed 0x42fa 0x418f 0x408a 0x405a 0x4051 0x4476 0x433e 0x4172 0x4091 0x4061 0x4053 0x44be 0x438a 0x4165 0x4094 0x4065 0x4056 0x44b1 0x43e4 0x4196 0x4095 0x4066 0x4059 0x4492 0x442e 0x41d0 0x4096 0x4066 0x405c 0x4424 0x43f1 0x41d2 0x409a 0x406a 0x4060 0x430a 0x42f1 0x41c7 0x40a9 0x4074 0x4065 0x4273 0x4265 0x41c3 0x40bc 0x407f 0x406c 0x4262 0x4256 0x41ce 0x40d3 0x4087 0x4075 0x4255 0x424b 0x41d9 0x40f0 0x4091 0x407f 0x423c 0x422e 0x41cc 0x4115 0x40a8 0x4090 0x4218 0x41fa 0x419f 0x4143 0x40cc 0x40a6 0x41fe 0x41c8 0x416f 0x4151 0x40d6 0x40ac 0x41ec 0x4196 0x4138 0x4103 0x40bd 0x409f 0x41e2 0x416e 0x410a 0x40a2 0x409a 0x408c 0x41e1 0x415e 0x40f6 0x407d 0x4078 0x4072 0x41e1 0x4154 0x40e9 0x4066 0x4055 0x4054 0x41e1 0x4150 0x40e9 0x405f 0x404d 0x404c 0x41dd 0x414e 0x4100 0x405f 0x404e 0x404b 0x41d9 0x414d 0x4115 0x4060 0x4050 0x404b 0x41d9 0x414e 0x4116 0x4064 0x4053 0x404e 0x41dc 0x4152 0x4117 0x406b 0x4057 0x4055 0x41e0 0x4155 0x4118 0x4071 0x405d 0x405d 0x41ed 0x4156 0x411d 0x4074 0x4069 0x4066 0x41f9 0x4158 0x4120 0x4077 0x4074 0x4070 0x41fe 0x415c 0x411d 0x4079 0x407e 0x407c 0x4201 0x4165 0x4117 0x407c 0x4087 0x4086 0x4203 0x416e 0x4116 0x407d 0x4083 0x4082 0x4205 0x4179 0x411b 0x407d 0x4069 0x4061 0x4206 0x4182 0x411f 0x407c 0x4056 0x404d 0x420a 0x4188 0x4122 0x4079 0x4053 0x404d 0x4210 0x418d 0x4124 0x4075 0x4052 0x404f 0x4216 0x4191 0x4125 0x4075 0x4053 0x4052 0x421f 0x4197 0x4125 0x4081 0x405a 0x4058 0x422e 0x4197 0x4122 0x4088 0x405d 0x4059 0x4249 0x418c 0x411d 0x408b 0x405d 0x4057 0x4264 0x4183 0x411b 0x4086 0x4050 0x4042 0x4248 0x417d 0x4119 0x408f 0x4055 0x4050 0x425b 0x4187 0x412b 0x408b 0x4061 0x4061 0x427c 0x41a2 0x4142 0x40a7 0x4074 0x407f 0x429b 0x41cb 0x4167 0x40b5 0x4096 0x40a2 0x42aa 0x41fa 0x419a 0x40d5 0x409c 0x409a 0x429f 0x4206 0x41ac 0x40c7 0x406b 0x4059 0x4296 0x41db 0x4195 0x40bd 0x4063 0x4059 0x4295 0x41d6 0x41a5 0x40c7 0x4074 0x4068 0x4329 0x41ec 0x41d6 0x410c 0x40ac 0x40a1 0x4329 0x41ec 0x41d6 0x410c 0x40ac 0x40a1 0x4329 0x41ec 0x41d6 0x410c 0x40ac 0x40a1>;
        qcom,lut-col-legend = <0xfffffff6 0x00 0x0a 0x19 0x28 0x32>;
    };

    qcom,pc-temp-v2-lut {
        qcom,lut-row-legend = <0x2710 0x2648 0x2580 0x24b8 0x23f0 0x2328 0x2260 0x2198 0x20d0 0x2008 0x1f40 0x1e78 0x1db0 0x1ce8 0x1c20 0x1b58 0x1a90 0x19c8 0x1900 0x1838 0x1770 0x16a8 0x15e0 0x1518 0x1450 0x1388 0x12c0 0x11f8 0x1130 0x1068 0xfa0 0xed8 0xe10 0xd48 0xc80 0xbb8 0xaf0 0xa28 0x960 0x898 0x7d0 0x708 0x640 0x578 0x4b0 0x3e8 0x384 0x320 0x2bc 0x258 0x1f4 0x190 0x12c 0xc8 0x64 0x00>;
        qcom,lut-data = <0xab72 0xab59 0xab40 0xab09 0xaaff 0xaae6 0xa9b8 0xa9c7 0xa9d4 0xa9b5 0xa9c0 0xa9ad 0xa82f 0xa85b 0xa889 0xa880 0xa89a 0xa889 0xa6de 0xa71d 0xa765 0xa76e 0xa78e 0xa781 0xa5bd 0xa605 0xa663 0xa67c 0xa69c 0xa690 0xa4b1 0xa4ff 0xa56c 0xa592 0xa5b0 0xa5a4 0xa3aa 0xa401 0xa473 0xa4a6 0xa4c5 0xa4b9 0xa2b6 0xa310 0xa385 0xa3be 0xa3dd 0xa3d1 0xa1e2 0xa227 0xa2a8 0xa2da 0xa2f8 0xa2ed 0xa127 0xa143 0xa1d8 0xa1fa 0xa216 0xa20b 0xa078 0xa084 0xa10e 0xa120 0xa139 0xa12d 0x9fe3 0xa005 0xa04f 0xa04d 0xa061 0xa055 0x9f43 0x9f87 0x9f8d 0x9f7d 0x9f8e 0x9f82 0x9e2c 0x9e93 0x9eac 0x9eaa 0x9ec2 0x9eb6 0x9c76 0x9cfb 0x9db1 0x9dd2 0x9df9 0x9def 0x9b1d 0x9bb2 0x9cd2 0x9d0b 0x9d39 0x9d30 0x9a4f 0x9aed 0x9c1c 0x9c5c 0x9c83 0x9c78 0x99a5 0x9a44 0x9b6e 0x9bb8 0x9bd4 0x9bc8 0x98fa 0x998b 0x9ab0 0x9b1c 0x9b2f 0x9b23 0x9855 0x98d0 0x99ea 0x9a89 0x9a93 0x9a88 0x97c1 0x9820 0x991f 0x99db 0x99e1 0x99d8 0x973b 0x977a 0x9844 0x98ef 0x9905 0x9901 0x96c3 0x96e5 0x977c 0x9800 0x982d 0x982d 0x9658 0x9667 0x96e4 0x9751 0x9776 0x9777 0x95f7 0x95f8 0x9665 0x96bf 0x96d2 0x96d2 0x95a0 0x959b 0x95f3 0x9642 0x964d 0x964b 0x9553 0x954c 0x958d 0x95d7 0x95e0 0x95df 0x950d 0x9508 0x9531 0x9577 0x9581 0x957e 0x94cb 0x94c9 0x94e2 0x951e 0x9528 0x9522 0x948d 0x948f 0x949c 0x94cd 0x94d8 0x94ce 0x9451 0x945b 0x945e 0x9483 0x948f 0x9484 0x9416 0x942c 0x9428 0x943e 0x944a 0x9441 0x93de 0x93ff 0x93f6 0x9400 0x940b 0x9403 0x93a6 0x93d1 0x93c8 0x93c8 0x93d2 0x93c9 0x9370 0x93a4 0x939e 0x9396 0x939b 0x938f 0x9338 0x9375 0x9371 0x9361 0x9353 0x933d 0x92fe 0x9343 0x9343 0x9329 0x92f6 0x92c7 0x92c1 0x930c 0x9310 0x92ee 0x9299 0x9258 0x927b 0x92cc 0x92d1 0x92aa 0x9248 0x9202 0x9230 0x9283 0x9289 0x9260 0x91f8 0x91b2 0x91e6 0x9232 0x9235 0x920f 0x91a8 0x915f 0x919d 0x91d2 0x91cf 0x91b2 0x9155 0x9108 0x9153 0x9162 0x9159 0x9147 0x90ed 0x909f 0x9109 0x90e1 0x90d2 0x90c8 0x906b 0x9022 0x90ba 0x906b 0x9049 0x9031 0x8fe3 0x8fa5 0x9060 0x9011 0x8ff0 0x8ff7 0x8fbb 0x8f82 0x902c 0x8fee 0x8fcf 0x8fec 0x8fae 0x8f73 0x8feb 0x8fca 0x8fb1 0x8fd8 0x8f9d 0x8f64 0x8f97 0x8f9c 0x8f81 0x8fc0 0x8f7d 0x8f41 0x8f08 0x8f48 0x8f25 0x8f7e 0x8f16 0x8ebe 0x8e0c 0x8e85 0x8e3d 0x8e86 0x8dd8 0x8d49 0x8c71 0x8ce0 0x8c67 0x8cb2 0x8bda 0x8b38 0x8a21 0x8a77 0x89e1 0x8a51 0x8943 0x8888 0x86b4 0x870e 0x8650 0x8718 0x85a6 0x84b3 0x80c1 0x8174 0x812b 0x8213 0x8059 0x7f71 0x70cd 0x752c 0x6c82 0x6f4f 0x6bce 0x6c02>;
        qcom,lut-col-legend = <0xfffffff6 0x00 0x0a 0x19 0x28 0x32>;
    };

    qcom,pc-temp-z4-lut {
        qcom,lut-row-legend = <0x2710 0x2648 0x2580 0x24b8 0x23f0 0x2328 0x2260 0x2198 0x20d0 0x2008 0x1f40 0x1e78 0x1db0 0x1ce8 0x1c20 0x1b58 0x1a90 0x19c8 0x1900 0x1838 0x1770 0x16a8 0x15e0 0x1518 0x1450 0x1388 0x12c0 0x11f8 0x1130 0x1068 0xfa0 0xed8 0xe10 0xd48 0xc80 0xbb8 0xaf0 0xa28 0x960 0x898 0x7d0 0x708 0x640 0x578 0x4b0 0x3e8 0x384 0x320 0x2bc 0x258 0x1f4 0x190 0x12c 0xc8 0x64 0x00>;
        qcom,lut-data = <0x40e7 0x3dfc 0x3afa 0x39ec 0x39e1 0x4228 0x3da7 0x3bf1 0x3ab1 0x3a44 0x4141 0x3d34 0x3b67 0x3a8d 0x3a3d 0x3fb7 0x3c88 0x3acc 0x3a40 0x3a0c 0x3eba 0x3bbc 0x3a78 0x3a0e 0x39e8 0x3e08 0x3b38 0x3a35 0x39ea 0x39cb 0x3d77 0x3ade 0x3a01 0x39cd 0x39b5 0x3d01 0x3a9b 0x39d5 0x39b5 0x39a4 0x3c9d 0x3a66 0x39b7 0x39a2 0x3997 0x3c47 0x3a3d 0x39a6 0x3997 0x3991 0x3bfd 0x3a28 0x399a 0x3990 0x398e 0x3bba 0x3a1f 0x3990 0x3988 0x398a 0x3b7e 0x3a15 0x3988 0x397d 0x3981 0x3b47 0x39f7 0x3982 0x3973 0x3977 0x3b05 0x39cc 0x397e 0x396d 0x396f 0x3a8f 0x39c0 0x397a 0x3968 0x3969 0x3a26 0x39c2 0x3975 0x3962 0x3962 0x3a37 0x39c7 0x396e 0x3959 0x395b 0x3ac5 0x39e2 0x3966 0x3951 0x3954 0x3b37 0x3a19 0x395c 0x394a 0x394e 0x3b7f 0x3a27 0x3953 0x3944 0x3949 0x3bce 0x39de 0x3961 0x394c 0x394d 0x3bc3 0x3997 0x399f 0x3998 0x3991 0x3ae7 0x39a6 0x39ce 0x39db 0x39d2 0x3a25 0x39d6 0x39e8 0x39ea 0x39e2 0x3a0d 0x39ea 0x39f8 0x39f2 0x39eb 0x3a04 0x39e9 0x39f3 0x39eb 0x39e4 0x3a02 0x39e6 0x39d9 0x39bd 0x39a9 0x3a5c 0x39dd 0x39bd 0x3993 0x3978 0x3ac1 0x39c6 0x399f 0x397c 0x396b 0x3ac9 0x39b5 0x3984 0x396b 0x3963 0x3ac2 0x39a9 0x3975 0x3960 0x395c 0x3abb 0x39a1 0x3969 0x3957 0x3956 0x3b03 0x39b4 0x3962 0x3953 0x3953 0x3b6c 0x3a00 0x395d 0x3951 0x3951 0x3b7a 0x3a27 0x3959 0x394f 0x394f 0x3b6b 0x3a5b 0x3957 0x3950 0x3950 0x3b5b 0x3a9b 0x3956 0x3953 0x3954 0x3b4e 0x3aa2 0x3957 0x3956 0x3958 0x3b41 0x3aa0 0x395e 0x395e 0x395e 0x3b36 0x3a9e 0x3965 0x3964 0x3962 0x3b2d 0x3a9a 0x3962 0x3961 0x395e 0x3b20 0x3a93 0x395e 0x395c 0x3958 0x3b0a 0x3a8a 0x3961 0x3961 0x395a 0x3aa9 0x3a5d 0x395e 0x395e 0x3957 0x3a8a 0x3a3a 0x3950 0x3953 0x394e 0x3a87 0x3a35 0x3976 0x394e 0x3948 0x3a80 0x3a2e 0x396b 0x3939 0x393e 0x3a7b 0x3a2a 0x399e 0x393e 0x3930 0x3a74 0x3a24 0x399b 0x3942 0x3941 0x3a7a 0x3a30 0x398f 0x394e 0x3933 0x3a91 0x3a3d 0x3995 0x3945 0x3935 0x3aa1 0x3a46 0x39ab 0x394c 0x393a 0x3aba 0x3a54 0x39ae 0x394b 0x393d 0x3aba 0x3a54 0x39ae 0x394b 0x393d 0x3aba 0x3a54 0x39ae 0x394b 0x393d>;
        qcom,lut-col-legend = <0x00 0x0a 0x19 0x28 0x32>;
    };

    qcom,pc-temp-y3-lut {
        qcom,lut-row-legend = <0x2710 0x2648 0x2580 0x24b8 0x23f0 0x2328 0x2260 0x2198 0x20d0 0x2008 0x1f40 0x1e78 0x1db0 0x1ce8 0x1c20 0x1b58 0x1a90 0x19c8 0x1900 0x1838 0x1770 0x16a8 0x15e0 0x1518 0x1450 0x1388 0x12c0 0x11f8 0x1130 0x1068 0xfa0 0xed8 0xe10 0xd48 0xc80 0xbb8 0xaf0 0xa28 0x960 0x898 0x7d0 0x708 0x640 0x578 0x4b0 0x3e8 0x384 0x320 0x2bc 0x258 0x1f4 0x190 0x12c 0xc8 0x64 0x00>;
        qcom,lut-data = <0x3b77 0x3738 0x341f 0x33e9 0x33dc 0x33dd 0x3aee 0x36ff 0x342d 0x33ec 0x33dd 0x33dc 0x3a6c 0x36c8 0x3437 0x33ee 0x33de 0x33dc 0x39f2 0x3694 0x343e 0x33ef 0x33df 0x33dc 0x3983 0x3667 0x3441 0x33f0 0x33e0 0x33dc 0x3921 0x3643 0x3442 0x33f0 0x33e0 0x33dd 0x38ce 0x362a 0x343e 0x33ef 0x33e1 0x33dd 0x3883 0x3613 0x3439 0x33ee 0x33e2 0x33de 0x3831 0x35ed 0x343c 0x33ee 0x33e2 0x33df 0x37d6 0x35b2 0x3449 0x33ee 0x33e1 0x33df 0x37aa 0x3596 0x344f 0x33f0 0x33e0 0x33df 0x37a5 0x359d 0x344e 0x33f5 0x33e4 0x33e1 0x37a2 0x35a5 0x344c 0x33fc 0x33e8 0x33e3 0x3788 0x3598 0x344a 0x33fd 0x33e8 0x33e3 0x3741 0x3563 0x3448 0x33fc 0x33e8 0x33e4 0x371d 0x3545 0x3445 0x33fc 0x33e8 0x33e4 0x371b 0x3540 0x3442 0x33ff 0x33ea 0x33e4 0x371a 0x353d 0x343f 0x3402 0x33ee 0x33e4 0x3719 0x3537 0x343a 0x3403 0x33ef 0x33e6 0x3717 0x352d 0x3432 0x3403 0x33ef 0x33e8 0x3715 0x3529 0x3428 0x3402 0x33ef 0x33e9 0x3716 0x352a 0x3414 0x33fd 0x33ec 0x33e7 0x3717 0x352d 0x3406 0x33f7 0x33e8 0x33e4 0x371b 0x3531 0x3405 0x33f5 0x33e5 0x33e1 0x3723 0x3539 0x3406 0x33f2 0x33e2 0x33de 0x372f 0x3544 0x3403 0x33f1 0x33e1 0x33dd 0x3745 0x3555 0x33ec 0x33f1 0x33e0 0x33de 0x3760 0x356b 0x33d9 0x33f0 0x33e0 0x33de 0x377a 0x3580 0x33d9 0x33ef 0x33e1 0x33dd 0x3795 0x3597 0x33db 0x33ed 0x33e3 0x33dc 0x37b1 0x35b2 0x33dd 0x33ec 0x33e3 0x33dc 0x37ce 0x35d5 0x33e0 0x33ed 0x33e2 0x33dd 0x37ed 0x35fa 0x33e5 0x33ee 0x33e1 0x33de 0x380f 0x3620 0x33ed 0x33ef 0x33e2 0x33df 0x3833 0x3649 0x33f9 0x33f1 0x33e4 0x33e0 0x385c 0x3675 0x3405 0x33f2 0x33e4 0x33e0 0x388d 0x36a6 0x3411 0x33ef 0x33e2 0x33dd 0x38c0 0x36db 0x341d 0x33ed 0x33e1 0x33dc 0x38ee 0x3715 0x342a 0x33ec 0x33e0 0x33dc 0x391b 0x3753 0x3437 0x33ec 0x33e0 0x33dc 0x394f 0x3794 0x3448 0x33eb 0x33e1 0x33dc 0x398d 0x37d7 0x345c 0x33ea 0x33e4 0x33dd 0x39d0 0x3824 0x3479 0x33ea 0x33e4 0x33de 0x3a1a 0x387b 0x349c 0x33ee 0x33e4 0x33e0 0x3a70 0x38c8 0x34b7 0x33ea 0x33dd 0x33dd 0x3a77 0x38ef 0x34de 0x33e9 0x33e2 0x33df 0x3aca 0x393b 0x3508 0x33f4 0x33e5 0x33e1 0x3b35 0x399d 0x3541 0x33f2 0x33e9 0x33e7 0x3bb2 0x39f6 0x3580 0x33fd 0x33ef 0x33eb 0x3c2a 0x3a5d 0x35ca 0x3402 0x33ee 0x33eb 0x3cbf 0x3ac0 0x360b 0x33fb 0x33ea 0x33e7 0x3d8f 0x3b26 0x3671 0x33fd 0x33ec 0x33e6 0x3eac 0x3be3 0x375e 0x340a 0x33ef 0x33eb 0x415b 0x3cb4 0x387a 0x3418 0x33f5 0x33ef 0x415b 0x3cb4 0x387a 0x3418 0x33f5 0x33ef 0x415b 0x3cb4 0x387a 0x3418 0x33f5 0x33ef>;
        qcom,lut-col-legend = <0xfffffff6 0x00 0x0a 0x19 0x28 0x32>;
    };

    qcom,pc-temp-v1-lut {
        qcom,lut-row-legend = <0x2710 0x2648 0x2580 0x24b8 0x23f0 0x2328 0x2260 0x2198 0x20d0 0x2008 0x1f40 0x1e78 0x1db0 0x1ce8 0x1c20 0x1b58 0x1a90 0x19c8 0x1900 0x1838 0x1770 0x16a8 0x15e0 0x1518 0x1450 0x1388 0x12c0 0x11f8 0x1130 0x1068 0xfa0 0xed8 0xe10 0xd48 0xc80 0xbb8 0xaf0 0xa28 0x960 0x898 0x7d0 0x708 0x640 0x578 0x4b0 0x3e8 0x384 0x320 0x2bc 0x258 0x1f4 0x190 0x12c 0xc8 0x64 0x00>;
        qcom,lut-data = <0xa9e7 0xaaa2 0xab37 0xab6a 0xab73 0xa8b0 0xa977 0xaa1b 0xaa33 0xaa34 0xa7ab 0xa864 0xa912 0xa92d 0xa92d 0xa6bd 0xa769 0xa813 0xa838 0xa836 0xa5d3 0xa67f 0xa71c 0xa746 0xa745 0xa4f1 0xa596 0xa62d 0xa658 0xa65a 0xa415 0xa4af 0xa540 0xa56d 0xa573 0xa33e 0xa3cf 0xa454 0xa481 0xa488 0xa26f 0xa2f3 0xa36d 0xa399 0xa3a0 0xa1ab 0xa21f 0xa28b 0xa2b5 0xa2bd 0xa0ff 0xa15b 0xa1ae 0xa1d5 0xa1de 0xa04b 0xa0af 0xa0e2 0xa0fa 0xa103 0x9f64 0x9ff8 0xa029 0xa022 0xa02b 0x9e52 0x9f09 0x9f66 0x9f52 0x9f59 0x9d5e 0x9df8 0x9e75 0x9e89 0x9e8f 0x9c92 0x9d1a 0x9d81 0x9dc7 0x9dcd 0x9bde 0x9c69 0x9cc8 0x9d0f 0x9d13 0x9b48 0x9bce 0x9c38 0x9c5f 0x9c62 0x9acb 0x9b45 0x9baa 0x9bb6 0x9bb7 0x9a54 0x9ac9 0x9b1b 0x9b1c 0x9b1a 0x99de 0x9a47 0x9a84 0x9a88 0x9a85 0x996b 0x99bc 0x99c0 0x99cf 0x99d2 0x98f3 0x9926 0x98c8 0x98d2 0x98e2 0x9874 0x9866 0x97f8 0x97f2 0x9805 0x97fb 0x9787 0x975a 0x9763 0x9771 0x978e 0x96e4 0x96da 0x96f2 0x96fa 0x972b 0x9676 0x967b 0x9689 0x968b 0x96d1 0x9621 0x9632 0x9628 0x9623 0x9680 0x95e5 0x95ec 0x95d0 0x95c6 0x9636 0x95b7 0x95a4 0x9580 0x9570 0x95f1 0x958d 0x9561 0x9538 0x9524 0x95b0 0x9563 0x9527 0x94f6 0x94df 0x957c 0x953e 0x94f3 0x94bb 0x94a3 0x9556 0x951e 0x94c6 0x9485 0x946b 0x9535 0x9504 0x94a0 0x9456 0x9439 0x9511 0x94e8 0x947c 0x942a 0x9409 0x94ec 0x94cd 0x9456 0x93fa 0x93d0 0x94c1 0x94ac 0x942e 0x93c9 0x9391 0x948c 0x947a 0x93f7 0x938a 0x9349 0x944a 0x942b 0x93a3 0x9337 0x92f4 0x93f9 0x93cc 0x933e 0x92d5 0x9293 0x9388 0x9359 0x92d0 0x9268 0x9226 0x9305 0x92d2 0x9251 0x91ec 0x91a7 0x926c 0x9233 0x91b7 0x9153 0x910e 0x91d8 0x9199 0x9125 0x90c3 0x9083 0x916a 0x912f 0x90c1 0x9066 0x902a 0x9145 0x910c 0x90ac 0x904c 0x900e 0x9129 0x90f2 0x9096 0x9039 0x8ffe 0x9110 0x90dc 0x9086 0x9029 0x8fec 0x90e6 0x90b3 0x905c 0x8ff1 0x8fab 0x902c 0x8fdc 0x8f72 0x8ee9 0x8e8d 0x8e7d 0x8e26 0x8dc4 0x8d32 0x8cd2 0x8c4a 0x8be9 0x8b89 0x8af1 0x8a8f 0x894c 0x88d8 0x887a 0x87da 0x8775 0x8493 0x8405 0x83b9 0x8308 0x829e 0x7530 0x7530 0x7530 0x7530 0x7530>;
        qcom,lut-col-legend = <0x00 0x0a 0x19 0x28 0x32>;
    };

    qcom,fcc2-temp-lut {
        qcom,lut-data = <0xe30 0xe33 0xe41 0xe33 0xe43 0xe42>;
        qcom,lut-col-legend = <0xfffffff6 0x00 0x0a 0x19 0x28 0x32>;
    };

    qcom,pc-temp-z3-lut {
        qcom,lut-row-legend = <0x2710 0x2648 0x2580 0x24b8 0x23f0 0x2328 0x2260 0x2198 0x20d0 0x2008 0x1f40 0x1e78 0x1db0 0x1ce8 0x1c20 0x1b58 0x1a90 0x19c8 0x1900 0x1838 0x1770 0x16a8 0x15e0 0x1518 0x1450 0x1388 0x12c0 0x11f8 0x1130 0x1068 0xfa0 0xed8 0xe10 0xd48 0xc80 0xbb8 0xaf0 0xa28 0x960 0x898 0x7d0 0x708 0x640 0x578 0x4b0 0x3e8 0x384 0x320 0x2bc 0x258 0x1f4 0x190 0x12c 0xc8 0x64 0x00>;
        qcom,lut-data = <0x4c44 0x4b4c 0x4baa 0x4baa 0x4b8f 0x4d5e 0x4c56 0x4bfd 0x4bd0 0x4bad 0x4d8a 0x4ce2 0x4c23 0x4bdb 0x4bbf 0x4d9f 0x4cef 0x4c35 0x4be0 0x4bcc 0x4d9b 0x4cf6 0x4c3a 0x4be3 0x4bcf 0x4d73 0x4cf6 0x4c3c 0x4be5 0x4bce 0x4d4b 0x4cf1 0x4c3c 0x4be6 0x4bcd 0x4d38 0x4ce9 0x4c3a 0x4be3 0x4bcb 0x4d29 0x4cde 0x4c37 0x4bdd 0x4bc7 0x4d1f 0x4ccf 0x4c2f 0x4bd6 0x4bc1 0x4d13 0x4cba 0x4c21 0x4bcd 0x4bb7 0x4d0b 0x4c93 0x4c14 0x4bc8 0x4bb0 0x4d12 0x4c78 0x4c06 0x4bc5 0x4bae 0x4d2d 0x4c82 0x4c00 0x4bc3 0x4bad 0x4d4c 0x4c98 0x4c03 0x4bbe 0x4ba9 0x4d79 0x4c9d 0x4c09 0x4bb6 0x4ba4 0x4da0 0x4c87 0x4c05 0x4bb2 0x4ba0 0x4d82 0x4c66 0x4bef 0x4bb0 0x4b9d 0x4cdf 0x4c34 0x4be2 0x4baf 0x4b9b 0x4c53 0x4bf4 0x4be3 0x4bae 0x4b98 0x4bfb 0x4be3 0x4be4 0x4bac 0x4b96 0x4ba7 0x4c17 0x4bea 0x4bad 0x4b95 0x4bac 0x4c56 0x4bfd 0x4bb3 0x4b99 0x4c60 0x4c79 0x4c06 0x4bb8 0x4b9c 0x4cf9 0x4c97 0x4c00 0x4baf 0x4b95 0x4d00 0x4ca1 0x4bf7 0x4b9e 0x4b86 0x4d00 0x4ca0 0x4bf3 0x4ba0 0x4b88 0x4cfb 0x4c9d 0x4bf0 0x4bba 0x4bae 0x4ca4 0x4c99 0x4bef 0x4bcc 0x4bc7 0x4c45 0x4c90 0x4bf9 0x4bcf 0x4bc5 0x4c39 0x4c86 0x4c04 0x4bd0 0x4bc0 0x4c34 0x4c7c 0x4c05 0x4bcf 0x4bba 0x4c2b 0x4c71 0x4c03 0x4bca 0x4bb2 0x4bd6 0x4c4c 0x4c00 0x4bc5 0x4baa 0x4b63 0x4bf7 0x4bfb 0x4bbf 0x4ba1 0x4b49 0x4bc8 0x4bf5 0x4bb9 0x4b9a 0x4b47 0x4b8c 0x4bf2 0x4bb5 0x4b9a 0x4b46 0x4b47 0x4bef 0x4bb2 0x4b9a 0x4b45 0x4b3e 0x4bed 0x4bb0 0x4b9a 0x4b45 0x4b3d 0x4beb 0x4bae 0x4b98 0x4b45 0x4b3d 0x4be8 0x4bac 0x4b96 0x4b46 0x4b3d 0x4be5 0x4ba8 0x4b95 0x4b47 0x4b3c 0x4be1 0x4ba4 0x4b94 0x4b48 0x4b3c 0x4bdc 0x4ba1 0x4b97 0x4b4a 0x4b3b 0x4bd0 0x4b9f 0x4b97 0x4b4b 0x4b3b 0x4bc3 0x4b95 0x4b89 0x4b4a 0x4b3b 0x4b95 0x4b8e 0x4b86 0x4b4b 0x4b3b 0x4b96 0x4b92 0x4b7d 0x4b4b 0x4b3b 0x4b60 0x4b81 0x4b78 0x4b4b 0x4b3b 0x4b62 0x4b7e 0x4b6b 0x4b4c 0x4b3b 0x4b7d 0x4b8c 0x4b97 0x4b4d 0x4b3c 0x4b7e 0x4b9a 0x4b9d 0x4b51 0x4b3e 0x4b6f 0x4b98 0x4b9c 0x4b54 0x4b3e 0x4b72 0x4b9e 0x4b9f 0x4b54 0x4b3e 0x4b72 0x4b9e 0x4b9f 0x4b54 0x4b3e 0x4b72 0x4b9e 0x4b9f>;
        qcom,lut-col-legend = <0x00 0x0a 0x19 0x28 0x32>;
    };

    qcom,pc-temp-y6-lut {
        qcom,lut-row-legend = <0x2710 0x2648 0x2580 0x24b8 0x23f0 0x2328 0x2260 0x2198 0x20d0 0x2008 0x1f40 0x1e78 0x1db0 0x1ce8 0x1c20 0x1b58 0x1a90 0x19c8 0x1900 0x1838 0x1770 0x16a8 0x15e0 0x1518 0x1450 0x1388 0x12c0 0x11f8 0x1130 0x1068 0xfa0 0xed8 0xe10 0xd48 0xc80 0xbb8 0xaf0 0xa28 0x960 0x898 0x7d0 0x708 0x640 0x578 0x4b0 0x3e8 0x384 0x320 0x2bc 0x258 0x1f4 0x190 0x12c 0xc8 0x64 0x00>;
        qcom,lut-data = <0x1cdf 0x18cc 0x15b0 0x13f1 0x139e 0x138d 0x1c91 0x18bb 0x15ab 0x13f0 0x139e 0x138d 0x1c46 0x18a9 0x15a4 0x13f0 0x139e 0x138d 0x1bff 0x1896 0x159c 0x13ef 0x139e 0x138d 0x1bbc 0x1882 0x1593 0x13ee 0x139e 0x138d 0x1b7d 0x186e 0x1588 0x13ee 0x139e 0x138d 0x1b3f 0x1857 0x157a 0x13ed 0x139e 0x138d 0x1b09 0x1841 0x156d 0x13ec 0x139f 0x138e 0x1ae5 0x182f 0x156b 0x13ec 0x13a0 0x138f 0x1acb 0x181d 0x156a 0x13ed 0x13a0 0x138f 0x1ab8 0x1816 0x156a 0x13ef 0x13a1 0x1390 0x1aac 0x1828 0x156e 0x13f2 0x13a3 0x1392 0x1aa0 0x183f 0x1572 0x13f5 0x13a6 0x1394 0x1a6c 0x1827 0x156e 0x13f8 0x13a8 0x1395 0x19ec 0x17c2 0x1561 0x13fb 0x13aa 0x1398 0x19aa 0x178a 0x155c 0x13ff 0x13ad 0x139a 0x19a5 0x1784 0x155e 0x1408 0x13b1 0x139c 0x19a1 0x1780 0x1561 0x1413 0x13b6 0x139f 0x1999 0x1775 0x155b 0x141f 0x13be 0x13a5 0x198d 0x1762 0x1545 0x142a 0x13c9 0x13ad 0x1986 0x1753 0x152e 0x142e 0x13cb 0x13af 0x1982 0x1747 0x150f 0x1414 0x13c2 0x13aa 0x1980 0x1740 0x14f7 0x13f5 0x13b4 0x13a2 0x1981 0x1741 0x14f3 0x13e9 0x13a8 0x1398 0x1987 0x1746 0x14f1 0x13e2 0x139c 0x138d 0x1990 0x174e 0x14f1 0x13e0 0x1399 0x138b 0x199e 0x175c 0x14f4 0x13e0 0x1399 0x138b 0x19b0 0x176e 0x14fa 0x13e1 0x139a 0x138b 0x19c3 0x1780 0x1501 0x13e3 0x139c 0x138c 0x19d9 0x1793 0x150b 0x13e6 0x139e 0x138e 0x19f1 0x17aa 0x1515 0x13e9 0x13a1 0x1390 0x1a0b 0x17c5 0x1521 0x13ec 0x13a4 0x1393 0x1a26 0x17e3 0x152e 0x13ef 0x13a8 0x1397 0x1a41 0x1801 0x153c 0x13f3 0x13ac 0x139c 0x1a5c 0x1822 0x154b 0x13f8 0x13b1 0x139f 0x1a7d 0x1846 0x155b 0x13fa 0x13b0 0x139e 0x1aa6 0x186f 0x156d 0x13fa 0x13a7 0x1394 0x1ad1 0x189b 0x1581 0x13fa 0x13a2 0x138d 0x1af5 0x18ca 0x1597 0x13fa 0x13a1 0x138e 0x1b18 0x18fb 0x15af 0x13fa 0x13a1 0x138e 0x1b43 0x192e 0x15ca 0x13fb 0x13a2 0x1390 0x1b79 0x1963 0x15e9 0x1400 0x13a6 0x1392 0x1bb3 0x199e 0x160d 0x1406 0x13a8 0x1394 0x1bf3 0x19df 0x1635 0x140d 0x13a9 0x1395 0x1c3e 0x1a1a 0x1659 0x140d 0x13a1 0x138d 0x1c45 0x1a39 0x1682 0x1410 0x13a7 0x1394 0x1c8b 0x1a72 0x16af 0x141a 0x13ad 0x139a 0x1ce5 0x1ac5 0x16e9 0x1423 0x13b6 0x13a7 0x1d51 0x1b17 0x172c 0x1433 0x13c3 0x13b4 0x1db6 0x1b73 0x1779 0x1442 0x13c5 0x13b2 0x1e27 0x1bc5 0x17b9 0x143a 0x13b5 0x139c 0x1ed1 0x1c0d 0x1808 0x1441 0x13b4 0x139d 0x1fbb 0x1ca2 0x18cb 0x145d 0x13be 0x13a6 0x2217 0x1d4f 0x19b8 0x148c 0x13d4 0x13bb 0x2217 0x1d4f 0x19b8 0x148c 0x13d4 0x13bb 0x2217 0x1d4f 0x19b8 0x148c 0x13d4 0x13bb>;
        qcom,lut-col-legend = <0xfffffff6 0x00 0x0a 0x19 0x28 0x32>;
    };

    qcom,pc-temp-y2-lut {
        qcom,lut-row-legend = <0x2710 0x2648 0x2580 0x24b8 0x23f0 0x2328 0x2260 0x2198 0x20d0 0x2008 0x1f40 0x1e78 0x1db0 0x1ce8 0x1c20 0x1b58 0x1a90 0x19c8 0x1900 0x1838 0x1770 0x16a8 0x15e0 0x1518 0x1450 0x1388 0x12c0 0x11f8 0x1130 0x1068 0xfa0 0xed8 0xe10 0xd48 0xc80 0xbb8 0xaf0 0xa28 0x960 0x898 0x7d0 0x708 0x640 0x578 0x4b0 0x3e8 0x384 0x320 0x2bc 0x258 0x1f4 0x190 0x12c 0xc8 0x64 0x00>;
        qcom,lut-data = <0x25b8 0x25ba 0x25e2 0x2c2b 0x2b9c 0x2c12 0x25b8 0x25ba 0x25d7 0x2c13 0x2bc9 0x2bf2 0x25b8 0x25ba 0x25d6 0x2bf9 0x2beb 0x2bca 0x25b8 0x25bb 0x25dd 0x2be1 0x2c01 0x2ba1 0x25b8 0x25bb 0x25e9 0x2bcc 0x2c0c 0x2b80 0x25b8 0x25bb 0x25f9 0x2bbd 0x2c0e 0x2b6e 0x25b8 0x25bc 0x260b 0x2bb3 0x2bfc 0x2b67 0x25b8 0x25bc 0x2628 0x2baa 0x2bdc 0x2b63 0x25b9 0x25bd 0x26bd 0x2b92 0x2bb8 0x2b58 0x25b9 0x25bd 0x2871 0x2b5e 0x2b88 0x2b47 0x25b9 0x25bd 0x2970 0x2b31 0x2b63 0x2b3d 0x25b9 0x25be 0x29a0 0x2b12 0x2b44 0x2b1e 0x25b9 0x25be 0x29be 0x2afc 0x2b2c 0x2afd 0x25b9 0x25be 0x29de 0x2b00 0x2b24 0x2afc 0x25b9 0x25be 0x29fb 0x2b18 0x2b21 0x2aff 0x25b9 0x25bd 0x2a18 0x2b26 0x2b23 0x2afd 0x25b9 0x25bd 0x2a3a 0x2b31 0x2b2e 0x2af3 0x25b9 0x25bd 0x2a53 0x2b42 0x2b42 0x2aeb 0x25b9 0x25bd 0x2a58 0x2b61 0x2b73 0x2b13 0x25b9 0x25bd 0x2a59 0x2b9d 0x2bc5 0x2b83 0x25b9 0x25bd 0x2a3f 0x2bb5 0x2bdf 0x2bba 0x25b9 0x25bd 0x28ec 0x2ba4 0x2bcc 0x2bb6 0x25b9 0x25bd 0x277e 0x2b92 0x2bbb 0x2baa 0x25b9 0x25bd 0x2702 0x2b96 0x2bc8 0x2bad 0x25b9 0x25bd 0x26aa 0x2bac 0x2be7 0x2bb8 0x25b9 0x25bc 0x2677 0x2bc4 0x2bf3 0x2bc6 0x25b9 0x25bc 0x2656 0x2be7 0x2beb 0x2bdb 0x25b9 0x25bc 0x2640 0x2c05 0x2be6 0x2bec 0x25b9 0x25bb 0x2634 0x2c14 0x2c0f 0x2c04 0x25b9 0x25bb 0x262c 0x2c20 0x2c53 0x2c2b 0x25b9 0x25bb 0x2621 0x2c24 0x2c64 0x2c38 0x25b9 0x25bb 0x2615 0x2c25 0x2c57 0x2c3b 0x25b9 0x25ba 0x2608 0x2c26 0x2c4b 0x2c3d 0x25b9 0x25ba 0x25fa 0x2c23 0x2c4b 0x2c2c 0x25b9 0x25ba 0x25ed 0x2c1e 0x2c4e 0x2c11 0x25b9 0x25ba 0x25e4 0x2c14 0x2c4c 0x2c0a 0x25b9 0x25b9 0x25de 0x2bf3 0x2c3b 0x2bff 0x25b9 0x25b9 0x25d9 0x2bd2 0x2c34 0x2bfb 0x25b9 0x25b9 0x25d5 0x2bc2 0x2c3d 0x2c01 0x25b8 0x25b9 0x25d1 0x2bb0 0x2c45 0x2c07 0x25b8 0x25b8 0x25ce 0x2b88 0x2c42 0x2c05 0x25b8 0x25b8 0x25cb 0x2b04 0x2c33 0x2bf0 0x25b8 0x25b8 0x25c7 0x2ada 0x2c2b 0x2bf3 0x25b7 0x25b7 0x25c4 0x2af5 0x2c21 0x2bfb 0x25b7 0x25b7 0x25c2 0x2a72 0x2bfc 0x2bc4 0x25b7 0x25b7 0x25c0 0x28f8 0x2be3 0x2b6c 0x25b7 0x25b7 0x25bf 0x2a8e 0x2bb8 0x2b59 0x25b7 0x25b7 0x25bd 0x292c 0x2bbe 0x2b1f 0x25b6 0x25b7 0x25bc 0x2a80 0x2ba1 0x2b2a 0x25b6 0x25b6 0x25bb 0x2a5f 0x2b90 0x2b16 0x25b6 0x25b6 0x25ba 0x28b6 0x2b55 0x2ae0 0x25b5 0x25b6 0x25b9 0x2856 0x2b25 0x2a9c 0x25b5 0x25b5 0x25b8 0x296a 0x2af1 0x2a61 0x25b4 0x25b5 0x25b6 0x2923 0x2a69 0x29e5 0x25b4 0x25b5 0x25b6 0x2923 0x2a69 0x29e5 0x25b4 0x25b5 0x25b6 0x2923 0x2a69 0x29e5>;
        qcom,lut-col-legend = <0xfffffff6 0x00 0x0a 0x19 0x28 0x32>;
    };

    qcom,pc-temp-z6-lut {
        qcom,lut-row-legend = <0x2710 0x2648 0x2580 0x24b8 0x23f0 0x2328 0x2260 0x2198 0x20d0 0x2008 0x1f40 0x1e78 0x1db0 0x1ce8 0x1c20 0x1b58 0x1a90 0x19c8 0x1900 0x1838 0x1770 0x16a8 0x15e0 0x1518 0x1450 0x1388 0x12c0 0x11f8 0x1130 0x1068 0xfa0 0xed8 0xe10 0xd48 0xc80 0xbb8 0xaf0 0xa28 0x960 0x898 0x7d0 0x708 0x640 0x578 0x4b0 0x3e8 0x384 0x320 0x2bc 0x258 0x1f4 0x190 0x12c 0xc8 0x64 0x00>;
        qcom,lut-data = <0x4190 0x3d95 0x3a67 0x3955 0x391c 0x4269 0x3d94 0x3ae8 0x39ba 0x3955 0x41d8 0x3d86 0x3ab1 0x39ab 0x3956 0x40d8 0x3d34 0x3a6f 0x398a 0x3948 0x401e 0x3ca0 0x3a44 0x3973 0x393b 0x3f88 0x3c3d 0x3a1f 0x3963 0x392d 0x3f0c 0x3bf9 0x3a01 0x3954 0x3921 0x3ead 0x3bc2 0x39e6 0x3946 0x3918 0x3e5e 0x3b92 0x39d2 0x393a 0x3910 0x3e1a 0x3b69 0x39c3 0x3930 0x3908 0x3dde 0x3b46 0x39b8 0x3928 0x3902 0x3da9 0x3b26 0x39ad 0x3921 0x38fc 0x3d7a 0x3b0b 0x39a2 0x391b 0x38f6 0x3d4f 0x3af8 0x399b 0x3915 0x38f1 0x3d28 0x3ae8 0x3998 0x390f 0x38ec 0x3d04 0x3adb 0x3995 0x3909 0x38e6 0x3ce3 0x3acf 0x398f 0x3904 0x38e1 0x3cc6 0x3ac6 0x3983 0x3900 0x38dc 0x3caa 0x3ac0 0x397d 0x38fc 0x38d9 0x3c9a 0x3abc 0x397b 0x38f8 0x38d5 0x3c95 0x3aba 0x397a 0x38f6 0x38d1 0x3c91 0x3abc 0x3983 0x38fa 0x38d4 0x3c91 0x3ac0 0x39a9 0x3920 0x38f5 0x3c95 0x3ad4 0x39c3 0x393e 0x3912 0x3c98 0x3afe 0x39cc 0x393e 0x3912 0x3c98 0x3b0e 0x39d1 0x393d 0x3912 0x3c96 0x3b0f 0x39ce 0x393b 0x3911 0x3c94 0x3b0e 0x39c4 0x3936 0x390c 0x3c92 0x3b0a 0x39bb 0x3930 0x3906 0x3c8f 0x3aff 0x39b6 0x392a 0x3901 0x3c8d 0x3af6 0x39b1 0x3924 0x38fb 0x3c8a 0x3af0 0x39ad 0x391f 0x38f6 0x3c87 0x3aea 0x39a9 0x391a 0x38f0 0x3c81 0x3ae4 0x39a6 0x3916 0x38eb 0x3c7a 0x3add 0x39a3 0x3913 0x38e6 0x3c78 0x3ad9 0x39a1 0x3910 0x38e2 0x3c77 0x3ad7 0x39a2 0x3910 0x38e2 0x3c76 0x3ad6 0x39a3 0x3911 0x38e5 0x3c77 0x3ad8 0x39a5 0x3912 0x38e7 0x3c7a 0x3adf 0x39ab 0x3916 0x38ea 0x3c7c 0x3ae5 0x39af 0x3919 0x38eb 0x3c7f 0x3ae8 0x39af 0x3917 0x38ea 0x3c80 0x3aeb 0x39ae 0x3913 0x38e8 0x3c7c 0x3aef 0x39b0 0x3915 0x38eb 0x3c5f 0x3ae6 0x39ae 0x3915 0x38ea 0x3c53 0x3add 0x39a5 0x390c 0x38e0 0x3c50 0x3ada 0x399f 0x3907 0x38db 0x3c4f 0x3ad9 0x399a 0x3900 0x38d3 0x3c4d 0x3ad9 0x3998 0x38f9 0x38cb 0x3c4b 0x3adb 0x3999 0x38fc 0x38cc 0x3c5b 0x3ae7 0x39a6 0x390a 0x38df 0x3c6f 0x3af5 0x39ac 0x3910 0x38e5 0x3c86 0x3b06 0x39b3 0x3915 0x38e9 0x3cab 0x3b1d 0x39be 0x391c 0x38ef 0x3cab 0x3b1d 0x39be 0x391c 0x38ef 0x3cab 0x3b1d 0x39be 0x391c 0x38ef>;
        qcom,lut-col-legend = <0x00 0x0a 0x19 0x28 0x32>;
    };

    qcom,pc-temp-z2-lut {
        qcom,lut-row-legend = <0x2710 0x2648 0x2580 0x24b8 0x23f0 0x2328 0x2260 0x2198 0x20d0 0x2008 0x1f40 0x1e78 0x1db0 0x1ce8 0x1c20 0x1b58 0x1a90 0x19c8 0x1900 0x1838 0x1770 0x16a8 0x15e0 0x1518 0x1450 0x1388 0x12c0 0x11f8 0x1130 0x1068 0xfa0 0xed8 0xe10 0xd48 0xc80 0xbb8 0xaf0 0xa28 0x960 0x898 0x7d0 0x708 0x640 0x578 0x4b0 0x3e8 0x384 0x320 0x2bc 0x258 0x1f4 0x190 0x12c 0xc8 0x64 0x00>;
        qcom,lut-data = <0x2322 0x244f 0x2868 0x2a08 0x294e 0x26a3 0x26a0 0x287c 0x2956 0x28bf 0x2712 0x27c6 0x28a7 0x2947 0x28ef 0x2748 0x27bc 0x28b4 0x291d 0x2918 0x276b 0x27a2 0x28a0 0x28f5 0x2918 0x2788 0x278e 0x2873 0x28c3 0x28db 0x2796 0x277b 0x2857 0x28ab 0x28b1 0x2794 0x276e 0x2843 0x28b1 0x28c0 0x278d 0x2765 0x2839 0x28bb 0x28d7 0x2786 0x275f 0x2846 0x28c7 0x28cb 0x277e 0x2761 0x2860 0x28d5 0x2884 0x2772 0x277f 0x2875 0x28de 0x285c 0x2755 0x2798 0x2889 0x28e3 0x2870 0x2722 0x2796 0x289a 0x28e6 0x288b 0x270d 0x278f 0x28a6 0x28da 0x2893 0x2746 0x2790 0x28b1 0x28bd 0x2892 0x278e 0x27b1 0x28c1 0x28b3 0x288e 0x2787 0x27e2 0x28d8 0x28c9 0x2889 0x2731 0x281c 0x28eb 0x28de 0x2885 0x26dc 0x2860 0x28fa 0x28e2 0x288f 0x263e 0x2874 0x2905 0x28e4 0x28ab 0x256c 0x285d 0x28fd 0x28ea 0x28c1 0x2556 0x2840 0x28db 0x28fd 0x28df 0x2645 0x282c 0x28c2 0x290a 0x28f4 0x2717 0x2817 0x28b6 0x28f2 0x28fe 0x272c 0x2811 0x28ae 0x28c7 0x2916 0x2733 0x281d 0x28b8 0x28ce 0x2928 0x2730 0x282b 0x28da 0x2923 0x2931 0x2692 0x2831 0x28e8 0x2957 0x292e 0x25e7 0x2834 0x28e2 0x291f 0x28ec 0x25df 0x2838 0x28da 0x28ce 0x2885 0x25ed 0x2840 0x28d1 0x28bf 0x2853 0x25f5 0x2849 0x28c5 0x28be 0x2832 0x2581 0x283c 0x28c3 0x28c0 0x2825 0x24df 0x2802 0x28d6 0x28df 0x283d 0x24d6 0x27e5 0x28f0 0x290e 0x2868 0x250a 0x2801 0x2905 0x2937 0x289a 0x252f 0x2832 0x291a 0x2963 0x28e1 0x2534 0x2865 0x292f 0x297e 0x2918 0x2536 0x28a3 0x2947 0x2992 0x2940 0x2530 0x28c0 0x2959 0x29a1 0x295a 0x250f 0x290c 0x2961 0x29a9 0x295a 0x24eb 0x294d 0x2967 0x29ae 0x2951 0x24cc 0x2904 0x296f 0x299a 0x2958 0x24a9 0x29f2 0x29a5 0x2992 0x2963 0x2491 0x2a2f 0x29e7 0x2995 0x2969 0x2498 0x2a5c 0x2a1a 0x29b3 0x295c 0x2492 0x2a3b 0x2a48 0x29b7 0x2953 0x248b 0x2b34 0x3588 0x2a21 0x299f 0x2492 0x2a20 0x2c22 0x2a76 0x2a88 0x247e 0x29c6 0x2b1c 0x29ee 0x28ec 0x246f 0x2917 0x2af0 0x295c 0x288d 0x2444 0x276e 0x2afe 0x2925 0x2852 0x241e 0x270e 0x2a5e 0x28ea 0x281b 0x241e 0x270e 0x2a5e 0x28ea 0x281b 0x241e 0x270e 0x2a5e 0x28ea 0x281b>;
        qcom,lut-col-legend = <0x00 0x0a 0x19 0x28 0x32>;
    };

    qcom,fcc1-temp-lut {
        qcom,lut-data = <0xd9a 0xdeb 0xe3b 0xe58 0xe60>;
        qcom,lut-col-legend = <0x00 0x0a 0x19 0x28 0x32>;
    };

    qcom,pc-temp-y5-lut {
        qcom,lut-row-legend = <0x2710 0x2648 0x2580 0x24b8 0x23f0 0x2328 0x2260 0x2198 0x20d0 0x2008 0x1f40 0x1e78 0x1db0 0x1ce8 0x1c20 0x1b58 0x1a90 0x19c8 0x1900 0x1838 0x1770 0x16a8 0x15e0 0x1518 0x1450 0x1388 0x12c0 0x11f8 0x1130 0x1068 0xfa0 0xed8 0xe10 0xd48 0xc80 0xbb8 0xaf0 0xa28 0x960 0x898 0x7d0 0x708 0x640 0x578 0x4b0 0x3e8 0x384 0x320 0x2bc 0x258 0x1f4 0x190 0x12c 0xc8 0x64 0x00>;
        qcom,lut-data = <0x2a40 0x2dd5 0x2ca6 0x39ce 0x3886 0x3fc5 0x2ae5 0x2d60 0x2d19 0x3bec 0x39ff 0x3f78 0x2bab 0x2d2d 0x2e01 0x3ce8 0x3afe 0x3f0b 0x2c6e 0x2d2e 0x2f0a 0x3d0b 0x3b95 0x3e97 0x2d0a 0x2d52 0x2fe4 0x3c9f 0x3bd6 0x3e38 0x2d5e 0x2d8b 0x303d 0x3beb 0x3bd4 0x3e08 0x2d70 0x2e33 0x3043 0x397d 0x3b66 0x3dfd 0x2d79 0x2ef0 0x3046 0x3652 0x3a91 0x3df4 0x2dab 0x2e9d 0x32cb 0x3501 0x3914 0x3d6d 0x2e45 0x2cd6 0x3c43 0x343e 0x3664 0x3b9a 0x2f75 0x2bf9 0x40de 0x3403 0x3541 0x3a64 0x397f 0x3317 0x3c24 0x36ae 0x3803 0x3b13 0x4584 0x3c26 0x368f 0x3a13 0x3b3a 0x3c2c 0x4317 0x3b2c 0x37cf 0x39ce 0x3aa1 0x3c00 0x3527 0x33ac 0x3dc0 0x3759 0x37dd 0x3af4 0x2e53 0x300c 0x4156 0x3629 0x36c1 0x39cd 0x2e78 0x30b4 0x4258 0x367d 0x37d3 0x37f8 0x2eaa 0x3179 0x432e 0x3732 0x38f0 0x367e 0x2ea3 0x317d 0x44f3 0x38c7 0x38dc 0x3691 0x2e88 0x313b 0x4773 0x3c6b 0x3871 0x3733 0x2e5a 0x30df 0x4783 0x4097 0x38f2 0x38a5 0x2dc7 0x302e 0x3cbb 0x466d 0x4167 0x4042 0x2d0a 0x2f43 0x327e 0x4b24 0x4921 0x46ed 0x2c6f 0x2e2e 0x31d5 0x4b78 0x4836 0x46aa 0x2bde 0x2ceb 0x31b6 0x4a58 0x453b 0x4588 0x2bb1 0x2c80 0x3138 0x49c7 0x432b 0x453e 0x2c0f 0x2c8e 0x2ebe 0x4853 0x40fe 0x45c6 0x2c70 0x2c9b 0x2cc2 0x463e 0x3fa5 0x4636 0x2c96 0x2c8d 0x2caf 0x43e9 0x4156 0x4379 0x2cde 0x2c69 0x2caa 0x40c1 0x4494 0x3e32 0x2ce0 0x2c68 0x2c9d 0x3f66 0x44f6 0x3cf6 0x2c91 0x2d0c 0x2c6f 0x405b 0x4248 0x3da5 0x2c52 0x2dd6 0x2c50 0x423d 0x4064 0x3eca 0x2c7b 0x2e4c 0x2cf3 0x454b 0x43dd 0x4214 0x2cf2 0x2eab 0x2e42 0x496d 0x4985 0x465a 0x2d67 0x2f00 0x2f36 0x4a21 0x4a55 0x46c2 0x2df0 0x2f4d 0x3009 0x4582 0x489d 0x4466 0x2e45 0x2f8c 0x306b 0x40c5 0x4681 0x4248 0x2df0 0x2fbd 0x3053 0x3f31 0x4394 0x4139 0x2d31 0x2fe1 0x302c 0x3e13 0x40ce 0x404e 0x2cca 0x2fcb 0x301e 0x3c37 0x41f0 0x3f6e 0x2c9c 0x2f34 0x3016 0x38bf 0x471e 0x3e95 0x2c77 0x2e94 0x303d 0x3836 0x4776 0x4152 0x2c59 0x2dd8 0x3071 0x3b31 0x4496 0x4642 0x2c5a 0x2d5f 0x2e89 0x3614 0x3bb6 0x4205 0x2cdb 0x2cc2 0x2e9f 0x33cc 0x3dc6 0x3b69 0x2d60 0x2d33 0x2e35 0x3cf0 0x3e78 0x3b61 0x2db2 0x2d0f 0x2f3d 0x3765 0x3f68 0x3e52 0x2ed4 0x2d51 0x2fd1 0x3d40 0x4128 0x3ea0 0x2f76 0x2df6 0x3157 0x3d16 0x3fd6 0x40a7 0x2fbb 0x2f5f 0x319f 0x38fa 0x4159 0x4659 0x2e3d 0x2e4b 0x2fcc 0x3a70 0x4791 0x437a 0x2ea2 0x2dc0 0x302f 0x4433 0x4a48 0x4af6 0x2cfd 0x2dc9 0x302c 0x492e 0x4e84 0x4cb3 0x2cfd 0x2dc9 0x302c 0x492e 0x4e84 0x4cb3 0x2cfd 0x2dc9 0x302c 0x492e 0x4e84 0x4cb3>;
        qcom,lut-col-legend = <0xfffffff6 0x00 0x0a 0x19 0x28 0x32>;
    };

    qcom,pc-temp-y1-lut {
        qcom,lut-row-legend = <0x2710 0x2648 0x2580 0x24b8 0x23f0 0x2328 0x2260 0x2198 0x20d0 0x2008 0x1f40 0x1e78 0x1db0 0x1ce8 0x1c20 0x1b58 0x1a90 0x19c8 0x1900 0x1838 0x1770 0x16a8 0x15e0 0x1518 0x1450 0x1388 0x12c0 0x11f8 0x1130 0x1068 0xfa0 0xed8 0xe10 0xd48 0xc80 0xbb8 0xaf0 0xa28 0x960 0x898 0x7d0 0x708 0x640 0x578 0x4b0 0x3e8 0x384 0x320 0x2bc 0x258 0x1f4 0x190 0x12c 0xc8 0x64 0x00>;
        qcom,lut-data = <0x1b50 0x182b 0x161b 0x14d1 0x1406 0x13c2 0x1b30 0x182b 0x1634 0x14d2 0x1411 0x13c9 0x1b22 0x182b 0x1645 0x14d3 0x1418 0x13cd 0x1b1e 0x182c 0x164e 0x14d3 0x141c 0x13ce 0x1b20 0x182d 0x1651 0x14d2 0x141e 0x13ce 0x1b22 0x1830 0x1651 0x14d2 0x141e 0x13cd 0x1b2e 0x1834 0x1648 0x14d2 0x141b 0x13c9 0x1b3c 0x1839 0x163c 0x14d1 0x1416 0x13c4 0x1b37 0x183d 0x163e 0x14cf 0x1414 0x13c3 0x1b2a 0x1847 0x1649 0x14ca 0x1413 0x13c2 0x1b21 0x184b 0x1651 0x14c7 0x1412 0x13c1 0x1b23 0x1846 0x164f 0x14c6 0x1410 0x13bf 0x1b28 0x1840 0x164b 0x14c6 0x140f 0x13bc 0x1b2f 0x183c 0x164f 0x14c9 0x140f 0x13bc 0x1b44 0x183b 0x1657 0x14d2 0x1410 0x13bb 0x1b4d 0x183b 0x165c 0x14d7 0x1410 0x13bb 0x1b44 0x183c 0x165b 0x14da 0x1410 0x13bc 0x1b3a 0x183d 0x1659 0x14db 0x1410 0x13bd 0x1b36 0x1844 0x1658 0x14dd 0x1410 0x13bd 0x1b34 0x1856 0x1655 0x14df 0x140f 0x13bd 0x1b34 0x185f 0x1656 0x14df 0x140f 0x13bd 0x1b43 0x185d 0x165e 0x14da 0x1411 0x13bd 0x1b54 0x1859 0x1665 0x14d5 0x1413 0x13be 0x1b58 0x1855 0x1664 0x14d6 0x1414 0x13bf 0x1b57 0x184f 0x165f 0x14db 0x1414 0x13c0 0x1b53 0x184d 0x165d 0x14de 0x1416 0x13c2 0x1b48 0x1853 0x165f 0x14e0 0x1417 0x13c3 0x1b3e 0x185b 0x1661 0x14e1 0x1419 0x13c4 0x1b48 0x185e 0x165f 0x14e0 0x141b 0x13c6 0x1b61 0x1861 0x165c 0x14df 0x141d 0x13c9 0x1b66 0x1863 0x165a 0x14de 0x141f 0x13cc 0x1b3f 0x1865 0x165c 0x14e2 0x1422 0x13cf 0x1b1a 0x1866 0x165e 0x14e5 0x1424 0x13d2 0x1b26 0x1860 0x1660 0x14e6 0x1427 0x13d4 0x1b44 0x1854 0x1663 0x14e5 0x142b 0x13d6 0x1b4e 0x184f 0x1662 0x14e6 0x142c 0x13d8 0x1b42 0x1852 0x165d 0x14e7 0x142d 0x13da 0x1b38 0x1855 0x1659 0x14e8 0x142e 0x13dc 0x1b3e 0x1855 0x165b 0x14e7 0x142f 0x13de 0x1b4b 0x1853 0x165f 0x14e6 0x1430 0x13df 0x1b50 0x1850 0x1662 0x14e6 0x1431 0x13e1 0x1b55 0x1849 0x1664 0x14ea 0x1431 0x13e3 0x1b41 0x184a 0x1660 0x14eb 0x1434 0x13e4 0x1b0c 0x1856 0x1659 0x14e9 0x1439 0x13e5 0x1b42 0x185b 0x1660 0x14f4 0x1439 0x13e7 0x1b5e 0x185c 0x1675 0x14ee 0x143d 0x13ef 0x1b5a 0x1875 0x1662 0x14eb 0x143b 0x13ed 0x1b5f 0x1871 0x1669 0x14ef 0x143f 0x13ed 0x1b5d 0x1887 0x1664 0x14f0 0x143e 0x13ec 0x1b6a 0x187d 0x1665 0x14fa 0x143f 0x13eb 0x1b86 0x188f 0x1671 0x14f4 0x143f 0x13f0 0x1b6b 0x1899 0x167d 0x14f2 0x1442 0x13f5 0x1bb2 0x189c 0x1691 0x1507 0x144d 0x13fc 0x1c04 0x18b9 0x16ab 0x1519 0x1456 0x1405 0x1c04 0x18b9 0x16ab 0x1519 0x1456 0x1405 0x1c04 0x18b9 0x16ab 0x1519 0x1456 0x1405>;
        qcom,lut-col-legend = <0xfffffff6 0x00 0x0a 0x19 0x28 0x32>;
    };

    qcom,pc-temp-z5-lut {
        qcom,lut-row-legend = <0x2710 0x2648 0x2580 0x24b8 0x23f0 0x2328 0x2260 0x2198 0x20d0 0x2008 0x1f40 0x1e78 0x1db0 0x1ce8 0x1c20 0x1b58 0x1a90 0x19c8 0x1900 0x1838 0x1770 0x16a8 0x15e0 0x1518 0x1450 0x1388 0x12c0 0x11f8 0x1130 0x1068 0xfa0 0xed8 0xe10 0xd48 0xc80 0xbb8 0xaf0 0xa28 0x960 0x898 0x7d0 0x708 0x640 0x578 0x4b0 0x3e8 0x384 0x320 0x2bc 0x258 0x1f4 0x190 0x12c 0xc8 0x64 0x00>;
        qcom,lut-data = <0x2b8a 0x2b63 0x31f4 0x3afc 0x363d 0x3121 0x3362 0x38c3 0x3fa3 0x3e67 0x3315 0x3885 0x3d2c 0x41f1 0x423b 0x3433 0x3a9f 0x40ba 0x437b 0x4707 0x348e 0x3c00 0x43af 0x4533 0x4969 0x34b1 0x3d5d 0x464a 0x4715 0x4a67 0x34cd 0x3ecb 0x49df 0x4942 0x4b8d 0x34f8 0x3fd6 0x4f57 0x4cbf 0x4e7b 0x3527 0x406d 0x530c 0x4fd0 0x51af 0x3532 0x40d6 0x5401 0x500c 0x5181 0x3519 0x408c 0x5491 0x4fa4 0x4e66 0x3517 0x3d52 0x544d 0x4f92 0x4cbc 0x35a0 0x3a9c 0x5266 0x5311 0x4fa4 0x3734 0x40a4 0x5132 0x56e6 0x5381 0x39b4 0x4dad 0x5b77 0x56b3 0x5459 0x41ee 0x5160 0x6a93 0x556a 0x549a 0x4abc 0x4c0b 0x6993 0x5559 0x5535 0x48e0 0x44b1 0x59ee 0x5b48 0x58de 0x3ac9 0x3d82 0x512b 0x629b 0x5e08 0x302e 0x35f7 0x54d0 0x680f 0x633a 0x2d50 0x3442 0x5d61 0x6e73 0x68d3 0x2b50 0x3e5b 0x7460 0x7357 0x6a40 0x2c21 0x504d 0xa9a9 0x785d 0x6802 0x35e9 0x7470 0xc1a2 0x7b28 0x63d3 0x4023 0xaf10 0x9ec9 0x68fb 0x55ce 0x4432 0xc43e 0x7086 0x493c 0x4061 0x46e8 0xb6fe 0x5ed0 0x43a1 0x3d46 0x4905 0xa33b 0x53fa 0x49e6 0x4acf 0x47e1 0x930b 0x510d 0x51cf 0x589d 0x45a2 0x8318 0x57f8 0x5a20 0x60a1 0x454d 0x7632 0x6251 0x63c3 0x66f2 0x44d2 0x6cae 0x6c4a 0x6e8f 0x6b41 0x43db 0x645c 0x7836 0x7b84 0x6ee4 0x3a5f 0x598d 0x7dcd 0x8447 0x7082 0x2d95 0x4a6c 0x7fc1 0x8977 0x6ec5 0x2b0b 0x420a 0x8113 0x8c93 0x6c8e 0x2b09 0x3802 0x820f 0x8af1 0x6de3 0x2b08 0x2d31 0x82c9 0x83f3 0x7204 0x2b12 0x2be3 0x827f 0x7c0d 0x7348 0x2b2d 0x2c1a 0x7d3a 0x71c3 0x693c 0x2b49 0x2c37 0x7668 0x6718 0x5d8e 0x2b65 0x2c20 0x70ea 0x5ef2 0x593f 0x2b8b 0x2c0d 0x6b78 0x5838 0x566e 0x2bbf 0x2c2b 0x634d 0x52be 0x5756 0x2cdf 0x2ced 0x5fa2 0x5339 0x568e 0x2d20 0x2d12 0x5db1 0x4de6 0x4b88 0x2d07 0x2cfb 0x3dd5 0x4a97 0x4a9a 0x2d06 0x2cff 0x3d1f 0x53c9 0x47c5 0x2d02 0x2cdc 0x32a8 0x45bc 0x4a2d 0x2d00 0x2cff 0x3301 0x4470 0x3ce8 0x2d37 0x2d15 0x35e3 0x4267 0x5c58 0x2cfc 0x2cdc 0x34b4 0x49ab 0x5a8d 0x2ca9 0x2c85 0x31b3 0x44d7 0x5309 0x2c2f 0x2c2f 0x3174 0x45f3 0x4f40 0x2c2f 0x2c2f 0x3174 0x45f3 0x4f40 0x2c2f 0x2c2f 0x3174 0x45f3 0x4f40>;
        qcom,lut-col-legend = <0x00 0x0a 0x19 0x28 0x32>;
    };

    qcom,pc-temp-z1-lut {
        qcom,lut-row-legend = <0x2710 0x2648 0x2580 0x24b8 0x23f0 0x2328 0x2260 0x2198 0x20d0 0x2008 0x1f40 0x1e78 0x1db0 0x1ce8 0x1c20 0x1b58 0x1a90 0x19c8 0x1900 0x1838 0x1770 0x16a8 0x15e0 0x1518 0x1450 0x1388 0x12c0 0x11f8 0x1130 0x1068 0xfa0 0xed8 0xe10 0xd48 0xc80 0xbb8 0xaf0 0xa28 0x960 0x898 0x7d0 0x708 0x640 0x578 0x4b0 0x3e8 0x384 0x320 0x2bc 0x258 0x1f4 0x190 0x12c 0xc8 0x64 0x00>;
        qcom,lut-data = <0x34a5 0x30ea 0x2e26 0x2d04 0x2c6f 0x34cd 0x30f9 0x2e52 0x2d07 0x2c7f 0x34d2 0x30ff 0x2e45 0x2d00 0x2c72 0x34d9 0x30f5 0x2e36 0x2cf5 0x2c67 0x34da 0x30e4 0x2e2c 0x2ceb 0x2c5f 0x34d6 0x30de 0x2e22 0x2ce0 0x2c58 0x34cf 0x30dd 0x2e1a 0x2cd7 0x2c53 0x34c0 0x30de 0x2e0f 0x2cd2 0x2c4f 0x34ab 0x30df 0x2e08 0x2cce 0x2c4c 0x349f 0x30e1 0x2e0a 0x2ccc 0x2c4a 0x349e 0x30de 0x2e0f 0x2ccc 0x2c49 0x349b 0x30d0 0x2e15 0x2ccb 0x2c48 0x3480 0x30bf 0x2e1e 0x2ccb 0x2c49 0x3448 0x30ae 0x2e22 0x2ccb 0x2c49 0x3421 0x309b 0x2e19 0x2ccc 0x2c4a 0x3408 0x3097 0x2e0b 0x2ccf 0x2c4c 0x33f5 0x309d 0x2e0b 0x2cd0 0x2c4d 0x33f6 0x30a5 0x2e15 0x2cd0 0x2c4f 0x3405 0x30ad 0x2e1c 0x2cd0 0x2c51 0x3413 0x30b4 0x2e1f 0x2cd3 0x2c54 0x341f 0x30be 0x2e22 0x2cd7 0x2c56 0x3429 0x30cb 0x2e23 0x2cd9 0x2c58 0x3432 0x30d7 0x2e22 0x2cd9 0x2c59 0x3449 0x30dd 0x2e22 0x2cda 0x2c5a 0x345b 0x30e2 0x2e24 0x2cdd 0x2c5d 0x345c 0x30e3 0x2e28 0x2ce2 0x2c61 0x3457 0x30e4 0x2e2d 0x2ce5 0x2c65 0x3451 0x30e5 0x2e34 0x2ce8 0x2c69 0x344c 0x30e3 0x2e39 0x2ceb 0x2c6d 0x3449 0x30df 0x2e3d 0x2cf2 0x2c71 0x344d 0x30df 0x2e3f 0x2cfb 0x2c76 0x345e 0x30e5 0x2e3e 0x2cfe 0x2c7a 0x3467 0x30ee 0x2e3c 0x2d00 0x2c7e 0x346c 0x30f7 0x2e3c 0x2d02 0x2c82 0x3475 0x3103 0x2e46 0x2d06 0x2c87 0x347e 0x310e 0x2e4f 0x2d0c 0x2c8b 0x348f 0x311a 0x2e4f 0x2d13 0x2c90 0x349b 0x3124 0x2e4e 0x2d1b 0x2c94 0x349a 0x3127 0x2e4f 0x2d20 0x2c99 0x3497 0x3124 0x2e58 0x2d22 0x2c9e 0x349a 0x3124 0x2e60 0x2d24 0x2ca3 0x34b6 0x312c 0x2e62 0x2d27 0x2ca7 0x34c2 0x3132 0x2e63 0x2d29 0x2cab 0x34b7 0x312d 0x2e5e 0x2d2a 0x2cae 0x34c5 0x312e 0x2e62 0x2d2c 0x2cb2 0x347d 0x3126 0x2e66 0x2d32 0x2cb0 0x348b 0x312c 0x2e67 0x2d33 0x2cb1 0x348b 0x312b 0x2e65 0x2d38 0x2cb6 0x3475 0x3120 0x2e66 0x2d35 0x2cba 0x349b 0x3133 0x2e6a 0x2d34 0x2cbd 0x34a8 0x313d 0x2e68 0x2d3c 0x2cc2 0x34aa 0x3152 0x2e77 0x2d3f 0x2cc6 0x34c7 0x317f 0x2e89 0x2d4e 0x2ccf 0x34f5 0x318f 0x2e9e 0x2d63 0x2cdb 0x34f5 0x318f 0x2e9e 0x2d63 0x2cdb 0x34f5 0x318f 0x2e9e 0x2d63 0x2cdb>;
        qcom,lut-col-legend = <0x00 0x0a 0x19 0x28 0x32>;
    };
};
